VERSION ""

NS_ :

BS_:

BU_: WCM4 WCM3 WCM2 WCM VPM VLM VKM VICM VECM VDM VCU_RTOS_ETH VCU_ENTRY_ETH VCU_AGVM_ETH VCU UVM UPM TIM TEST_TOOL_1 TCP_ETH TCP TCM TCCM SRR_SRR_ETH SRR_SRR SRR_SLR_ETH SRR_SLR SRR_RR SRR_RF_ETH SRR_RF SRR_LR_CR SRR_LF_ETH SRR_LF SIB SDM SCL SBZA_R SBZA_L SBM SAM_RR SAM_RF SAM_LR SAM_LF SAM_BH SADS RadioLow_ETH RadioLow RSI_RTOS_ETH RSI RDCM PTM PLCM PFCM PDR_ETH PDR PCM PA ODS2 ODS NVM MTCM_R MTCM_L MSM_RR MSM_P MSM_LR MSM_D MSB2 MSB1 MRCM_R MRCM_L MFC LRR_RR_ETH LRR_LR_ETH LRR_CF_ETH LRR LRL_CF_ETH LIB_48V LIB1 IPC_INT IPC_GP IPC ICS_Info ICCM HVAC_FP_R HVAC_FP_F HUD_CAN HDLM FPI_RTOS_ETH FPI FOPM FCM_LC FCM EPSb EPS_1 EPSRAb EPSRAa EPS EOCM_HC_Superset EOCM_HCP2 EOCM ELM ECP_X1 ECP_S2 ECP_S ECP_MC ECP_H3 ECP_H2 ECP_H1 ECP_E ECM EBCM DMS DEFC DCM CSM_ETH CSM_AV CSM CGM_OTA_ETH CGM BSM_MH BSM_HEV BSM BCM ARS ARB APA AOS AMP ALC AHS AHL_AFL ADIMb ADIMa ACP2_MCU
VAL_TABLE_ EngEmsRltMlfIndRq 0 "Continuous Indication" 1 "No Indication" 2 "Flashing 1 Hertz Indication" 3 "Flashing 2 Hertz Indication" 4 "Flashing 0.5 Hertz Indication" ;
VAL_TABLE_ VSADP_VehSpdAvgDrvnSrcAuth 0 "Transmission Output Speed" 1 "Wheel Speed" ;
VAL_TABLE_ VSADP_VehSpdAvgDrvnAuth_Inv 0 "FALSE" 1 "TRUE" ;
VAL_TABLE_ VPMGI1P_ITAux2CamConctStsAuth 0 "Unknown" 1 "Not Connected" 2 "Connected" ;
VAL_TABLE_ VPMGI1P_ITAux1CamConctStsAuth 0 "Unknown" 1 "Not Connected" 2 "Connected" ;

BO_ 925 APASts_PCSM_PDU: 8 CGM
 SG_ APASts_PCSM : 0|64@1+ (1,0) [0|1.84467e+019] "" VKM

BO_ 525 APASts_Prtctd_PDU: 8 CGM
 SG_ APASP_MAC : 7|27@0+ (1,0) [0|1.34218e+008] "" VKM
 SG_ APASP_FCnt : 28|5@0+ (1,0) [0|31] "" VKM
 SG_ APASP_APAStopDistAuth : 32|14@0- (1,0) [-8192|8191] "cm" VKM
 SG_ APASP_APAMaxVelAuth : 39|7@0+ (0.1,0) [0|12.7] "km/h" VKM
 SG_ APASP_APAStsAuth : 50|3@0+ (1,0) [0|7] "" VKM
 SG_ APASP_ARC : 59|2@0+ (1,0) [0|3] "" VKM
 SG_ APASP_APATransRngReqAuth : 62|3@0+ (1,0) [0|4] "" VKM
 SG_ APASP_APATransRngActvnReqdAuth : 63|1@0+ (1,0) [0|1] "" VKM

BO_ 1393 ActvSftyOprtrCrtclNtfns_PCSM_PDU: 8 CGM
 SG_ ActvSftyOprtrCrtclNtfns_PCSM : 0|64@1+ (1,0) [0|1.84467e+019] "" IPC,IPC_INT,VCU

BO_ 1325 ActvSftyOprtrCrtclNtfns_Prtctd_P: 8 CGM
 SG_ ASOCNP_MAC : 7|27@0+ (1,0) [0|1.34218e+008] "" IPC,IPC_INT,VCU
 SG_ ASOCNP_FCnt : 28|5@0+ (1,0) [0|31] "" IPC,IPC_INT,VCU
 SG_ HndsOnLnCntrAsstWrnIndReq : 32|4@0+ (1,0) [0|6] "" IPC,IPC_INT,VCU
 SG_ SuprRmtPrkPwrModeReq : 34|2@0+ (1,0) [0|2] "" IPC,IPC_INT,VCU
 SG_ SuprRmtPrkDrLckReq : 36|2@0+ (1,0) [0|2] "" IPC,IPC_INT,VCU
 SG_ ASOCNP_ARC : 38|2@0+ (1,0) [0|3] "" IPC,IPC_INT,VCU
 SG_ ASOCNP_LKATakeStrgIndOnAuth : 39|1@0+ (1,0) [0|1] "" TCP,CSM,CSM_AV,IPC,IPC_INT,VCU
 SG_ ASOCNP_Filler : 44|21@0+ (1,0) [0|2.09715e+006] "" IPC,IPC_INT,VCU

BO_ 618 BdyGenInfo2_Prtctd_PDU: 8 CGM
 SG_ BGI2P_WshFldLvlIndOnAuth : 36|1@0+ (1,0) [0|1] "" TCP,CSM,CSM_AV,IPC,IPC_INT,VCU
 SG_ BGI2P_ServWprSysDrvIndOnAuth : 38|1@0+ (1,0) [0|1] "" IPC,IPC_INT,VCU

BO_ 1405 BkupSysPwrMode_PCSM_PDU: 8 CGM
 SG_ BkupSysPwrMode_PCSM : 0|64@1+ (1,0) [0|1.84467e+019] "" TCP,VKM,IPC,IPC_INT,VCU

BO_ 880 BkupSysPwrMode_Prtctd_PDU: 6 CGM
 SG_ BSPMP_MAC : 7|27@0+ (1,0) [0|1.34218e+008] "" TCP,VKM,IPC,IPC_INT,VCU
 SG_ BSPMP_FCnt : 28|5@0+ (1,0) [0|31] "" TCP,VKM,IPC,IPC_INT,VCU
 SG_ BSPMP_PV : 35|4@0+ (1,0) [0|15] "" HVAC_FP_R,TCP,VKM,IPC,IPC_INT,VCU
 SG_ BSPMP_BkupSysPwrModeAuth_Inv : 36|1@0+ (1,0) [0|1] "" AMP,FPI,HVAC_FP_F,HVAC_FP_R,ICS_Info,PDR,MFC,PLCM,RSI,RadioLow,TCP,VKM,CSM,CSM_AV,IPC,IPC_INT,VCU,WCM,WCM2,WCM3,WCM4
 SG_ BSPMP_BkupSysPwrModeAuth : 39|3@0+ (1,0) [0|4] "" AMP,FPI,HVAC_FP_F,HVAC_FP_R,ICS_Info,PDR,MFC,PLCM,RSI,RadioLow,TCP,VKM,CSM,CSM_AV,IPC,IPC_INT,VCU,WCM,WCM2,WCM3,WCM4
 SG_ BSPMP_ARC : 42|2@0+ (1,0) [0|3] "" HVAC_FP_R,TCP,VKM,IPC,IPC_INT,VCU
 SG_ BSPMP_SecRunCrnkCmdActvAuth_Inv : 43|1@0+ (1,0) [0|1] "" TCP,VKM,IPC,IPC_INT,VCU
 SG_ BSPMP_SecRunCrnkCmdActvAuth : 44|1@0+ (1,0) [0|1] "" TCP,VKM,IPC,IPC_INT,VCU
 SG_ BSPMP_SecPwrModePBActvAuth_Inv : 45|1@0+ (1,0) [0|1] "" TCP,VKM,IPC,IPC_INT,VCU
 SG_ BSPMP_SecPwrModePBActvAuth : 46|1@0+ (1,0) [0|1] "" TCP,VKM,IPC,IPC_INT,VCU
 SG_ BSPMP_RmtProgmActvAuth : 47|1@0+ (1,0) [0|1] "" AMP,FPI,HVAC_FP_F,HVAC_FP_R,ICS_Info,PDR,MFC,PLCM,RSI,RadioLow,TCP,VKM,CSM,CSM_AV,IPC,IPC_INT,VCU,WCM,WCM2,WCM3,WCM4

BO_ 1366 BrkSysDispInfo_PCSM_PDU: 8 CGM
 SG_ BrkSysDispInfo_PCSM : 0|64@1+ (1,0) [0|1.84467e+019] "" IPC,IPC_INT,VCU

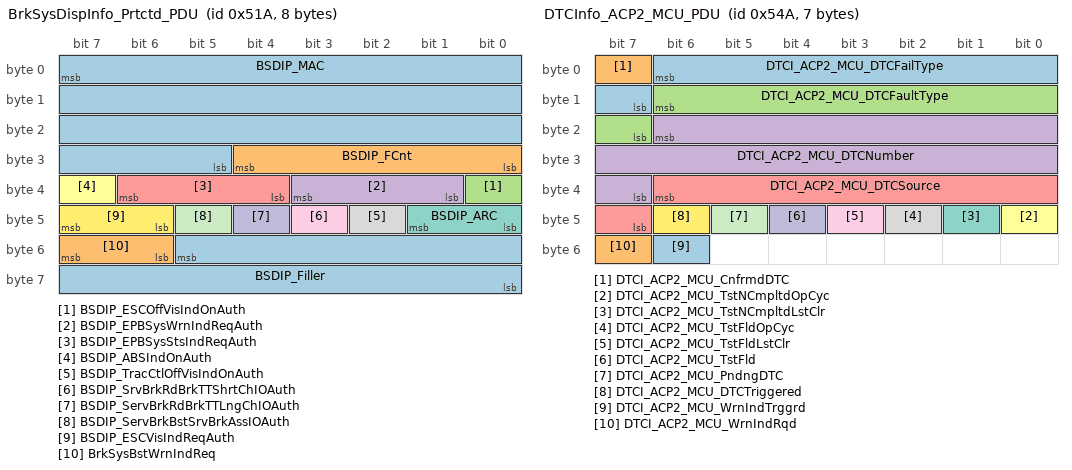
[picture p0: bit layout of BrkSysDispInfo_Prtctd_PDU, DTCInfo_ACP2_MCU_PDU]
BO_ 1306 BrkSysDispInfo_Prtctd_PDU: 8 CGM
 SG_ BSDIP_MAC : 7|27@0+ (1,0) [0|1.34218e+008] "" IPC,IPC_INT,VCU
 SG_ BSDIP_FCnt : 28|5@0+ (1,0) [0|31] "" IPC,IPC_INT,VCU
 SG_ BSDIP_ESCOffVisIndOnAuth : 32|1@0+ (1,0) [0|1] "" IPC,IPC_INT,VCU
 SG_ BSDIP_EPBSysWrnIndReqAuth : 35|3@0+ (1,0) [0|5] "" CSM,CSM_AV,IPC,IPC_INT,VCU
 SG_ BSDIP_EPBSysStsIndReqAuth : 38|3@0+ (1,0) [0|5] "" CSM,CSM_AV,IPC,IPC_INT,VCU
 SG_ BSDIP_ABSIndOnAuth : 39|1@0+ (1,0) [0|1] "" TCP,CSM,CSM_AV,IPC,IPC_INT,VCU
 SG_ BSDIP_ARC : 41|2@0+ (1,0) [0|3] "" IPC,IPC_INT,VCU
 SG_ BSDIP_TracCtlOffVisIndOnAuth : 42|1@0+ (1,0) [0|1] "" TCP,IPC,IPC_INT,VCU
 SG_ BSDIP_SrvBrkRdBrkTTShrtChIOAuth : 43|1@0+ (1,0) [0|1] "" TCP,IPC,IPC_INT,VCU
 SG_ BSDIP_ServBrkRdBrkTTLngChIOAuth : 44|1@0+ (1,0) [0|1] "" TCP,IPC,IPC_INT,VCU
 SG_ BSDIP_ServBrkBstSrvBrkAssIOAuth : 45|1@0+ (1,0) [0|1] "" TCP,IPC,IPC_INT,VCU
 SG_ BSDIP_ESCVisIndReqAuth : 47|2@0+ (1,0) [0|2] "" TCP,IPC,IPC_INT,VCU
 SG_ BSDIP_Filler : 53|14@0+ (1,0) [0|16383] "" IPC,IPC_INT,VCU
 SG_ BrkSysBstWrnIndReq : 55|2@0+ (1,0) [0|3] "" IPC,IPC_INT,VCU

BO_ 327 CGM_NM_PDU_On_CAN_5_Cluster: 8 CGM
 SG_ ISignal_CGM_CAN_5_Cluster : 23|48@0+ (1,0) [0|281474976710655] "" AMP,FPI,HVAC_FP_F,HVAC_FP_R,ICS_Info,PDR,MFC,PLCM,RSI,RadioLow,TCP,VKM,CSM,CSM_AV,IPC,IPC_INT,VCU,WCM,WCM2,WCM3,WCM4

BO_ 384 CSM_AV_NM_PDU_On_CAN_5_Cluster: 8 CSM_AV
 SG_ ISignal_CSM_AV_CAN_5_Cluster : 23|48@0+ (1,0) [0|281474976710655] "" AMP,CGM,FPI,HVAC_FP_F,HVAC_FP_R,ICS_Info,PDR,MFC,PLCM,RSI,RadioLow,TCP,VKM,CSM,IPC,IPC_INT,VCU,WCM,WCM2,WCM3,WCM4

BO_ 1446 ChmReqInfo_PDU: 8 IPC
 SG_ CRI_ChmPrdcrReq : 7|12@0+ (1,0) [0|4095] "msec" AMP,RadioLow,CSM,CSM_AV
 SG_ CRI_CS : 50|11@0+ (1,0) [0|2047] "" AMP,RadioLow,CSM,CSM_AV
 SG_ CRI_ARC : 55|2@0+ (1,0) [0|3] "" AMP,RadioLow,CSM,CSM_AV

BO_ 1354 DTCInfo_ACP2_MCU_PDU: 7 CGM
 SG_ DTCI_ACP2_MCU_DTCFailType : 6|8@0+ (1,0) [0|255] "" TCP
 SG_ DTCI_ACP2_MCU_CnfrmdDTC : 7|1@0+ (1,0) [0|1] "" TCP
 SG_ DTCI_ACP2_MCU_DTCFaultType : 14|8@0+ (1,0) [0|3] "" TCP
 SG_ DTCI_ACP2_MCU_DTCNumber : 22|16@0+ (1,0) [0|65535] "" TCP
 SG_ DTCI_ACP2_MCU_DTCSource : 38|8@0+ (1,0) [0|255] "" TCP
 SG_ DTCI_ACP2_MCU_TstNCmpltdOpCyc : 40|1@0+ (1,0) [0|1] "" TCP
 SG_ DTCI_ACP2_MCU_TstNCmpltdLstClr : 41|1@0+ (1,0) [0|1] "" TCP
 SG_ DTCI_ACP2_MCU_TstFldOpCyc : 42|1@0+ (1,0) [0|1] "" TCP
 SG_ DTCI_ACP2_MCU_TstFldLstClr : 43|1@0+ (1,0) [0|1] "" TCP
 SG_ DTCI_ACP2_MCU_TstFld : 44|1@0+ (1,0) [0|1] "" TCP
 SG_ DTCI_ACP2_MCU_PndngDTC : 45|1@0+ (1,0) [0|1] "" TCP
 SG_ DTCI_ACP2_MCU_DTCTriggered : 46|1@0+ (1,0) [0|1] "" TCP
 SG_ DTCI_ACP2_MCU_WrnIndTrggrd : 54|1@0+ (1,0) [0|1] "" TCP
 SG_ DTCI_ACP2_MCU_WrnIndRqd : 55|1@0+ (1,0) [0|1] "" TCP

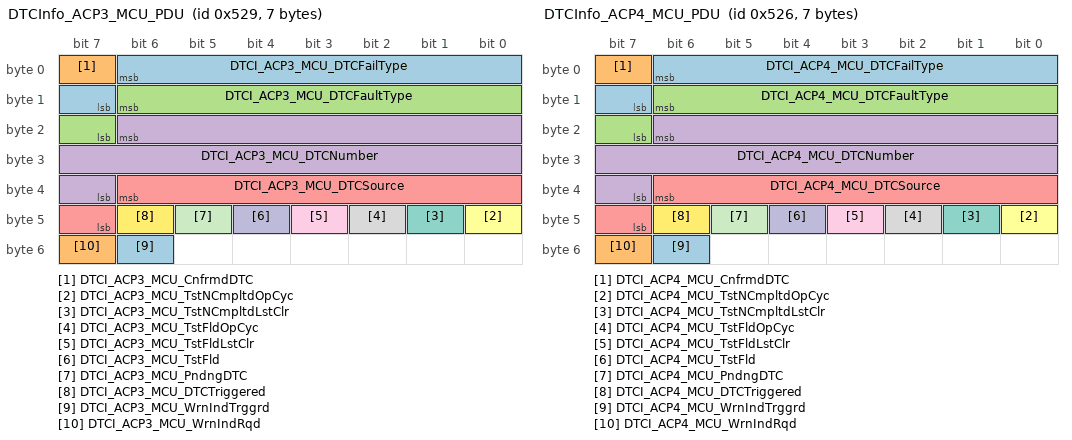
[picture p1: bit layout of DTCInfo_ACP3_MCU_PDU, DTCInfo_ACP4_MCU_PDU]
BO_ 1321 DTCInfo_ACP3_MCU_PDU: 7 CGM
 SG_ DTCI_ACP3_MCU_DTCFailType : 6|8@0+ (1,0) [0|255] "" TCP
 SG_ DTCI_ACP3_MCU_CnfrmdDTC : 7|1@0+ (1,0) [0|1] "" TCP
 SG_ DTCI_ACP3_MCU_DTCFaultType : 14|8@0+ (1,0) [0|3] "" TCP
 SG_ DTCI_ACP3_MCU_DTCNumber : 22|16@0+ (1,0) [0|65535] "" TCP
 SG_ DTCI_ACP3_MCU_DTCSource : 38|8@0+ (1,0) [0|255] "" TCP
 SG_ DTCI_ACP3_MCU_TstNCmpltdOpCyc : 40|1@0+ (1,0) [0|1] "" TCP
 SG_ DTCI_ACP3_MCU_TstNCmpltdLstClr : 41|1@0+ (1,0) [0|1] "" TCP
 SG_ DTCI_ACP3_MCU_TstFldOpCyc : 42|1@0+ (1,0) [0|1] "" TCP
 SG_ DTCI_ACP3_MCU_TstFldLstClr : 43|1@0+ (1,0) [0|1] "" TCP
 SG_ DTCI_ACP3_MCU_TstFld : 44|1@0+ (1,0) [0|1] "" TCP
 SG_ DTCI_ACP3_MCU_PndngDTC : 45|1@0+ (1,0) [0|1] "" TCP
 SG_ DTCI_ACP3_MCU_DTCTriggered : 46|1@0+ (1,0) [0|1] "" TCP
 SG_ DTCI_ACP3_MCU_WrnIndTrggrd : 54|1@0+ (1,0) [0|1] "" TCP
 SG_ DTCI_ACP3_MCU_WrnIndRqd : 55|1@0+ (1,0) [0|1] "" TCP

BO_ 1318 DTCInfo_ACP4_MCU_PDU: 7 CGM
 SG_ DTCI_ACP4_MCU_DTCFailType : 6|8@0+ (1,0) [0|255] "" TCP
 SG_ DTCI_ACP4_MCU_CnfrmdDTC : 7|1@0+ (1,0) [0|1] "" TCP
 SG_ DTCI_ACP4_MCU_DTCFaultType : 14|8@0+ (1,0) [0|3] "" TCP
 SG_ DTCI_ACP4_MCU_DTCNumber : 22|16@0+ (1,0) [0|65535] "" TCP
 SG_ DTCI_ACP4_MCU_DTCSource : 38|8@0+ (1,0) [0|255] "" TCP
 SG_ DTCI_ACP4_MCU_TstNCmpltdOpCyc : 40|1@0+ (1,0) [0|1] "" TCP
 SG_ DTCI_ACP4_MCU_TstNCmpltdLstClr : 41|1@0+ (1,0) [0|1] "" TCP
 SG_ DTCI_ACP4_MCU_TstFldOpCyc : 42|1@0+ (1,0) [0|1] "" TCP
 SG_ DTCI_ACP4_MCU_TstFldLstClr : 43|1@0+ (1,0) [0|1] "" TCP
 SG_ DTCI_ACP4_MCU_TstFld : 44|1@0+ (1,0) [0|1] "" TCP
 SG_ DTCI_ACP4_MCU_PndngDTC : 45|1@0+ (1,0) [0|1] "" TCP
 SG_ DTCI_ACP4_MCU_DTCTriggered : 46|1@0+ (1,0) [0|1] "" TCP
 SG_ DTCI_ACP4_MCU_WrnIndTrggrd : 54|1@0+ (1,0) [0|1] "" TCP
 SG_ DTCI_ACP4_MCU_WrnIndRqd : 55|1@0+ (1,0) [0|1] "" TCP

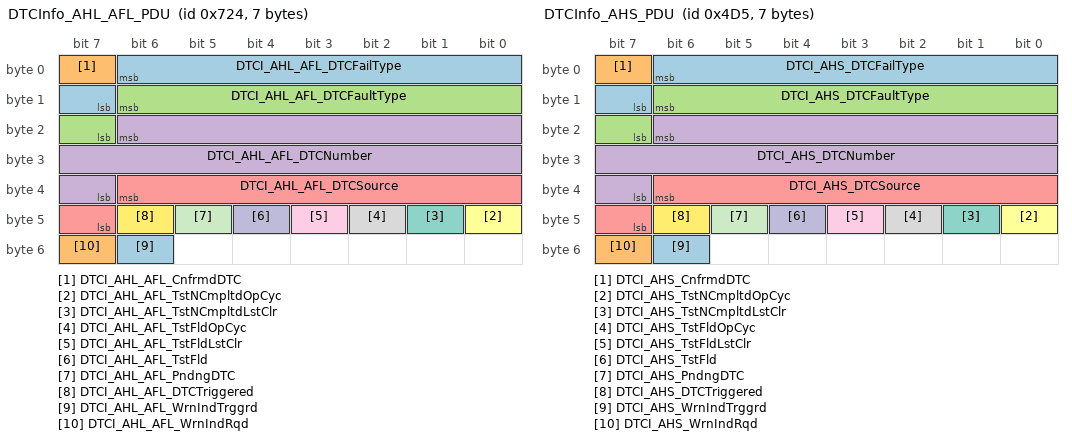
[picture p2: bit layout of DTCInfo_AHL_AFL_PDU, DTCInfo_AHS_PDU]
BO_ 1828 DTCInfo_AHL_AFL_PDU: 7 CGM
 SG_ DTCI_AHL_AFL_DTCFailType : 6|8@0+ (1,0) [0|255] "" TCP,CSM
 SG_ DTCI_AHL_AFL_CnfrmdDTC : 7|1@0+ (1,0) [0|1] "" TCP,CSM
 SG_ DTCI_AHL_AFL_DTCFaultType : 14|8@0+ (1,0) [0|3] "" TCP,CSM
 SG_ DTCI_AHL_AFL_DTCNumber : 22|16@0+ (1,0) [0|65535] "" TCP,CSM
 SG_ DTCI_AHL_AFL_DTCSource : 38|8@0+ (1,0) [0|255] "" TCP,CSM
 SG_ DTCI_AHL_AFL_TstNCmpltdOpCyc : 40|1@0+ (1,0) [0|1] "" TCP,CSM
 SG_ DTCI_AHL_AFL_TstNCmpltdLstClr : 41|1@0+ (1,0) [0|1] "" TCP,CSM
 SG_ DTCI_AHL_AFL_TstFldOpCyc : 42|1@0+ (1,0) [0|1] "" TCP,CSM
 SG_ DTCI_AHL_AFL_TstFldLstClr : 43|1@0+ (1,0) [0|1] "" TCP,CSM
 SG_ DTCI_AHL_AFL_TstFld : 44|1@0+ (1,0) [0|1] "" TCP,CSM
 SG_ DTCI_AHL_AFL_PndngDTC : 45|1@0+ (1,0) [0|1] "" TCP,CSM
 SG_ DTCI_AHL_AFL_DTCTriggered : 46|1@0+ (1,0) [0|1] "" TCP,CSM
 SG_ DTCI_AHL_AFL_WrnIndTrggrd : 54|1@0+ (1,0) [0|1] "" TCP,CSM
 SG_ DTCI_AHL_AFL_WrnIndRqd : 55|1@0+ (1,0) [0|1] "" TCP,CSM

BO_ 1237 DTCInfo_AHS_PDU: 7 CGM
 SG_ DTCI_AHS_DTCFailType : 6|8@0+ (1,0) [0|255] "" TCP
 SG_ DTCI_AHS_CnfrmdDTC : 7|1@0+ (1,0) [0|1] "" TCP
 SG_ DTCI_AHS_DTCFaultType : 14|8@0+ (1,0) [0|3] "" TCP
 SG_ DTCI_AHS_DTCNumber : 22|16@0+ (1,0) [0|65535] "" TCP
 SG_ DTCI_AHS_DTCSource : 38|8@0+ (1,0) [0|255] "" TCP
 SG_ DTCI_AHS_TstNCmpltdOpCyc : 40|1@0+ (1,0) [0|1] "" TCP
 SG_ DTCI_AHS_TstNCmpltdLstClr : 41|1@0+ (1,0) [0|1] "" TCP
 SG_ DTCI_AHS_TstFldOpCyc : 42|1@0+ (1,0) [0|1] "" TCP
 SG_ DTCI_AHS_TstFldLstClr : 43|1@0+ (1,0) [0|1] "" TCP
 SG_ DTCI_AHS_TstFld : 44|1@0+ (1,0) [0|1] "" TCP
 SG_ DTCI_AHS_PndngDTC : 45|1@0+ (1,0) [0|1] "" TCP
 SG_ DTCI_AHS_DTCTriggered : 46|1@0+ (1,0) [0|1] "" TCP
 SG_ DTCI_AHS_WrnIndTrggrd : 54|1@0+ (1,0) [0|1] "" TCP
 SG_ DTCI_AHS_WrnIndRqd : 55|1@0+ (1,0) [0|1] "" TCP

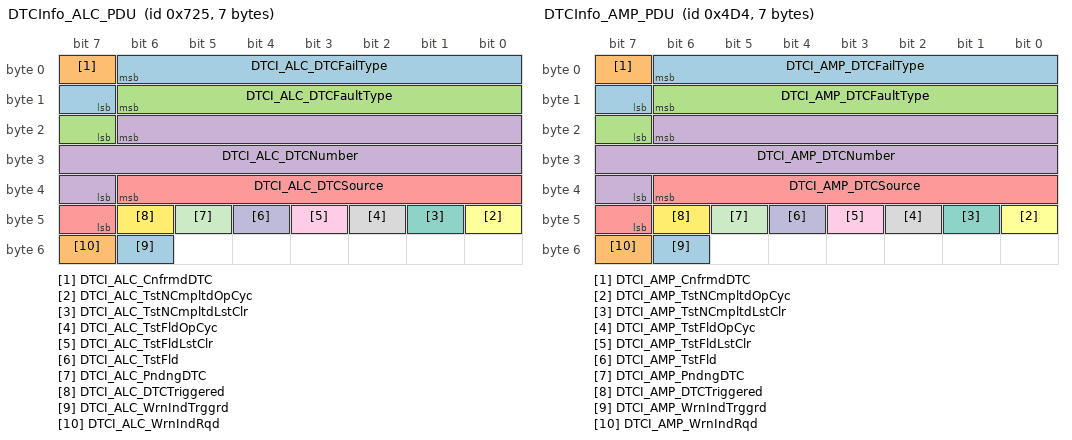
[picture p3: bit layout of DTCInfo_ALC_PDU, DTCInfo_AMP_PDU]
BO_ 1829 DTCInfo_ALC_PDU: 7 CGM
 SG_ DTCI_ALC_DTCFailType : 6|8@0+ (1,0) [0|255] "" TCP,CSM
 SG_ DTCI_ALC_CnfrmdDTC : 7|1@0+ (1,0) [0|1] "" TCP,CSM
 SG_ DTCI_ALC_DTCFaultType : 14|8@0+ (1,0) [0|3] "" TCP,CSM
 SG_ DTCI_ALC_DTCNumber : 22|16@0+ (1,0) [0|65535] "" TCP,CSM
 SG_ DTCI_ALC_DTCSource : 38|8@0+ (1,0) [0|255] "" TCP,CSM
 SG_ DTCI_ALC_TstNCmpltdOpCyc : 40|1@0+ (1,0) [0|1] "" TCP,CSM
 SG_ DTCI_ALC_TstNCmpltdLstClr : 41|1@0+ (1,0) [0|1] "" TCP,CSM
 SG_ DTCI_ALC_TstFldOpCyc : 42|1@0+ (1,0) [0|1] "" TCP,CSM
 SG_ DTCI_ALC_TstFldLstClr : 43|1@0+ (1,0) [0|1] "" TCP,CSM
 SG_ DTCI_ALC_TstFld : 44|1@0+ (1,0) [0|1] "" TCP,CSM
 SG_ DTCI_ALC_PndngDTC : 45|1@0+ (1,0) [0|1] "" TCP,CSM
 SG_ DTCI_ALC_DTCTriggered : 46|1@0+ (1,0) [0|1] "" TCP,CSM
 SG_ DTCI_ALC_WrnIndTrggrd : 54|1@0+ (1,0) [0|1] "" TCP,CSM
 SG_ DTCI_ALC_WrnIndRqd : 55|1@0+ (1,0) [0|1] "" TCP,CSM

BO_ 1236 DTCInfo_AMP_PDU: 7 AMP
 SG_ DTCI_AMP_DTCFailType : 6|8@0+ (1,0) [0|255] "" TCP,CSM
 SG_ DTCI_AMP_CnfrmdDTC : 7|1@0+ (1,0) [0|1] "" TCP,CSM
 SG_ DTCI_AMP_DTCFaultType : 14|8@0+ (1,0) [0|3] "" TCP,CSM
 SG_ DTCI_AMP_DTCNumber : 22|16@0+ (1,0) [0|65535] "" TCP,CSM
 SG_ DTCI_AMP_DTCSource : 38|8@0+ (1,0) [0|255] "" CGM,TCP,CSM
 SG_ DTCI_AMP_TstNCmpltdOpCyc : 40|1@0+ (1,0) [0|1] "" TCP,CSM
 SG_ DTCI_AMP_TstNCmpltdLstClr : 41|1@0+ (1,0) [0|1] "" TCP,CSM
 SG_ DTCI_AMP_TstFldOpCyc : 42|1@0+ (1,0) [0|1] "" TCP,CSM
 SG_ DTCI_AMP_TstFldLstClr : 43|1@0+ (1,0) [0|1] "" TCP,CSM
 SG_ DTCI_AMP_TstFld : 44|1@0+ (1,0) [0|1] "" TCP,CSM
 SG_ DTCI_AMP_PndngDTC : 45|1@0+ (1,0) [0|1] "" TCP,CSM
 SG_ DTCI_AMP_DTCTriggered : 46|1@0+ (1,0) [0|1] "" TCP,CSM
 SG_ DTCI_AMP_WrnIndTrggrd : 54|1@0+ (1,0) [0|1] "" TCP,CSM
 SG_ DTCI_AMP_WrnIndRqd : 55|1@0+ (1,0) [0|1] "" TCP,CSM

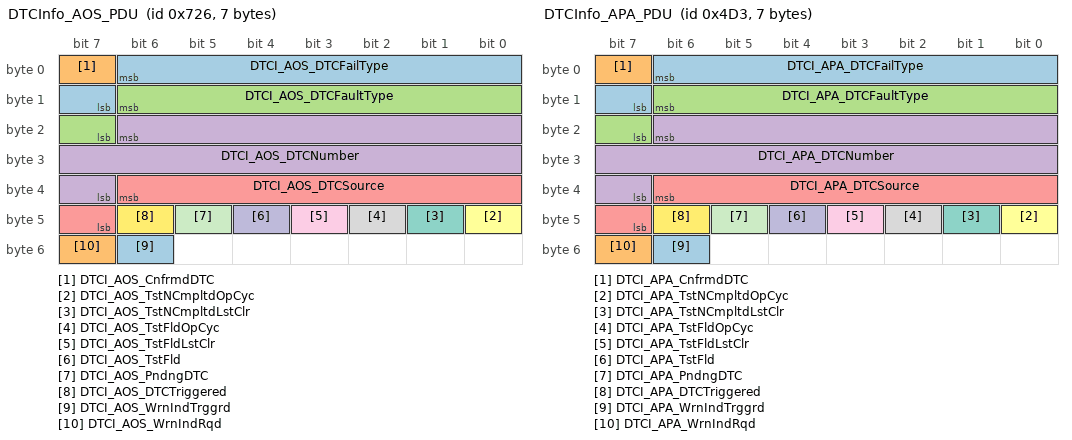
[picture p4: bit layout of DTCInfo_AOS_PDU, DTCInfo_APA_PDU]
BO_ 1830 DTCInfo_AOS_PDU: 7 CGM
 SG_ DTCI_AOS_DTCFailType : 6|8@0+ (1,0) [0|255] "" TCP,CSM
 SG_ DTCI_AOS_CnfrmdDTC : 7|1@0+ (1,0) [0|1] "" TCP,CSM
 SG_ DTCI_AOS_DTCFaultType : 14|8@0+ (1,0) [0|3] "" TCP,CSM
 SG_ DTCI_AOS_DTCNumber : 22|16@0+ (1,0) [0|65535] "" TCP,CSM
 SG_ DTCI_AOS_DTCSource : 38|8@0+ (1,0) [0|255] "" TCP,CSM
 SG_ DTCI_AOS_TstNCmpltdOpCyc : 40|1@0+ (1,0) [0|1] "" TCP,CSM
 SG_ DTCI_AOS_TstNCmpltdLstClr : 41|1@0+ (1,0) [0|1] "" TCP,CSM
 SG_ DTCI_AOS_TstFldOpCyc : 42|1@0+ (1,0) [0|1] "" TCP,CSM
 SG_ DTCI_AOS_TstFldLstClr : 43|1@0+ (1,0) [0|1] "" TCP,CSM
 SG_ DTCI_AOS_TstFld : 44|1@0+ (1,0) [0|1] "" TCP,CSM
 SG_ DTCI_AOS_PndngDTC : 45|1@0+ (1,0) [0|1] "" TCP,CSM
 SG_ DTCI_AOS_DTCTriggered : 46|1@0+ (1,0) [0|1] "" TCP,CSM
 SG_ DTCI_AOS_WrnIndTrggrd : 54|1@0+ (1,0) [0|1] "" TCP,CSM
 SG_ DTCI_AOS_WrnIndRqd : 55|1@0+ (1,0) [0|1] "" TCP,CSM

BO_ 1235 DTCInfo_APA_PDU: 7 CGM
 SG_ DTCI_APA_DTCFailType : 6|8@0+ (1,0) [0|255] "" TCP,CSM
 SG_ DTCI_APA_CnfrmdDTC : 7|1@0+ (1,0) [0|1] "" TCP,CSM
 SG_ DTCI_APA_DTCFaultType : 14|8@0+ (1,0) [0|3] "" TCP,CSM
 SG_ DTCI_APA_DTCNumber : 22|16@0+ (1,0) [0|65535] "" TCP,CSM
 SG_ DTCI_APA_DTCSource : 38|8@0+ (1,0) [0|255] "" TCP,CSM
 SG_ DTCI_APA_TstNCmpltdOpCyc : 40|1@0+ (1,0) [0|1] "" TCP,CSM
 SG_ DTCI_APA_TstNCmpltdLstClr : 41|1@0+ (1,0) [0|1] "" TCP,CSM
 SG_ DTCI_APA_TstFldOpCyc : 42|1@0+ (1,0) [0|1] "" TCP,CSM
 SG_ DTCI_APA_TstFldLstClr : 43|1@0+ (1,0) [0|1] "" TCP,CSM
 SG_ DTCI_APA_TstFld : 44|1@0+ (1,0) [0|1] "" TCP,CSM
 SG_ DTCI_APA_PndngDTC : 45|1@0+ (1,0) [0|1] "" TCP,CSM
 SG_ DTCI_APA_DTCTriggered : 46|1@0+ (1,0) [0|1] "" TCP,CSM
 SG_ DTCI_APA_WrnIndTrggrd : 54|1@0+ (1,0) [0|1] "" TCP,CSM
 SG_ DTCI_APA_WrnIndRqd : 55|1@0+ (1,0) [0|1] "" TCP,CSM

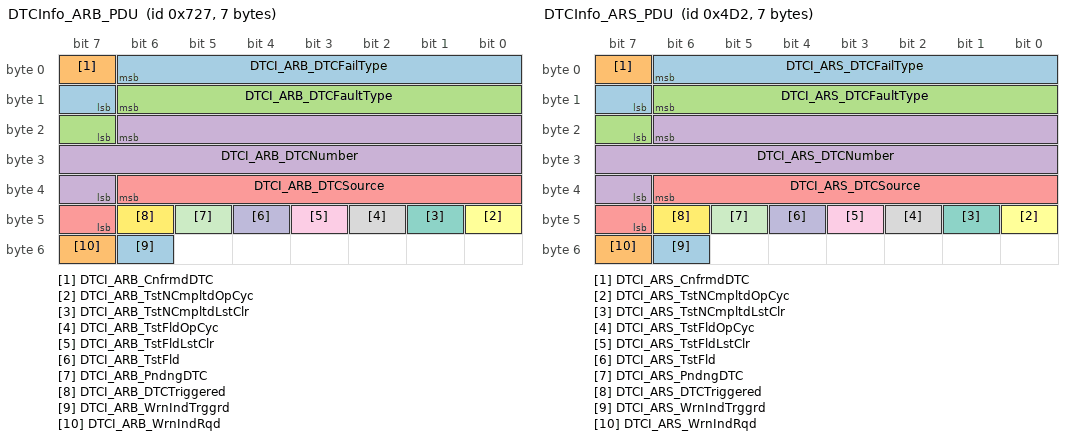
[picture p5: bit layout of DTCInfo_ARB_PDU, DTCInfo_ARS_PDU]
BO_ 1831 DTCInfo_ARB_PDU: 7 CGM
 SG_ DTCI_ARB_DTCFailType : 6|8@0+ (1,0) [0|255] "" TCP,CSM
 SG_ DTCI_ARB_CnfrmdDTC : 7|1@0+ (1,0) [0|1] "" TCP,CSM
 SG_ DTCI_ARB_DTCFaultType : 14|8@0+ (1,0) [0|3] "" TCP,CSM
 SG_ DTCI_ARB_DTCNumber : 22|16@0+ (1,0) [0|65535] "" TCP,CSM
 SG_ DTCI_ARB_DTCSource : 38|8@0+ (1,0) [0|255] "" TCP,CSM
 SG_ DTCI_ARB_TstNCmpltdOpCyc : 40|1@0+ (1,0) [0|1] "" TCP,CSM
 SG_ DTCI_ARB_TstNCmpltdLstClr : 41|1@0+ (1,0) [0|1] "" TCP,CSM
 SG_ DTCI_ARB_TstFldOpCyc : 42|1@0+ (1,0) [0|1] "" TCP,CSM
 SG_ DTCI_ARB_TstFldLstClr : 43|1@0+ (1,0) [0|1] "" TCP,CSM
 SG_ DTCI_ARB_TstFld : 44|1@0+ (1,0) [0|1] "" TCP,CSM
 SG_ DTCI_ARB_PndngDTC : 45|1@0+ (1,0) [0|1] "" TCP,CSM
 SG_ DTCI_ARB_DTCTriggered : 46|1@0+ (1,0) [0|1] "" TCP,CSM
 SG_ DTCI_ARB_WrnIndTrggrd : 54|1@0+ (1,0) [0|1] "" TCP,CSM
 SG_ DTCI_ARB_WrnIndRqd : 55|1@0+ (1,0) [0|1] "" TCP,CSM

BO_ 1234 DTCInfo_ARS_PDU: 7 CGM
 SG_ DTCI_ARS_DTCFailType : 6|8@0+ (1,0) [0|255] "" TCP,CSM
 SG_ DTCI_ARS_CnfrmdDTC : 7|1@0+ (1,0) [0|1] "" TCP,CSM
 SG_ DTCI_ARS_DTCFaultType : 14|8@0+ (1,0) [0|3] "" TCP,CSM
 SG_ DTCI_ARS_DTCNumber : 22|16@0+ (1,0) [0|65535] "" TCP,CSM
 SG_ DTCI_ARS_DTCSource : 38|8@0+ (1,0) [0|255] "" TCP,CSM
 SG_ DTCI_ARS_TstNCmpltdOpCyc : 40|1@0+ (1,0) [0|1] "" TCP,CSM
 SG_ DTCI_ARS_TstNCmpltdLstClr : 41|1@0+ (1,0) [0|1] "" TCP,CSM
 SG_ DTCI_ARS_TstFldOpCyc : 42|1@0+ (1,0) [0|1] "" TCP,CSM
 SG_ DTCI_ARS_TstFldLstClr : 43|1@0+ (1,0) [0|1] "" TCP,CSM
 SG_ DTCI_ARS_TstFld : 44|1@0+ (1,0) [0|1] "" TCP,CSM
 SG_ DTCI_ARS_PndngDTC : 45|1@0+ (1,0) [0|1] "" TCP,CSM
 SG_ DTCI_ARS_DTCTriggered : 46|1@0+ (1,0) [0|1] "" TCP,CSM
 SG_ DTCI_ARS_WrnIndTrggrd : 54|1@0+ (1,0) [0|1] "" TCP,CSM
 SG_ DTCI_ARS_WrnIndRqd : 55|1@0+ (1,0) [0|1] "" TCP,CSM

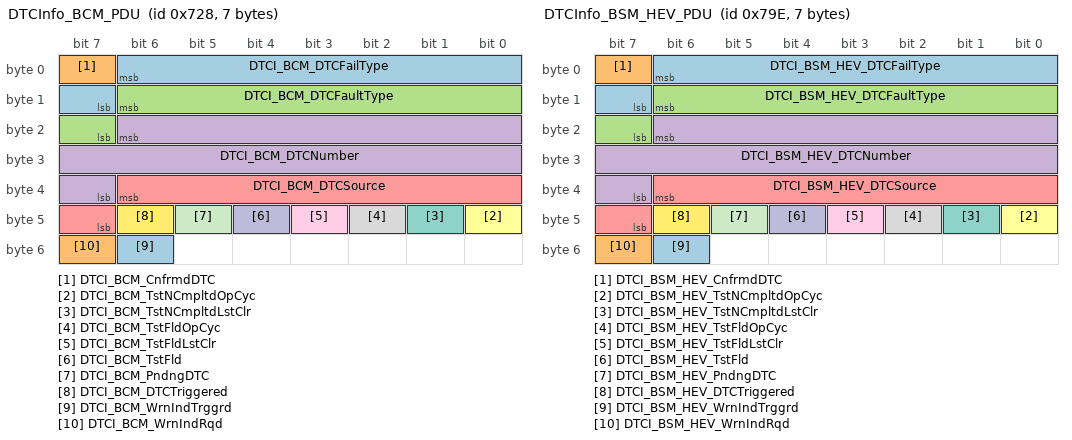
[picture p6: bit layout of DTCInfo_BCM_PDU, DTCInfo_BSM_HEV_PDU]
BO_ 1832 DTCInfo_BCM_PDU: 7 CGM
 SG_ DTCI_BCM_DTCFailType : 6|8@0+ (1,0) [0|255] "" TCP,CSM
 SG_ DTCI_BCM_CnfrmdDTC : 7|1@0+ (1,0) [0|1] "" TCP,CSM
 SG_ DTCI_BCM_DTCFaultType : 14|8@0+ (1,0) [0|3] "" TCP,CSM
 SG_ DTCI_BCM_DTCNumber : 22|16@0+ (1,0) [0|65535] "" TCP,CSM
 SG_ DTCI_BCM_DTCSource : 38|8@0+ (1,0) [0|255] "" TCP,CSM
 SG_ DTCI_BCM_TstNCmpltdOpCyc : 40|1@0+ (1,0) [0|1] "" TCP,CSM
 SG_ DTCI_BCM_TstNCmpltdLstClr : 41|1@0+ (1,0) [0|1] "" TCP,CSM
 SG_ DTCI_BCM_TstFldOpCyc : 42|1@0+ (1,0) [0|1] "" TCP,CSM
 SG_ DTCI_BCM_TstFldLstClr : 43|1@0+ (1,0) [0|1] "" TCP,CSM
 SG_ DTCI_BCM_TstFld : 44|1@0+ (1,0) [0|1] "" TCP,CSM
 SG_ DTCI_BCM_PndngDTC : 45|1@0+ (1,0) [0|1] "" TCP,CSM
 SG_ DTCI_BCM_DTCTriggered : 46|1@0+ (1,0) [0|1] "" TCP,CSM
 SG_ DTCI_BCM_WrnIndTrggrd : 54|1@0+ (1,0) [0|1] "" TCP,CSM
 SG_ DTCI_BCM_WrnIndRqd : 55|1@0+ (1,0) [0|1] "" TCP,CSM

BO_ 1950 DTCInfo_BSM_HEV_PDU: 7 CGM
 SG_ DTCI_BSM_HEV_DTCFailType : 6|8@0+ (1,0) [0|255] "" TCP
 SG_ DTCI_BSM_HEV_CnfrmdDTC : 7|1@0+ (1,0) [0|1] "" TCP
 SG_ DTCI_BSM_HEV_DTCFaultType : 14|8@0+ (1,0) [0|3] "" TCP
 SG_ DTCI_BSM_HEV_DTCNumber : 22|16@0+ (1,0) [0|65535] "" TCP
 SG_ DTCI_BSM_HEV_DTCSource : 38|8@0+ (1,0) [0|255] "" TCP
 SG_ DTCI_BSM_HEV_TstNCmpltdOpCyc : 40|1@0+ (1,0) [0|1] "" TCP
 SG_ DTCI_BSM_HEV_TstNCmpltdLstClr : 41|1@0+ (1,0) [0|1] "" TCP
 SG_ DTCI_BSM_HEV_TstFldOpCyc : 42|1@0+ (1,0) [0|1] "" TCP
 SG_ DTCI_BSM_HEV_TstFldLstClr : 43|1@0+ (1,0) [0|1] "" TCP
 SG_ DTCI_BSM_HEV_TstFld : 44|1@0+ (1,0) [0|1] "" TCP
 SG_ DTCI_BSM_HEV_PndngDTC : 45|1@0+ (1,0) [0|1] "" TCP
 SG_ DTCI_BSM_HEV_DTCTriggered : 46|1@0+ (1,0) [0|1] "" TCP
 SG_ DTCI_BSM_HEV_WrnIndTrggrd : 54|1@0+ (1,0) [0|1] "" TCP
 SG_ DTCI_BSM_HEV_WrnIndRqd : 55|1@0+ (1,0) [0|1] "" TCP

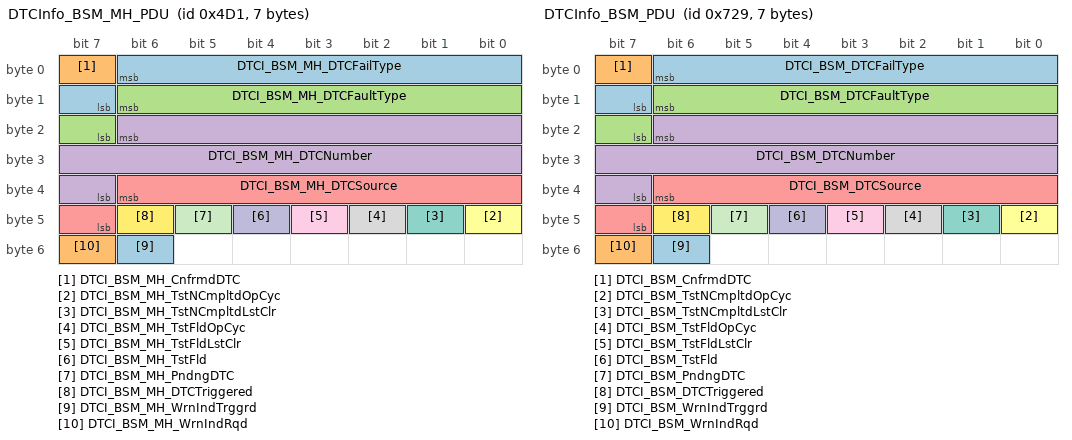
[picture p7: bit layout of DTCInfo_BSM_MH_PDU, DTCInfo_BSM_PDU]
BO_ 1233 DTCInfo_BSM_MH_PDU: 7 CGM
 SG_ DTCI_BSM_MH_DTCFailType : 6|8@0+ (1,0) [0|255] "" TCP,CSM
 SG_ DTCI_BSM_MH_CnfrmdDTC : 7|1@0+ (1,0) [0|1] "" TCP,CSM
 SG_ DTCI_BSM_MH_DTCFaultType : 14|8@0+ (1,0) [0|3] "" TCP,CSM
 SG_ DTCI_BSM_MH_DTCNumber : 22|16@0+ (1,0) [0|65535] "" TCP,CSM
 SG_ DTCI_BSM_MH_DTCSource : 38|8@0+ (1,0) [0|255] "" TCP,CSM
 SG_ DTCI_BSM_MH_TstNCmpltdOpCyc : 40|1@0+ (1,0) [0|1] "" TCP,CSM
 SG_ DTCI_BSM_MH_TstNCmpltdLstClr : 41|1@0+ (1,0) [0|1] "" TCP,CSM
 SG_ DTCI_BSM_MH_TstFldOpCyc : 42|1@0+ (1,0) [0|1] "" TCP,CSM
 SG_ DTCI_BSM_MH_TstFldLstClr : 43|1@0+ (1,0) [0|1] "" TCP,CSM
 SG_ DTCI_BSM_MH_TstFld : 44|1@0+ (1,0) [0|1] "" TCP,CSM
 SG_ DTCI_BSM_MH_PndngDTC : 45|1@0+ (1,0) [0|1] "" TCP,CSM
 SG_ DTCI_BSM_MH_DTCTriggered : 46|1@0+ (1,0) [0|1] "" TCP,CSM
 SG_ DTCI_BSM_MH_WrnIndTrggrd : 54|1@0+ (1,0) [0|1] "" TCP,CSM
 SG_ DTCI_BSM_MH_WrnIndRqd : 55|1@0+ (1,0) [0|1] "" TCP,CSM

BO_ 1833 DTCInfo_BSM_PDU: 7 CGM
 SG_ DTCI_BSM_DTCFailType : 6|8@0+ (1,0) [0|255] "" TCP,CSM
 SG_ DTCI_BSM_CnfrmdDTC : 7|1@0+ (1,0) [0|1] "" TCP,CSM
 SG_ DTCI_BSM_DTCFaultType : 14|8@0+ (1,0) [0|3] "" TCP,CSM
 SG_ DTCI_BSM_DTCNumber : 22|16@0+ (1,0) [0|65535] "" TCP,CSM
 SG_ DTCI_BSM_DTCSource : 38|8@0+ (1,0) [0|255] "" TCP,CSM
 SG_ DTCI_BSM_TstNCmpltdOpCyc : 40|1@0+ (1,0) [0|1] "" TCP,CSM
 SG_ DTCI_BSM_TstNCmpltdLstClr : 41|1@0+ (1,0) [0|1] "" TCP,CSM
 SG_ DTCI_BSM_TstFldOpCyc : 42|1@0+ (1,0) [0|1] "" TCP,CSM
 SG_ DTCI_BSM_TstFldLstClr : 43|1@0+ (1,0) [0|1] "" TCP,CSM
 SG_ DTCI_BSM_TstFld : 44|1@0+ (1,0) [0|1] "" TCP,CSM
 SG_ DTCI_BSM_PndngDTC : 45|1@0+ (1,0) [0|1] "" TCP,CSM
 SG_ DTCI_BSM_DTCTriggered : 46|1@0+ (1,0) [0|1] "" TCP,CSM
 SG_ DTCI_BSM_WrnIndTrggrd : 54|1@0+ (1,0) [0|1] "" TCP,CSM
 SG_ DTCI_BSM_WrnIndRqd : 55|1@0+ (1,0) [0|1] "" TCP,CSM

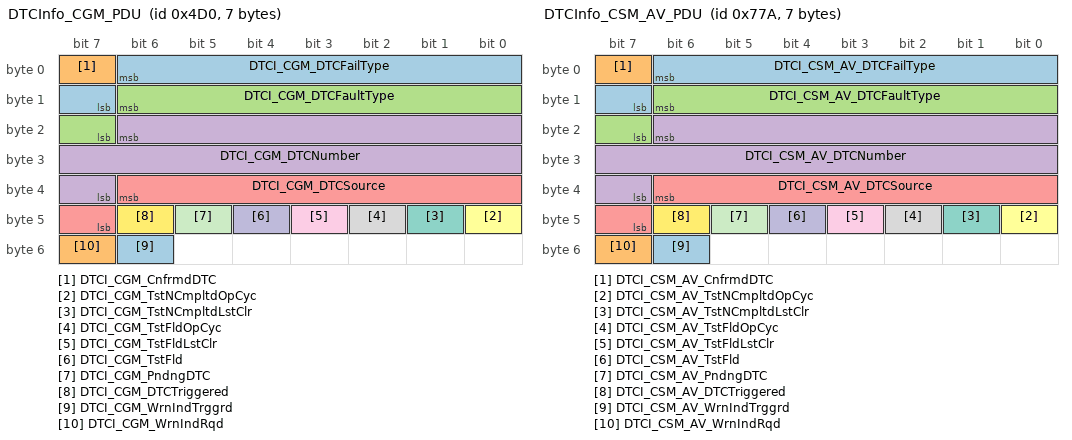
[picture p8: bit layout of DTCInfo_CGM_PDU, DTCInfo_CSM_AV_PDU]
BO_ 1232 DTCInfo_CGM_PDU: 7 CGM
 SG_ DTCI_CGM_DTCFailType : 6|8@0+ (1,0) [0|255] "" TCP,CSM
 SG_ DTCI_CGM_CnfrmdDTC : 7|1@0+ (1,0) [0|1] "" TCP,CSM
 SG_ DTCI_CGM_DTCFaultType : 14|8@0+ (1,0) [0|3] "" TCP,CSM
 SG_ DTCI_CGM_DTCNumber : 22|16@0+ (1,0) [0|65535] "" TCP,CSM
 SG_ DTCI_CGM_DTCSource : 38|8@0+ (1,0) [0|255] "" TCP,CSM
 SG_ DTCI_CGM_TstNCmpltdOpCyc : 40|1@0+ (1,0) [0|1] "" TCP,CSM
 SG_ DTCI_CGM_TstNCmpltdLstClr : 41|1@0+ (1,0) [0|1] "" TCP,CSM
 SG_ DTCI_CGM_TstFldOpCyc : 42|1@0+ (1,0) [0|1] "" TCP,CSM
 SG_ DTCI_CGM_TstFldLstClr : 43|1@0+ (1,0) [0|1] "" TCP,CSM
 SG_ DTCI_CGM_TstFld : 44|1@0+ (1,0) [0|1] "" TCP,CSM
 SG_ DTCI_CGM_PndngDTC : 45|1@0+ (1,0) [0|1] "" TCP,CSM
 SG_ DTCI_CGM_DTCTriggered : 46|1@0+ (1,0) [0|1] "" TCP,CSM
 SG_ DTCI_CGM_WrnIndTrggrd : 54|1@0+ (1,0) [0|1] "" TCP,CSM
 SG_ DTCI_CGM_WrnIndRqd : 55|1@0+ (1,0) [0|1] "" TCP,CSM

BO_ 1914 DTCInfo_CSM_AV_PDU: 7 CSM_AV
 SG_ DTCI_CSM_AV_DTCFailType : 6|8@0+ (1,0) [0|255] "" CGM,TCP
 SG_ DTCI_CSM_AV_CnfrmdDTC : 7|1@0+ (1,0) [0|1] "" CGM,TCP
 SG_ DTCI_CSM_AV_DTCFaultType : 14|8@0+ (1,0) [0|3] "" CGM,TCP
 SG_ DTCI_CSM_AV_DTCNumber : 22|16@0+ (1,0) [0|65535] "" CGM,TCP
 SG_ DTCI_CSM_AV_DTCSource : 38|8@0+ (1,0) [0|255] "" CGM,TCP
 SG_ DTCI_CSM_AV_TstNCmpltdOpCyc : 40|1@0+ (1,0) [0|1] "" CGM,TCP
 SG_ DTCI_CSM_AV_TstNCmpltdLstClr : 41|1@0+ (1,0) [0|1] "" CGM,TCP
 SG_ DTCI_CSM_AV_TstFldOpCyc : 42|1@0+ (1,0) [0|1] "" CGM,TCP
 SG_ DTCI_CSM_AV_TstFldLstClr : 43|1@0+ (1,0) [0|1] "" CGM,TCP
 SG_ DTCI_CSM_AV_TstFld : 44|1@0+ (1,0) [0|1] "" CGM,TCP
 SG_ DTCI_CSM_AV_PndngDTC : 45|1@0+ (1,0) [0|1] "" CGM,TCP
 SG_ DTCI_CSM_AV_DTCTriggered : 46|1@0+ (1,0) [0|1] "" CGM,TCP
 SG_ DTCI_CSM_AV_WrnIndTrggrd : 54|1@0+ (1,0) [0|1] "" CGM,TCP
 SG_ DTCI_CSM_AV_WrnIndRqd : 55|1@0+ (1,0) [0|1] "" CGM,TCP

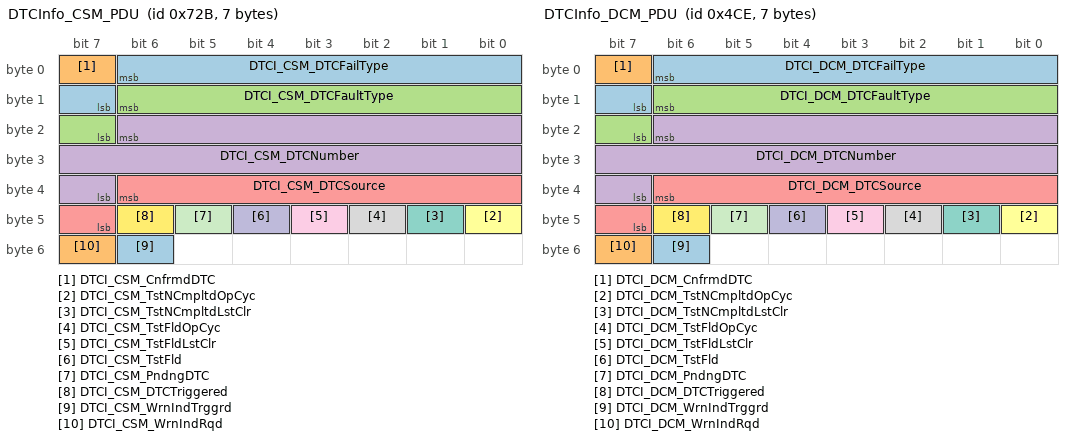
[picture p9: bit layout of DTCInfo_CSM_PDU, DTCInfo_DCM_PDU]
BO_ 1835 DTCInfo_CSM_PDU: 7 CSM
 SG_ DTCI_CSM_DTCFailType : 6|8@0+ (1,0) [0|255] "" TCP
 SG_ DTCI_CSM_CnfrmdDTC : 7|1@0+ (1,0) [0|1] "" TCP
 SG_ DTCI_CSM_DTCFaultType : 14|8@0+ (1,0) [0|3] "" TCP
 SG_ DTCI_CSM_DTCNumber : 22|16@0+ (1,0) [0|65535] "" TCP
 SG_ DTCI_CSM_DTCSource : 38|8@0+ (1,0) [0|255] "" CGM,TCP
 SG_ DTCI_CSM_TstNCmpltdOpCyc : 40|1@0+ (1,0) [0|1] "" TCP
 SG_ DTCI_CSM_TstNCmpltdLstClr : 41|1@0+ (1,0) [0|1] "" TCP
 SG_ DTCI_CSM_TstFldOpCyc : 42|1@0+ (1,0) [0|1] "" TCP
 SG_ DTCI_CSM_TstFldLstClr : 43|1@0+ (1,0) [0|1] "" TCP
 SG_ DTCI_CSM_TstFld : 44|1@0+ (1,0) [0|1] "" TCP
 SG_ DTCI_CSM_PndngDTC : 45|1@0+ (1,0) [0|1] "" TCP
 SG_ DTCI_CSM_DTCTriggered : 46|1@0+ (1,0) [0|1] "" TCP
 SG_ DTCI_CSM_WrnIndTrggrd : 54|1@0+ (1,0) [0|1] "" TCP
 SG_ DTCI_CSM_WrnIndRqd : 55|1@0+ (1,0) [0|1] "" TCP

BO_ 1230 DTCInfo_DCM_PDU: 7 CGM
 SG_ DTCI_DCM_DTCFailType : 6|8@0+ (1,0) [0|255] "" TCP,CSM
 SG_ DTCI_DCM_CnfrmdDTC : 7|1@0+ (1,0) [0|1] "" TCP,CSM
 SG_ DTCI_DCM_DTCFaultType : 14|8@0+ (1,0) [0|3] "" TCP,CSM
 SG_ DTCI_DCM_DTCNumber : 22|16@0+ (1,0) [0|65535] "" TCP,CSM
 SG_ DTCI_DCM_DTCSource : 38|8@0+ (1,0) [0|255] "" TCP,CSM
 SG_ DTCI_DCM_TstNCmpltdOpCyc : 40|1@0+ (1,0) [0|1] "" TCP,CSM
 SG_ DTCI_DCM_TstNCmpltdLstClr : 41|1@0+ (1,0) [0|1] "" TCP,CSM
 SG_ DTCI_DCM_TstFldOpCyc : 42|1@0+ (1,0) [0|1] "" TCP,CSM
 SG_ DTCI_DCM_TstFldLstClr : 43|1@0+ (1,0) [0|1] "" TCP,CSM
 SG_ DTCI_DCM_TstFld : 44|1@0+ (1,0) [0|1] "" TCP,CSM
 SG_ DTCI_DCM_PndngDTC : 45|1@0+ (1,0) [0|1] "" TCP,CSM
 SG_ DTCI_DCM_DTCTriggered : 46|1@0+ (1,0) [0|1] "" TCP,CSM
 SG_ DTCI_DCM_WrnIndTrggrd : 54|1@0+ (1,0) [0|1] "" TCP,CSM
 SG_ DTCI_DCM_WrnIndRqd : 55|1@0+ (1,0) [0|1] "" TCP,CSM

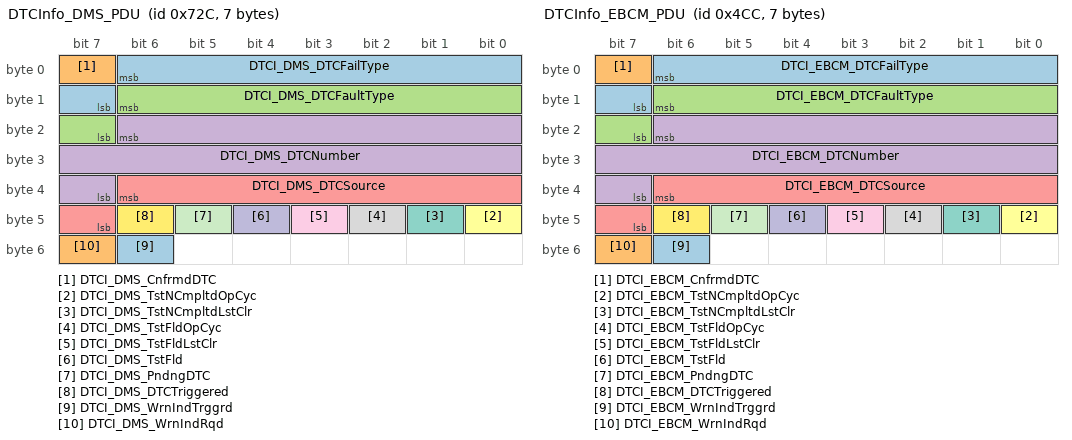
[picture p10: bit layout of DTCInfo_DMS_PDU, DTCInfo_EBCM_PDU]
BO_ 1836 DTCInfo_DMS_PDU: 7 CGM
 SG_ DTCI_DMS_DTCFailType : 6|8@0+ (1,0) [0|255] "" TCP,CSM
 SG_ DTCI_DMS_CnfrmdDTC : 7|1@0+ (1,0) [0|1] "" TCP,CSM
 SG_ DTCI_DMS_DTCFaultType : 14|8@0+ (1,0) [0|3] "" TCP,CSM
 SG_ DTCI_DMS_DTCNumber : 22|16@0+ (1,0) [0|65535] "" TCP,CSM
 SG_ DTCI_DMS_DTCSource : 38|8@0+ (1,0) [0|255] "" TCP,CSM
 SG_ DTCI_DMS_TstNCmpltdOpCyc : 40|1@0+ (1,0) [0|1] "" TCP,CSM
 SG_ DTCI_DMS_TstNCmpltdLstClr : 41|1@0+ (1,0) [0|1] "" TCP,CSM
 SG_ DTCI_DMS_TstFldOpCyc : 42|1@0+ (1,0) [0|1] "" TCP,CSM
 SG_ DTCI_DMS_TstFldLstClr : 43|1@0+ (1,0) [0|1] "" TCP,CSM
 SG_ DTCI_DMS_TstFld : 44|1@0+ (1,0) [0|1] "" TCP,CSM
 SG_ DTCI_DMS_PndngDTC : 45|1@0+ (1,0) [0|1] "" TCP,CSM
 SG_ DTCI_DMS_DTCTriggered : 46|1@0+ (1,0) [0|1] "" TCP,CSM
 SG_ DTCI_DMS_WrnIndTrggrd : 54|1@0+ (1,0) [0|1] "" TCP,CSM
 SG_ DTCI_DMS_WrnIndRqd : 55|1@0+ (1,0) [0|1] "" TCP,CSM

BO_ 1228 DTCInfo_EBCM_PDU: 7 CGM
 SG_ DTCI_EBCM_DTCFailType : 6|8@0+ (1,0) [0|255] "" TCP,CSM
 SG_ DTCI_EBCM_CnfrmdDTC : 7|1@0+ (1,0) [0|1] "" TCP,CSM
 SG_ DTCI_EBCM_DTCFaultType : 14|8@0+ (1,0) [0|3] "" TCP,CSM
 SG_ DTCI_EBCM_DTCNumber : 22|16@0+ (1,0) [0|65535] "" TCP,CSM
 SG_ DTCI_EBCM_DTCSource : 38|8@0+ (1,0) [0|255] "" TCP,CSM
 SG_ DTCI_EBCM_TstNCmpltdOpCyc : 40|1@0+ (1,0) [0|1] "" TCP,CSM
 SG_ DTCI_EBCM_TstNCmpltdLstClr : 41|1@0+ (1,0) [0|1] "" TCP,CSM
 SG_ DTCI_EBCM_TstFldOpCyc : 42|1@0+ (1,0) [0|1] "" TCP,CSM
 SG_ DTCI_EBCM_TstFldLstClr : 43|1@0+ (1,0) [0|1] "" TCP,CSM
 SG_ DTCI_EBCM_TstFld : 44|1@0+ (1,0) [0|1] "" TCP,CSM
 SG_ DTCI_EBCM_PndngDTC : 45|1@0+ (1,0) [0|1] "" TCP,CSM
 SG_ DTCI_EBCM_DTCTriggered : 46|1@0+ (1,0) [0|1] "" TCP,CSM
 SG_ DTCI_EBCM_WrnIndTrggrd : 54|1@0+ (1,0) [0|1] "" TCP,CSM
 SG_ DTCI_EBCM_WrnIndRqd : 55|1@0+ (1,0) [0|1] "" TCP,CSM

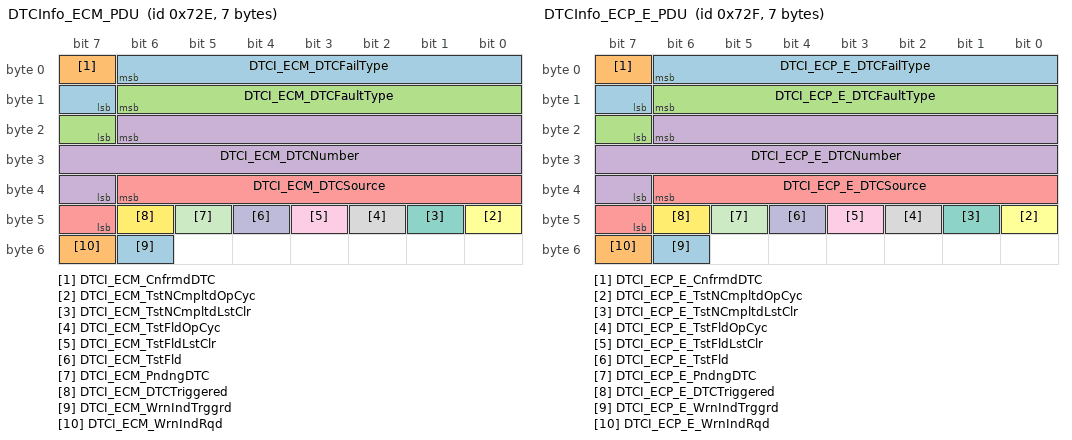
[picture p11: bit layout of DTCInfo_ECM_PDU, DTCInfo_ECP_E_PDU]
BO_ 1838 DTCInfo_ECM_PDU: 7 CGM
 SG_ DTCI_ECM_DTCFailType : 6|8@0+ (1,0) [0|255] "" TCP,CSM
 SG_ DTCI_ECM_CnfrmdDTC : 7|1@0+ (1,0) [0|1] "" TCP,CSM
 SG_ DTCI_ECM_DTCFaultType : 14|8@0+ (1,0) [0|3] "" TCP,CSM
 SG_ DTCI_ECM_DTCNumber : 22|16@0+ (1,0) [0|65535] "" TCP,CSM
 SG_ DTCI_ECM_DTCSource : 38|8@0+ (1,0) [0|255] "" TCP,CSM
 SG_ DTCI_ECM_TstNCmpltdOpCyc : 40|1@0+ (1,0) [0|1] "" TCP,CSM
 SG_ DTCI_ECM_TstNCmpltdLstClr : 41|1@0+ (1,0) [0|1] "" TCP,CSM
 SG_ DTCI_ECM_TstFldOpCyc : 42|1@0+ (1,0) [0|1] "" TCP,CSM
 SG_ DTCI_ECM_TstFldLstClr : 43|1@0+ (1,0) [0|1] "" TCP,CSM
 SG_ DTCI_ECM_TstFld : 44|1@0+ (1,0) [0|1] "" TCP,CSM
 SG_ DTCI_ECM_PndngDTC : 45|1@0+ (1,0) [0|1] "" TCP,CSM
 SG_ DTCI_ECM_DTCTriggered : 46|1@0+ (1,0) [0|1] "" TCP,CSM
 SG_ DTCI_ECM_WrnIndTrggrd : 54|1@0+ (1,0) [0|1] "" TCP,CSM
 SG_ DTCI_ECM_WrnIndRqd : 55|1@0+ (1,0) [0|1] "" TCP,CSM

BO_ 1839 DTCInfo_ECP_E_PDU: 7 CGM
 SG_ DTCI_ECP_E_DTCFailType : 6|8@0+ (1,0) [0|255] "" TCP,CSM
 SG_ DTCI_ECP_E_CnfrmdDTC : 7|1@0+ (1,0) [0|1] "" TCP,CSM
 SG_ DTCI_ECP_E_DTCFaultType : 14|8@0+ (1,0) [0|3] "" TCP,CSM
 SG_ DTCI_ECP_E_DTCNumber : 22|16@0+ (1,0) [0|65535] "" TCP,CSM
 SG_ DTCI_ECP_E_DTCSource : 38|8@0+ (1,0) [0|255] "" TCP,CSM
 SG_ DTCI_ECP_E_TstNCmpltdOpCyc : 40|1@0+ (1,0) [0|1] "" TCP,CSM
 SG_ DTCI_ECP_E_TstNCmpltdLstClr : 41|1@0+ (1,0) [0|1] "" TCP,CSM
 SG_ DTCI_ECP_E_TstFldOpCyc : 42|1@0+ (1,0) [0|1] "" TCP,CSM
 SG_ DTCI_ECP_E_TstFldLstClr : 43|1@0+ (1,0) [0|1] "" TCP,CSM
 SG_ DTCI_ECP_E_TstFld : 44|1@0+ (1,0) [0|1] "" TCP,CSM
 SG_ DTCI_ECP_E_PndngDTC : 45|1@0+ (1,0) [0|1] "" TCP,CSM
 SG_ DTCI_ECP_E_DTCTriggered : 46|1@0+ (1,0) [0|1] "" TCP,CSM
 SG_ DTCI_ECP_E_WrnIndTrggrd : 54|1@0+ (1,0) [0|1] "" TCP,CSM
 SG_ DTCI_ECP_E_WrnIndRqd : 55|1@0+ (1,0) [0|1] "" TCP,CSM

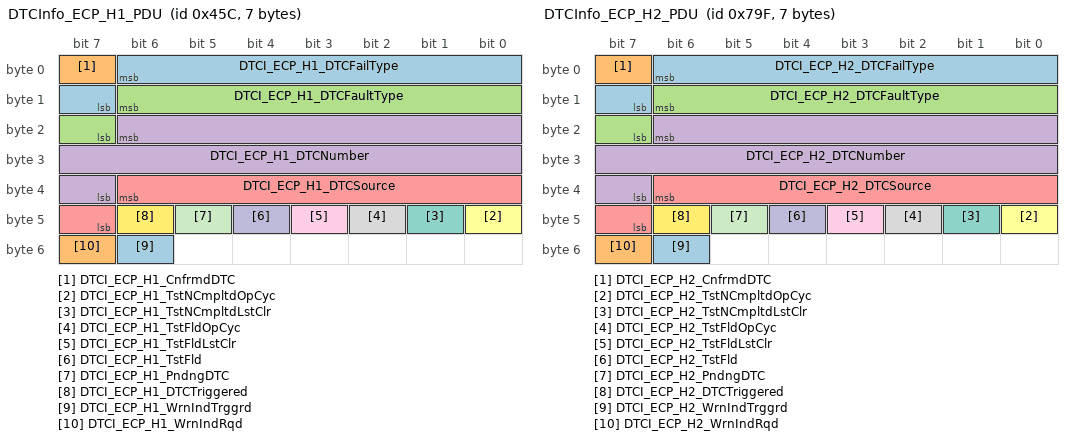
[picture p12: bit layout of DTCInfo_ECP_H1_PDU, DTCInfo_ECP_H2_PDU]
BO_ 1116 DTCInfo_ECP_H1_PDU: 7 CGM
 SG_ DTCI_ECP_H1_DTCFailType : 6|8@0+ (1,0) [0|255] "" TCP
 SG_ DTCI_ECP_H1_CnfrmdDTC : 7|1@0+ (1,0) [0|1] "" TCP
 SG_ DTCI_ECP_H1_DTCFaultType : 14|8@0+ (1,0) [0|3] "" TCP
 SG_ DTCI_ECP_H1_DTCNumber : 22|16@0+ (1,0) [0|65535] "" TCP
 SG_ DTCI_ECP_H1_DTCSource : 38|8@0+ (1,0) [0|255] "" TCP
 SG_ DTCI_ECP_H1_TstNCmpltdOpCyc : 40|1@0+ (1,0) [0|1] "" TCP
 SG_ DTCI_ECP_H1_TstNCmpltdLstClr : 41|1@0+ (1,0) [0|1] "" TCP
 SG_ DTCI_ECP_H1_TstFldOpCyc : 42|1@0+ (1,0) [0|1] "" TCP
 SG_ DTCI_ECP_H1_TstFldLstClr : 43|1@0+ (1,0) [0|1] "" TCP
 SG_ DTCI_ECP_H1_TstFld : 44|1@0+ (1,0) [0|1] "" TCP
 SG_ DTCI_ECP_H1_PndngDTC : 45|1@0+ (1,0) [0|1] "" TCP
 SG_ DTCI_ECP_H1_DTCTriggered : 46|1@0+ (1,0) [0|1] "" TCP
 SG_ DTCI_ECP_H1_WrnIndTrggrd : 54|1@0+ (1,0) [0|1] "" TCP
 SG_ DTCI_ECP_H1_WrnIndRqd : 55|1@0+ (1,0) [0|1] "" TCP

BO_ 1951 DTCInfo_ECP_H2_PDU: 7 CGM
 SG_ DTCI_ECP_H2_DTCFailType : 6|8@0+ (1,0) [0|255] "" TCP
 SG_ DTCI_ECP_H2_CnfrmdDTC : 7|1@0+ (1,0) [0|1] "" TCP
 SG_ DTCI_ECP_H2_DTCFaultType : 14|8@0+ (1,0) [0|3] "" TCP
 SG_ DTCI_ECP_H2_DTCNumber : 22|16@0+ (1,0) [0|65535] "" TCP
 SG_ DTCI_ECP_H2_DTCSource : 38|8@0+ (1,0) [0|255] "" TCP
 SG_ DTCI_ECP_H2_TstNCmpltdOpCyc : 40|1@0+ (1,0) [0|1] "" TCP
 SG_ DTCI_ECP_H2_TstNCmpltdLstClr : 41|1@0+ (1,0) [0|1] "" TCP
 SG_ DTCI_ECP_H2_TstFldOpCyc : 42|1@0+ (1,0) [0|1] "" TCP
 SG_ DTCI_ECP_H2_TstFldLstClr : 43|1@0+ (1,0) [0|1] "" TCP
 SG_ DTCI_ECP_H2_TstFld : 44|1@0+ (1,0) [0|1] "" TCP
 SG_ DTCI_ECP_H2_PndngDTC : 45|1@0+ (1,0) [0|1] "" TCP
 SG_ DTCI_ECP_H2_DTCTriggered : 46|1@0+ (1,0) [0|1] "" TCP
 SG_ DTCI_ECP_H2_WrnIndTrggrd : 54|1@0+ (1,0) [0|1] "" TCP
 SG_ DTCI_ECP_H2_WrnIndRqd : 55|1@0+ (1,0) [0|1] "" TCP

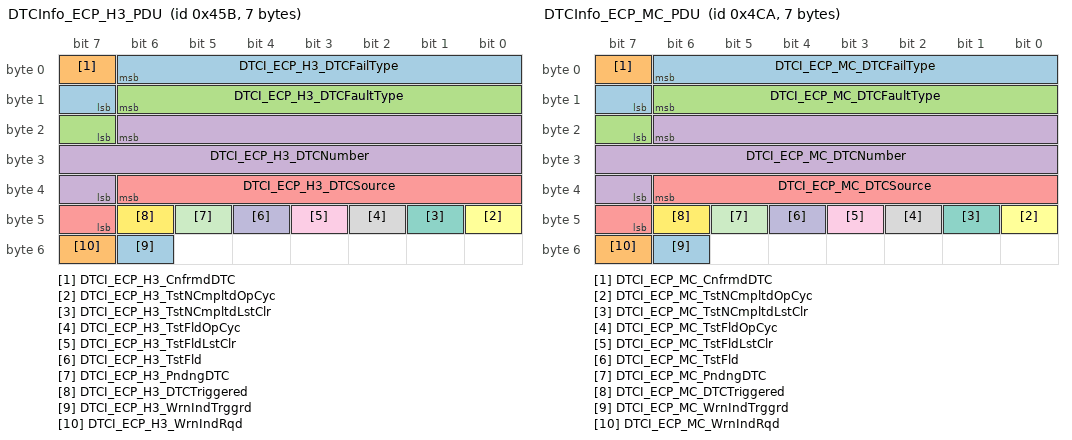
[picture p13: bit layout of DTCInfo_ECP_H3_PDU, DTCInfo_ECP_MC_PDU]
BO_ 1115 DTCInfo_ECP_H3_PDU: 7 CGM
 SG_ DTCI_ECP_H3_DTCFailType : 6|8@0+ (1,0) [0|255] "" TCP
 SG_ DTCI_ECP_H3_CnfrmdDTC : 7|1@0+ (1,0) [0|1] "" TCP
 SG_ DTCI_ECP_H3_DTCFaultType : 14|8@0+ (1,0) [0|3] "" TCP
 SG_ DTCI_ECP_H3_DTCNumber : 22|16@0+ (1,0) [0|65535] "" TCP
 SG_ DTCI_ECP_H3_DTCSource : 38|8@0+ (1,0) [0|255] "" TCP
 SG_ DTCI_ECP_H3_TstNCmpltdOpCyc : 40|1@0+ (1,0) [0|1] "" TCP
 SG_ DTCI_ECP_H3_TstNCmpltdLstClr : 41|1@0+ (1,0) [0|1] "" TCP
 SG_ DTCI_ECP_H3_TstFldOpCyc : 42|1@0+ (1,0) [0|1] "" TCP
 SG_ DTCI_ECP_H3_TstFldLstClr : 43|1@0+ (1,0) [0|1] "" TCP
 SG_ DTCI_ECP_H3_TstFld : 44|1@0+ (1,0) [0|1] "" TCP
 SG_ DTCI_ECP_H3_PndngDTC : 45|1@0+ (1,0) [0|1] "" TCP
 SG_ DTCI_ECP_H3_DTCTriggered : 46|1@0+ (1,0) [0|1] "" TCP
 SG_ DTCI_ECP_H3_WrnIndTrggrd : 54|1@0+ (1,0) [0|1] "" TCP
 SG_ DTCI_ECP_H3_WrnIndRqd : 55|1@0+ (1,0) [0|1] "" TCP

BO_ 1226 DTCInfo_ECP_MC_PDU: 7 CGM
 SG_ DTCI_ECP_MC_DTCFailType : 6|8@0+ (1,0) [0|255] "" TCP,CSM
 SG_ DTCI_ECP_MC_CnfrmdDTC : 7|1@0+ (1,0) [0|1] "" TCP,CSM
 SG_ DTCI_ECP_MC_DTCFaultType : 14|8@0+ (1,0) [0|3] "" TCP,CSM
 SG_ DTCI_ECP_MC_DTCNumber : 22|16@0+ (1,0) [0|65535] "" TCP,CSM
 SG_ DTCI_ECP_MC_DTCSource : 38|8@0+ (1,0) [0|255] "" TCP,CSM
 SG_ DTCI_ECP_MC_TstNCmpltdOpCyc : 40|1@0+ (1,0) [0|1] "" TCP,CSM
 SG_ DTCI_ECP_MC_TstNCmpltdLstClr : 41|1@0+ (1,0) [0|1] "" TCP,CSM
 SG_ DTCI_ECP_MC_TstFldOpCyc : 42|1@0+ (1,0) [0|1] "" TCP,CSM
 SG_ DTCI_ECP_MC_TstFldLstClr : 43|1@0+ (1,0) [0|1] "" TCP,CSM
 SG_ DTCI_ECP_MC_TstFld : 44|1@0+ (1,0) [0|1] "" TCP,CSM
 SG_ DTCI_ECP_MC_PndngDTC : 45|1@0+ (1,0) [0|1] "" TCP,CSM
 SG_ DTCI_ECP_MC_DTCTriggered : 46|1@0+ (1,0) [0|1] "" TCP,CSM
 SG_ DTCI_ECP_MC_WrnIndTrggrd : 54|1@0+ (1,0) [0|1] "" TCP,CSM
 SG_ DTCI_ECP_MC_WrnIndRqd : 55|1@0+ (1,0) [0|1] "" TCP,CSM

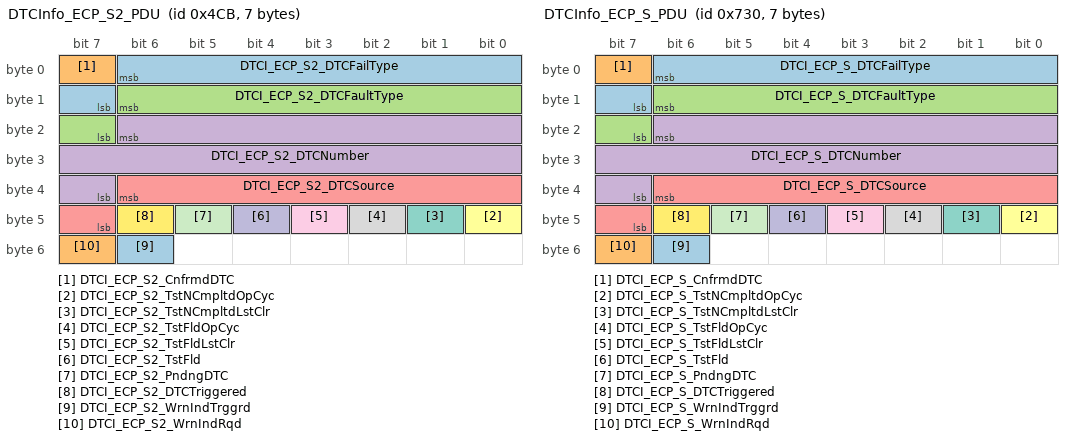
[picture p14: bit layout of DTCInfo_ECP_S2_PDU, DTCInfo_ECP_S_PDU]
BO_ 1227 DTCInfo_ECP_S2_PDU: 7 CGM
 SG_ DTCI_ECP_S2_DTCFailType : 6|8@0+ (1,0) [0|255] "" TCP
 SG_ DTCI_ECP_S2_CnfrmdDTC : 7|1@0+ (1,0) [0|1] "" TCP
 SG_ DTCI_ECP_S2_DTCFaultType : 14|8@0+ (1,0) [0|3] "" TCP
 SG_ DTCI_ECP_S2_DTCNumber : 22|16@0+ (1,0) [0|65535] "" TCP
 SG_ DTCI_ECP_S2_DTCSource : 38|8@0+ (1,0) [0|255] "" TCP
 SG_ DTCI_ECP_S2_TstNCmpltdOpCyc : 40|1@0+ (1,0) [0|1] "" TCP
 SG_ DTCI_ECP_S2_TstNCmpltdLstClr : 41|1@0+ (1,0) [0|1] "" TCP
 SG_ DTCI_ECP_S2_TstFldOpCyc : 42|1@0+ (1,0) [0|1] "" TCP
 SG_ DTCI_ECP_S2_TstFldLstClr : 43|1@0+ (1,0) [0|1] "" TCP
 SG_ DTCI_ECP_S2_TstFld : 44|1@0+ (1,0) [0|1] "" TCP
 SG_ DTCI_ECP_S2_PndngDTC : 45|1@0+ (1,0) [0|1] "" TCP
 SG_ DTCI_ECP_S2_DTCTriggered : 46|1@0+ (1,0) [0|1] "" TCP
 SG_ DTCI_ECP_S2_WrnIndTrggrd : 54|1@0+ (1,0) [0|1] "" TCP
 SG_ DTCI_ECP_S2_WrnIndRqd : 55|1@0+ (1,0) [0|1] "" TCP

BO_ 1840 DTCInfo_ECP_S_PDU: 7 CGM
 SG_ DTCI_ECP_S_DTCFailType : 6|8@0+ (1,0) [0|255] "" TCP,CSM
 SG_ DTCI_ECP_S_CnfrmdDTC : 7|1@0+ (1,0) [0|1] "" TCP,CSM
 SG_ DTCI_ECP_S_DTCFaultType : 14|8@0+ (1,0) [0|3] "" TCP,CSM
 SG_ DTCI_ECP_S_DTCNumber : 22|16@0+ (1,0) [0|65535] "" TCP,CSM
 SG_ DTCI_ECP_S_DTCSource : 38|8@0+ (1,0) [0|255] "" TCP,CSM
 SG_ DTCI_ECP_S_TstNCmpltdOpCyc : 40|1@0+ (1,0) [0|1] "" TCP,CSM
 SG_ DTCI_ECP_S_TstNCmpltdLstClr : 41|1@0+ (1,0) [0|1] "" TCP,CSM
 SG_ DTCI_ECP_S_TstFldOpCyc : 42|1@0+ (1,0) [0|1] "" TCP,CSM
 SG_ DTCI_ECP_S_TstFldLstClr : 43|1@0+ (1,0) [0|1] "" TCP,CSM
 SG_ DTCI_ECP_S_TstFld : 44|1@0+ (1,0) [0|1] "" TCP,CSM
 SG_ DTCI_ECP_S_PndngDTC : 45|1@0+ (1,0) [0|1] "" TCP,CSM
 SG_ DTCI_ECP_S_DTCTriggered : 46|1@0+ (1,0) [0|1] "" TCP,CSM
 SG_ DTCI_ECP_S_WrnIndTrggrd : 54|1@0+ (1,0) [0|1] "" TCP,CSM
 SG_ DTCI_ECP_S_WrnIndRqd : 55|1@0+ (1,0) [0|1] "" TCP,CSM

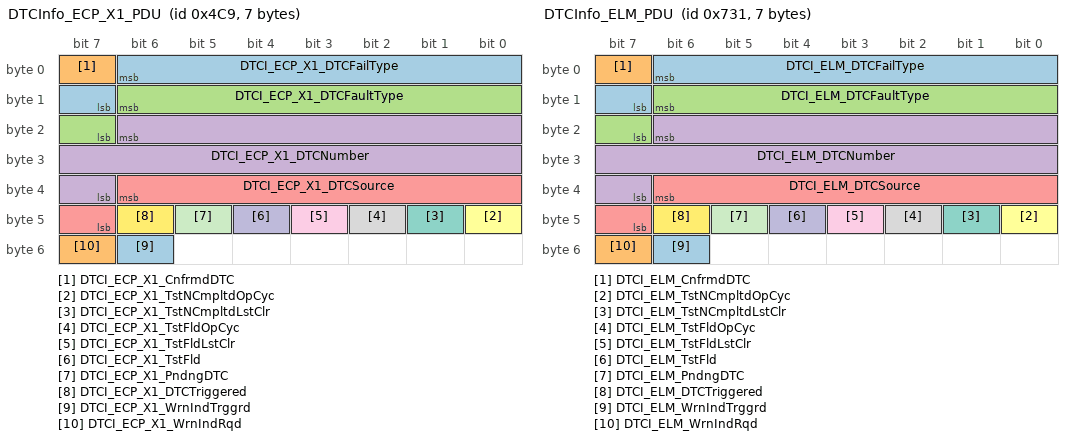
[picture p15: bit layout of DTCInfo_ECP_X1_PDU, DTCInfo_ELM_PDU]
BO_ 1225 DTCInfo_ECP_X1_PDU: 7 CGM
 SG_ DTCI_ECP_X1_DTCFailType : 6|8@0+ (1,0) [0|255] "" TCP,CSM
 SG_ DTCI_ECP_X1_CnfrmdDTC : 7|1@0+ (1,0) [0|1] "" TCP,CSM
 SG_ DTCI_ECP_X1_DTCFaultType : 14|8@0+ (1,0) [0|3] "" TCP,CSM
 SG_ DTCI_ECP_X1_DTCNumber : 22|16@0+ (1,0) [0|65535] "" TCP,CSM
 SG_ DTCI_ECP_X1_DTCSource : 38|8@0+ (1,0) [0|255] "" TCP,CSM
 SG_ DTCI_ECP_X1_TstNCmpltdOpCyc : 40|1@0+ (1,0) [0|1] "" TCP,CSM
 SG_ DTCI_ECP_X1_TstNCmpltdLstClr : 41|1@0+ (1,0) [0|1] "" TCP,CSM
 SG_ DTCI_ECP_X1_TstFldOpCyc : 42|1@0+ (1,0) [0|1] "" TCP,CSM
 SG_ DTCI_ECP_X1_TstFldLstClr : 43|1@0+ (1,0) [0|1] "" TCP,CSM
 SG_ DTCI_ECP_X1_TstFld : 44|1@0+ (1,0) [0|1] "" TCP,CSM
 SG_ DTCI_ECP_X1_PndngDTC : 45|1@0+ (1,0) [0|1] "" TCP,CSM
 SG_ DTCI_ECP_X1_DTCTriggered : 46|1@0+ (1,0) [0|1] "" TCP,CSM
 SG_ DTCI_ECP_X1_WrnIndTrggrd : 54|1@0+ (1,0) [0|1] "" TCP,CSM
 SG_ DTCI_ECP_X1_WrnIndRqd : 55|1@0+ (1,0) [0|1] "" TCP,CSM

BO_ 1841 DTCInfo_ELM_PDU: 7 CGM
 SG_ DTCI_ELM_DTCFailType : 6|8@0+ (1,0) [0|255] "" TCP,CSM
 SG_ DTCI_ELM_CnfrmdDTC : 7|1@0+ (1,0) [0|1] "" TCP,CSM
 SG_ DTCI_ELM_DTCFaultType : 14|8@0+ (1,0) [0|3] "" TCP,CSM
 SG_ DTCI_ELM_DTCNumber : 22|16@0+ (1,0) [0|65535] "" TCP,CSM
 SG_ DTCI_ELM_DTCSource : 38|8@0+ (1,0) [0|255] "" TCP,CSM
 SG_ DTCI_ELM_TstNCmpltdOpCyc : 40|1@0+ (1,0) [0|1] "" TCP,CSM
 SG_ DTCI_ELM_TstNCmpltdLstClr : 41|1@0+ (1,0) [0|1] "" TCP,CSM
 SG_ DTCI_ELM_TstFldOpCyc : 42|1@0+ (1,0) [0|1] "" TCP,CSM
 SG_ DTCI_ELM_TstFldLstClr : 43|1@0+ (1,0) [0|1] "" TCP,CSM
 SG_ DTCI_ELM_TstFld : 44|1@0+ (1,0) [0|1] "" TCP,CSM
 SG_ DTCI_ELM_PndngDTC : 45|1@0+ (1,0) [0|1] "" TCP,CSM
 SG_ DTCI_ELM_DTCTriggered : 46|1@0+ (1,0) [0|1] "" TCP,CSM
 SG_ DTCI_ELM_WrnIndTrggrd : 54|1@0+ (1,0) [0|1] "" TCP,CSM
 SG_ DTCI_ELM_WrnIndRqd : 55|1@0+ (1,0) [0|1] "" TCP,CSM

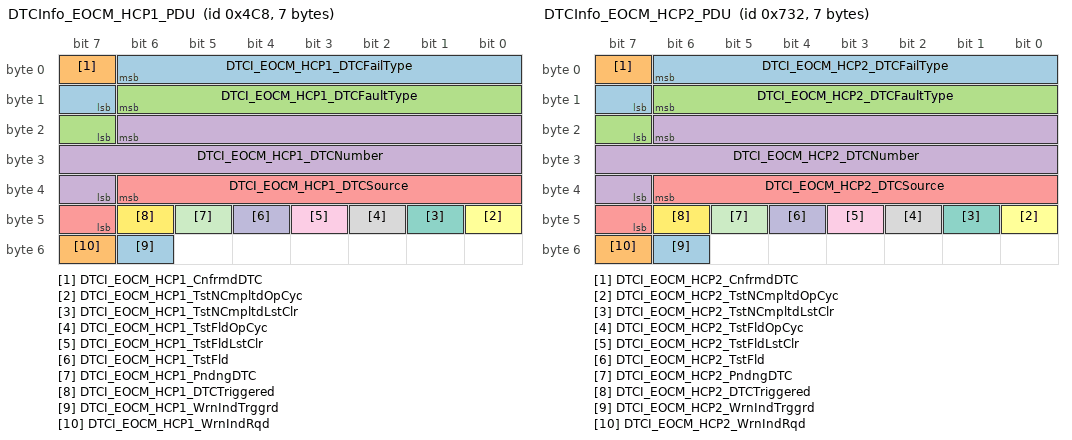
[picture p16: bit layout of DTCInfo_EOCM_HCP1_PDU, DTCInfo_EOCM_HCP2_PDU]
BO_ 1224 DTCInfo_EOCM_HCP1_PDU: 7 CGM
 SG_ DTCI_EOCM_HCP1_DTCFailType : 6|8@0+ (1,0) [0|255] "" TCP,CSM
 SG_ DTCI_EOCM_HCP1_CnfrmdDTC : 7|1@0+ (1,0) [0|1] "" TCP,CSM
 SG_ DTCI_EOCM_HCP1_DTCFaultType : 14|8@0+ (1,0) [0|3] "" TCP,CSM
 SG_ DTCI_EOCM_HCP1_DTCNumber : 22|16@0+ (1,0) [0|65535] "" TCP,CSM
 SG_ DTCI_EOCM_HCP1_DTCSource : 38|8@0+ (1,0) [0|255] "" TCP,CSM
 SG_ DTCI_EOCM_HCP1_TstNCmpltdOpCyc : 40|1@0+ (1,0) [0|1] "" TCP,CSM
 SG_ DTCI_EOCM_HCP1_TstNCmpltdLstClr : 41|1@0+ (1,0) [0|1] "" TCP,CSM
 SG_ DTCI_EOCM_HCP1_TstFldOpCyc : 42|1@0+ (1,0) [0|1] "" TCP,CSM
 SG_ DTCI_EOCM_HCP1_TstFldLstClr : 43|1@0+ (1,0) [0|1] "" TCP,CSM
 SG_ DTCI_EOCM_HCP1_TstFld : 44|1@0+ (1,0) [0|1] "" TCP,CSM
 SG_ DTCI_EOCM_HCP1_PndngDTC : 45|1@0+ (1,0) [0|1] "" TCP,CSM
 SG_ DTCI_EOCM_HCP1_DTCTriggered : 46|1@0+ (1,0) [0|1] "" TCP,CSM
 SG_ DTCI_EOCM_HCP1_WrnIndTrggrd : 54|1@0+ (1,0) [0|1] "" TCP,CSM
 SG_ DTCI_EOCM_HCP1_WrnIndRqd : 55|1@0+ (1,0) [0|1] "" TCP,CSM

BO_ 1842 DTCInfo_EOCM_HCP2_PDU: 7 CGM
 SG_ DTCI_EOCM_HCP2_DTCFailType : 6|8@0+ (1,0) [0|255] "" TCP,CSM
 SG_ DTCI_EOCM_HCP2_CnfrmdDTC : 7|1@0+ (1,0) [0|1] "" TCP,CSM
 SG_ DTCI_EOCM_HCP2_DTCFaultType : 14|8@0+ (1,0) [0|3] "" TCP,CSM
 SG_ DTCI_EOCM_HCP2_DTCNumber : 22|16@0+ (1,0) [0|65535] "" TCP,CSM
 SG_ DTCI_EOCM_HCP2_DTCSource : 38|8@0+ (1,0) [0|255] "" TCP,CSM
 SG_ DTCI_EOCM_HCP2_TstNCmpltdOpCyc : 40|1@0+ (1,0) [0|1] "" TCP,CSM
 SG_ DTCI_EOCM_HCP2_TstNCmpltdLstClr : 41|1@0+ (1,0) [0|1] "" TCP,CSM
 SG_ DTCI_EOCM_HCP2_TstFldOpCyc : 42|1@0+ (1,0) [0|1] "" TCP,CSM
 SG_ DTCI_EOCM_HCP2_TstFldLstClr : 43|1@0+ (1,0) [0|1] "" TCP,CSM
 SG_ DTCI_EOCM_HCP2_TstFld : 44|1@0+ (1,0) [0|1] "" TCP,CSM
 SG_ DTCI_EOCM_HCP2_PndngDTC : 45|1@0+ (1,0) [0|1] "" TCP,CSM
 SG_ DTCI_EOCM_HCP2_DTCTriggered : 46|1@0+ (1,0) [0|1] "" TCP,CSM
 SG_ DTCI_EOCM_HCP2_WrnIndTrggrd : 54|1@0+ (1,0) [0|1] "" TCP,CSM
 SG_ DTCI_EOCM_HCP2_WrnIndRqd : 55|1@0+ (1,0) [0|1] "" TCP,CSM

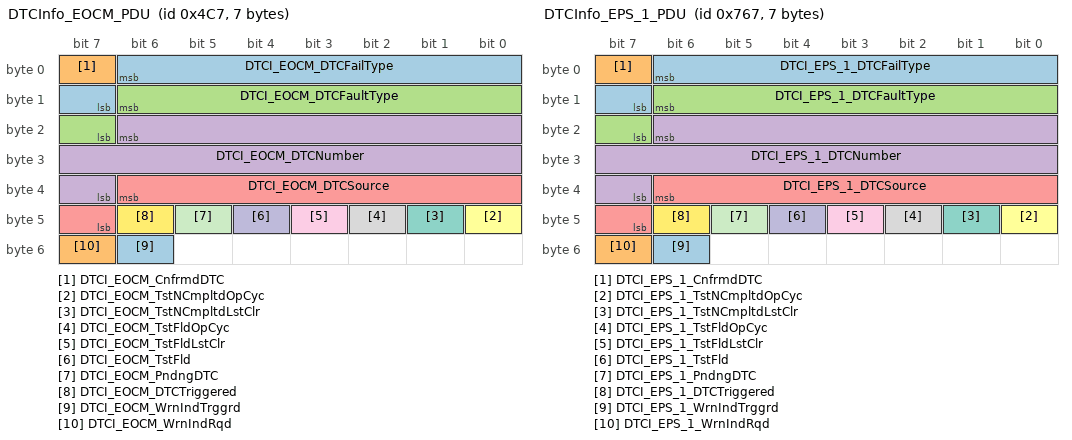
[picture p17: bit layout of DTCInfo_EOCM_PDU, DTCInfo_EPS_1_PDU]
BO_ 1223 DTCInfo_EOCM_PDU: 7 CGM
 SG_ DTCI_EOCM_DTCFailType : 6|8@0+ (1,0) [0|255] "" TCP,CSM
 SG_ DTCI_EOCM_CnfrmdDTC : 7|1@0+ (1,0) [0|1] "" TCP,CSM
 SG_ DTCI_EOCM_DTCFaultType : 14|8@0+ (1,0) [0|3] "" TCP,CSM
 SG_ DTCI_EOCM_DTCNumber : 22|16@0+ (1,0) [0|65535] "" TCP,CSM
 SG_ DTCI_EOCM_DTCSource : 38|8@0+ (1,0) [0|255] "" TCP,CSM
 SG_ DTCI_EOCM_TstNCmpltdOpCyc : 40|1@0+ (1,0) [0|1] "" TCP,CSM
 SG_ DTCI_EOCM_TstNCmpltdLstClr : 41|1@0+ (1,0) [0|1] "" TCP,CSM
 SG_ DTCI_EOCM_TstFldOpCyc : 42|1@0+ (1,0) [0|1] "" TCP,CSM
 SG_ DTCI_EOCM_TstFldLstClr : 43|1@0+ (1,0) [0|1] "" TCP,CSM
 SG_ DTCI_EOCM_TstFld : 44|1@0+ (1,0) [0|1] "" TCP,CSM
 SG_ DTCI_EOCM_PndngDTC : 45|1@0+ (1,0) [0|1] "" TCP,CSM
 SG_ DTCI_EOCM_DTCTriggered : 46|1@0+ (1,0) [0|1] "" TCP,CSM
 SG_ DTCI_EOCM_WrnIndTrggrd : 54|1@0+ (1,0) [0|1] "" TCP,CSM
 SG_ DTCI_EOCM_WrnIndRqd : 55|1@0+ (1,0) [0|1] "" TCP,CSM

BO_ 1895 DTCInfo_EPS_1_PDU: 7 CGM
 SG_ DTCI_EPS_1_DTCFailType : 6|8@0+ (1,0) [0|255] "" TCP
 SG_ DTCI_EPS_1_CnfrmdDTC : 7|1@0+ (1,0) [0|1] "" TCP
 SG_ DTCI_EPS_1_DTCFaultType : 14|8@0+ (1,0) [0|3] "" TCP
 SG_ DTCI_EPS_1_DTCNumber : 22|16@0+ (1,0) [0|65535] "" TCP
 SG_ DTCI_EPS_1_DTCSource : 38|8@0+ (1,0) [0|255] "" TCP
 SG_ DTCI_EPS_1_TstNCmpltdOpCyc : 40|1@0+ (1,0) [0|1] "" TCP
 SG_ DTCI_EPS_1_TstNCmpltdLstClr : 41|1@0+ (1,0) [0|1] "" TCP
 SG_ DTCI_EPS_1_TstFldOpCyc : 42|1@0+ (1,0) [0|1] "" TCP
 SG_ DTCI_EPS_1_TstFldLstClr : 43|1@0+ (1,0) [0|1] "" TCP
 SG_ DTCI_EPS_1_TstFld : 44|1@0+ (1,0) [0|1] "" TCP
 SG_ DTCI_EPS_1_PndngDTC : 45|1@0+ (1,0) [0|1] "" TCP
 SG_ DTCI_EPS_1_DTCTriggered : 46|1@0+ (1,0) [0|1] "" TCP
 SG_ DTCI_EPS_1_WrnIndTrggrd : 54|1@0+ (1,0) [0|1] "" TCP
 SG_ DTCI_EPS_1_WrnIndRqd : 55|1@0+ (1,0) [0|1] "" TCP

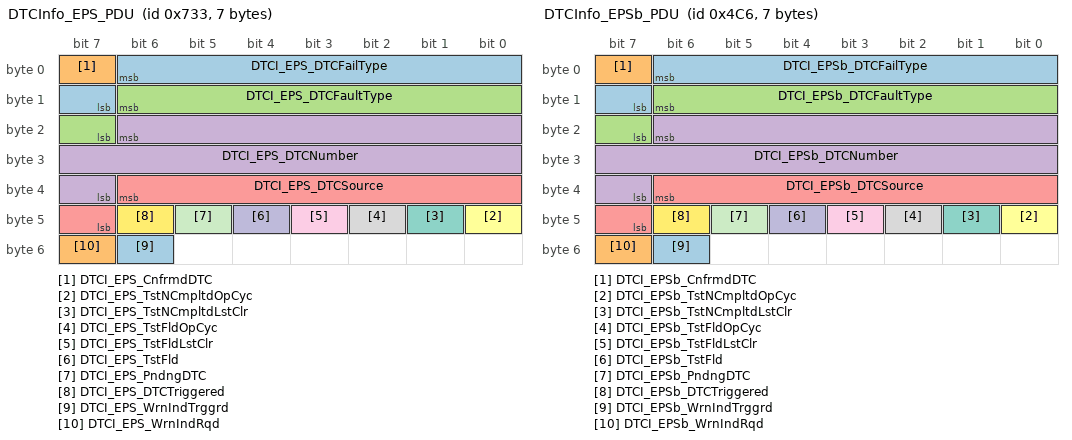
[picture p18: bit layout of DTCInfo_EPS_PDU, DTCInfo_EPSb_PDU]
BO_ 1843 DTCInfo_EPS_PDU: 7 CGM
 SG_ DTCI_EPS_DTCFailType : 6|8@0+ (1,0) [0|255] "" TCP,CSM
 SG_ DTCI_EPS_CnfrmdDTC : 7|1@0+ (1,0) [0|1] "" TCP,CSM
 SG_ DTCI_EPS_DTCFaultType : 14|8@0+ (1,0) [0|3] "" TCP,CSM
 SG_ DTCI_EPS_DTCNumber : 22|16@0+ (1,0) [0|65535] "" TCP,CSM
 SG_ DTCI_EPS_DTCSource : 38|8@0+ (1,0) [0|255] "" TCP,CSM
 SG_ DTCI_EPS_TstNCmpltdOpCyc : 40|1@0+ (1,0) [0|1] "" TCP,CSM
 SG_ DTCI_EPS_TstNCmpltdLstClr : 41|1@0+ (1,0) [0|1] "" TCP,CSM
 SG_ DTCI_EPS_TstFldOpCyc : 42|1@0+ (1,0) [0|1] "" TCP,CSM
 SG_ DTCI_EPS_TstFldLstClr : 43|1@0+ (1,0) [0|1] "" TCP,CSM
 SG_ DTCI_EPS_TstFld : 44|1@0+ (1,0) [0|1] "" TCP,CSM
 SG_ DTCI_EPS_PndngDTC : 45|1@0+ (1,0) [0|1] "" TCP,CSM
 SG_ DTCI_EPS_DTCTriggered : 46|1@0+ (1,0) [0|1] "" TCP,CSM
 SG_ DTCI_EPS_WrnIndTrggrd : 54|1@0+ (1,0) [0|1] "" TCP,CSM
 SG_ DTCI_EPS_WrnIndRqd : 55|1@0+ (1,0) [0|1] "" TCP,CSM

BO_ 1222 DTCInfo_EPSb_PDU: 7 CGM
 SG_ DTCI_EPSb_DTCFailType : 6|8@0+ (1,0) [0|255] "" TCP
 SG_ DTCI_EPSb_CnfrmdDTC : 7|1@0+ (1,0) [0|1] "" TCP
 SG_ DTCI_EPSb_DTCFaultType : 14|8@0+ (1,0) [0|3] "" TCP
 SG_ DTCI_EPSb_DTCNumber : 22|16@0+ (1,0) [0|65535] "" TCP
 SG_ DTCI_EPSb_DTCSource : 38|8@0+ (1,0) [0|255] "" TCP
 SG_ DTCI_EPSb_TstNCmpltdOpCyc : 40|1@0+ (1,0) [0|1] "" TCP
 SG_ DTCI_EPSb_TstNCmpltdLstClr : 41|1@0+ (1,0) [0|1] "" TCP
 SG_ DTCI_EPSb_TstFldOpCyc : 42|1@0+ (1,0) [0|1] "" TCP
 SG_ DTCI_EPSb_TstFldLstClr : 43|1@0+ (1,0) [0|1] "" TCP
 SG_ DTCI_EPSb_TstFld : 44|1@0+ (1,0) [0|1] "" TCP
 SG_ DTCI_EPSb_PndngDTC : 45|1@0+ (1,0) [0|1] "" TCP
 SG_ DTCI_EPSb_DTCTriggered : 46|1@0+ (1,0) [0|1] "" TCP
 SG_ DTCI_EPSb_WrnIndTrggrd : 54|1@0+ (1,0) [0|1] "" TCP
 SG_ DTCI_EPSb_WrnIndRqd : 55|1@0+ (1,0) [0|1] "" TCP

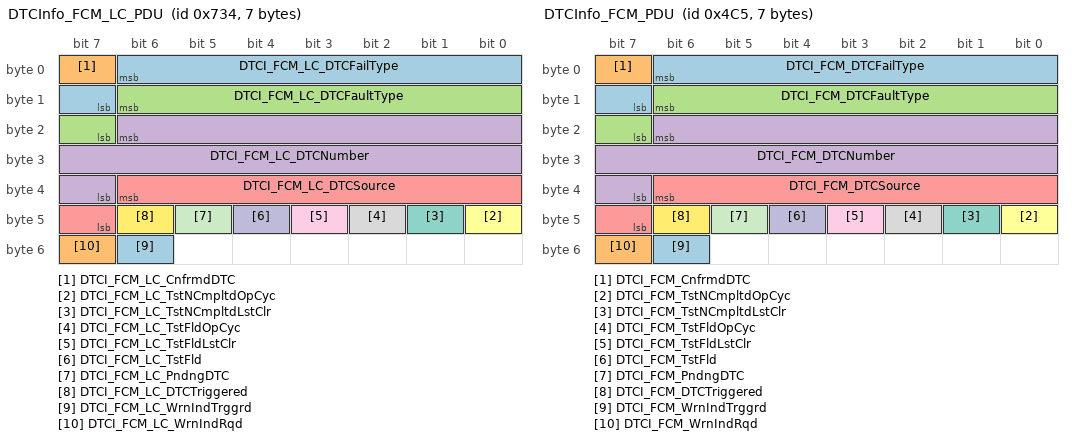
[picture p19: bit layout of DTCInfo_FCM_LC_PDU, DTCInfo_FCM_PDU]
BO_ 1844 DTCInfo_FCM_LC_PDU: 7 CGM
 SG_ DTCI_FCM_LC_DTCFailType : 6|8@0+ (1,0) [0|255] "" TCP,CSM
 SG_ DTCI_FCM_LC_CnfrmdDTC : 7|1@0+ (1,0) [0|1] "" TCP,CSM
 SG_ DTCI_FCM_LC_DTCFaultType : 14|8@0+ (1,0) [0|3] "" TCP,CSM
 SG_ DTCI_FCM_LC_DTCNumber : 22|16@0+ (1,0) [0|65535] "" TCP,CSM
 SG_ DTCI_FCM_LC_DTCSource : 38|8@0+ (1,0) [0|255] "" TCP,CSM
 SG_ DTCI_FCM_LC_TstNCmpltdOpCyc : 40|1@0+ (1,0) [0|1] "" TCP,CSM
 SG_ DTCI_FCM_LC_TstNCmpltdLstClr : 41|1@0+ (1,0) [0|1] "" TCP,CSM
 SG_ DTCI_FCM_LC_TstFldOpCyc : 42|1@0+ (1,0) [0|1] "" TCP,CSM
 SG_ DTCI_FCM_LC_TstFldLstClr : 43|1@0+ (1,0) [0|1] "" TCP,CSM
 SG_ DTCI_FCM_LC_TstFld : 44|1@0+ (1,0) [0|1] "" TCP,CSM
 SG_ DTCI_FCM_LC_PndngDTC : 45|1@0+ (1,0) [0|1] "" TCP,CSM
 SG_ DTCI_FCM_LC_DTCTriggered : 46|1@0+ (1,0) [0|1] "" TCP,CSM
 SG_ DTCI_FCM_LC_WrnIndTrggrd : 54|1@0+ (1,0) [0|1] "" TCP,CSM
 SG_ DTCI_FCM_LC_WrnIndRqd : 55|1@0+ (1,0) [0|1] "" TCP,CSM

BO_ 1221 DTCInfo_FCM_PDU: 7 CGM
 SG_ DTCI_FCM_DTCFailType : 6|8@0+ (1,0) [0|255] "" TCP,CSM
 SG_ DTCI_FCM_CnfrmdDTC : 7|1@0+ (1,0) [0|1] "" TCP,CSM
 SG_ DTCI_FCM_DTCFaultType : 14|8@0+ (1,0) [0|3] "" TCP,CSM
 SG_ DTCI_FCM_DTCNumber : 22|16@0+ (1,0) [0|65535] "" TCP,CSM
 SG_ DTCI_FCM_DTCSource : 38|8@0+ (1,0) [0|255] "" TCP,CSM
 SG_ DTCI_FCM_TstNCmpltdOpCyc : 40|1@0+ (1,0) [0|1] "" TCP,CSM
 SG_ DTCI_FCM_TstNCmpltdLstClr : 41|1@0+ (1,0) [0|1] "" TCP,CSM
 SG_ DTCI_FCM_TstFldOpCyc : 42|1@0+ (1,0) [0|1] "" TCP,CSM
 SG_ DTCI_FCM_TstFldLstClr : 43|1@0+ (1,0) [0|1] "" TCP,CSM
 SG_ DTCI_FCM_TstFld : 44|1@0+ (1,0) [0|1] "" TCP,CSM
 SG_ DTCI_FCM_PndngDTC : 45|1@0+ (1,0) [0|1] "" TCP,CSM
 SG_ DTCI_FCM_DTCTriggered : 46|1@0+ (1,0) [0|1] "" TCP,CSM
 SG_ DTCI_FCM_WrnIndTrggrd : 54|1@0+ (1,0) [0|1] "" TCP,CSM
 SG_ DTCI_FCM_WrnIndRqd : 55|1@0+ (1,0) [0|1] "" TCP,CSM

BO_ 1845 DTCInfo_FOPM_PDU: 7 CGM
 SG_ DTCI_FOPM_DTCFailType : 6|8@0+ (1,0) [0|255] "" TCP,CSM
 SG_ DTCI_FOPM_CnfrmdDTC : 7|1@0+ (1,0) [0|1] "" TCP,CSM
 SG_ DTCI_FOPM_DTCFaultType : 14|8@0+ (1,0) [0|3] "" TCP,CSM
 SG_ DTCI_FOPM_DTCNumber : 22|16@0+ (1,0) [0|65535] "" TCP,CSM
 SG_ DTCI_FOPM_DTCSource : 38|8@0+ (1,0) [0|255] "" TCP,CSM
 SG_ DTCI_FOPM_TstNCmpltdOpCyc : 40|1@0+ (1,0) [0|1] "" TCP,CSM
 SG_ DTCI_FOPM_TstNCmpltdLstClr : 41|1@0+ (1,0) [0|1] "" TCP,CSM
 SG_ DTCI_FOPM_TstFldOpCyc : 42|1@0+ (1,0) [0|1] "" TCP,CSM
 SG_ DTCI_FOPM_TstFldLstClr : 43|1@0+ (1,0) [0|1] "" TCP,CSM
 SG_ DTCI_FOPM_TstFld : 44|1@0+ (1,0) [0|1] "" TCP,CSM
 SG_ DTCI_FOPM_PndngDTC : 45|1@0+ (1,0) [0|1] "" TCP,CSM
 SG_ DTCI_FOPM_DTCTriggered : 46|1@0+ (1,0) [0|1] "" TCP,CSM
 SG_ DTCI_FOPM_WrnIndTrggrd : 54|1@0+ (1,0) [0|1] "" TCP,CSM
 SG_ DTCI_FOPM_WrnIndRqd : 55|1@0+ (1,0) [0|1] "" TCP,CSM

BO_ 1355 DTCInfo_FPI_PDU: 7 FPI
 SG_ DTCI_FPI_DTCFailType : 6|8@0+ (1,0) [0|255] "" TCP
 SG_ DTCI_FPI_CnfrmdDTC : 7|1@0+ (1,0) [0|1] "" TCP
 SG_ DTCI_FPI_DTCFaultType : 14|8@0+ (1,0) [0|3] "" TCP
 SG_ DTCI_FPI_DTCNumber : 22|16@0+ (1,0) [0|65535] "" TCP
 SG_ DTCI_FPI_DTCSource : 38|8@0+ (1,0) [0|255] "" CGM,TCP
 SG_ DTCI_FPI_TstNCmpltdOpCyc : 40|1@0+ (1,0) [0|1] "" TCP
 SG_ DTCI_FPI_TstNCmpltdLstClr : 41|1@0+ (1,0) [0|1] "" TCP
 SG_ DTCI_FPI_TstFldOpCyc : 42|1@0+ (1,0) [0|1] "" TCP
 SG_ DTCI_FPI_TstFldLstClr : 43|1@0+ (1,0) [0|1] "" TCP
 SG_ DTCI_FPI_TstFld : 44|1@0+ (1,0) [0|1] "" TCP
 SG_ DTCI_FPI_PndngDTC : 45|1@0+ (1,0) [0|1] "" TCP
 SG_ DTCI_FPI_DTCTriggered : 46|1@0+ (1,0) [0|1] "" TCP
 SG_ DTCI_FPI_WrnIndTrggrd : 54|1@0+ (1,0) [0|1] "" TCP
 SG_ DTCI_FPI_WrnIndRqd : 55|1@0+ (1,0) [0|1] "" TCP

BO_ 1220 DTCInfo_HDLM_PDU: 7 CGM
 SG_ DTCI_HDLM_DTCFailType : 6|8@0+ (1,0) [0|255] "" TCP,CSM
 SG_ DTCI_HDLM_CnfrmdDTC : 7|1@0+ (1,0) [0|1] "" TCP,CSM
 SG_ DTCI_HDLM_DTCFaultType : 14|8@0+ (1,0) [0|3] "" TCP,CSM
 SG_ DTCI_HDLM_DTCNumber : 22|16@0+ (1,0) [0|65535] "" TCP,CSM
 SG_ DTCI_HDLM_DTCSource : 38|8@0+ (1,0) [0|255] "" TCP,CSM
 SG_ DTCI_HDLM_TstNCmpltdOpCyc : 40|1@0+ (1,0) [0|1] "" TCP,CSM
 SG_ DTCI_HDLM_TstNCmpltdLstClr : 41|1@0+ (1,0) [0|1] "" TCP,CSM
 SG_ DTCI_HDLM_TstFldOpCyc : 42|1@0+ (1,0) [0|1] "" TCP,CSM
 SG_ DTCI_HDLM_TstFldLstClr : 43|1@0+ (1,0) [0|1] "" TCP,CSM
 SG_ DTCI_HDLM_TstFld : 44|1@0+ (1,0) [0|1] "" TCP,CSM
 SG_ DTCI_HDLM_PndngDTC : 45|1@0+ (1,0) [0|1] "" TCP,CSM
 SG_ DTCI_HDLM_DTCTriggered : 46|1@0+ (1,0) [0|1] "" TCP,CSM
 SG_ DTCI_HDLM_WrnIndTrggrd : 54|1@0+ (1,0) [0|1] "" TCP,CSM
 SG_ DTCI_HDLM_WrnIndRqd : 55|1@0+ (1,0) [0|1] "" TCP,CSM

BO_ 1846 DTCInfo_HUD_CAN_PDU: 7 CGM
 SG_ DTCI_HUD_CAN_DTCFailType : 6|8@0+ (1,0) [0|255] "" TCP,CSM
 SG_ DTCI_HUD_CAN_CnfrmdDTC : 7|1@0+ (1,0) [0|1] "" TCP,CSM
 SG_ DTCI_HUD_CAN_DTCFaultType : 14|8@0+ (1,0) [0|3] "" TCP,CSM
 SG_ DTCI_HUD_CAN_DTCNumber : 22|16@0+ (1,0) [0|65535] "" TCP,CSM
 SG_ DTCI_HUD_CAN_DTCSource : 38|8@0+ (1,0) [0|255] "" TCP,CSM
 SG_ DTCI_HUD_CAN_TstNCmpltdOpCyc : 40|1@0+ (1,0) [0|1] "" TCP,CSM
 SG_ DTCI_HUD_CAN_TstNCmpltdLstClr : 41|1@0+ (1,0) [0|1] "" TCP,CSM
 SG_ DTCI_HUD_CAN_TstFldOpCyc : 42|1@0+ (1,0) [0|1] "" TCP,CSM
 SG_ DTCI_HUD_CAN_TstFldLstClr : 43|1@0+ (1,0) [0|1] "" TCP,CSM
 SG_ DTCI_HUD_CAN_TstFld : 44|1@0+ (1,0) [0|1] "" TCP,CSM
 SG_ DTCI_HUD_CAN_PndngDTC : 45|1@0+ (1,0) [0|1] "" TCP,CSM
 SG_ DTCI_HUD_CAN_DTCTriggered : 46|1@0+ (1,0) [0|1] "" TCP,CSM
 SG_ DTCI_HUD_CAN_WrnIndTrggrd : 54|1@0+ (1,0) [0|1] "" TCP,CSM
 SG_ DTCI_HUD_CAN_WrnIndRqd : 55|1@0+ (1,0) [0|1] "" TCP,CSM

BA_DEF_ SG_  "SignalType" STRING ;
BA_DEF_ SG_  "SignalLongName" STRING ;
BA_DEF_ BO_  "GenMsgCycleTime" INT 0 10000;
BA_DEF_ BO_  "GenMsgSendType" ENUM "cyclicX","spontanX","cyclicIfActiveX","spontanWithDelay","cyclicAndSpontanX","cyclicAndSpontanWithDelay","spontanWithRepetition","cyclicIfActiveAndSpontanWD";
BA_DEF_DEF_  "SignalType" "";
BA_DEF_DEF_  "SignalLongName" "";
BA_DEF_DEF_  "GenMsgCycleTime" 0;
BA_DEF_DEF_  "GenMsgSendType" "cyclicX";
BA_ "GenMsgCycleTime" BO_ 525 50;
BA_ "GenMsgCycleTime" BO_ 1393 3500;
BA_ "GenMsgCycleTime" BO_ 1325 1000;
BA_ "GenMsgCycleTime" BO_ 618 100;
BA_ "GenMsgCycleTime" BO_ 1405 1000;
BA_ "GenMsgCycleTime" BO_ 880 250;
BA_ "GenMsgCycleTime" BO_ 1366 3500;
BA_ "GenMsgCycleTime" BO_ 1306 1000;
BA_ "GenMsgCycleTime" BO_ 1446 1000;
BA_ "GenMsgCycleTime" BO_ 1354 1000;
BA_ "GenMsgCycleTime" BO_ 1321 1000;
BA_ "GenMsgCycleTime" BO_ 1318 1000;
BA_ "GenMsgCycleTime" BO_ 1828 1000;
BA_ "GenMsgCycleTime" BO_ 1237 1000;
BA_ "GenMsgCycleTime" BO_ 1829 1000;
BA_ "GenMsgCycleTime" BO_ 1236 1000;
BA_ "GenMsgCycleTime" BO_ 1830 1000;
BA_ "GenMsgCycleTime" BO_ 1235 1000;
BA_ "GenMsgCycleTime" BO_ 1831 1000;
BA_ "GenMsgCycleTime" BO_ 1234 1000;
BA_ "GenMsgCycleTime" BO_ 1832 1000;
BA_ "GenMsgCycleTime" BO_ 1950 1000;
BA_ "GenMsgCycleTime" BO_ 1233 1000;
BA_ "GenMsgCycleTime" BO_ 1833 1000;
BA_ "GenMsgCycleTime" BO_ 1232 1000;
BA_ "GenMsgCycleTime" BO_ 1914 1000;
BA_ "GenMsgCycleTime" BO_ 1835 1000;
BA_ "GenMsgCycleTime" BO_ 1230 1000;
BA_ "GenMsgCycleTime" BO_ 1836 1000;
BA_ "GenMsgCycleTime" BO_ 1228 1000;
BA_ "GenMsgCycleTime" BO_ 1838 1000;
BA_ "GenMsgCycleTime" BO_ 1839 1000;
BA_ "GenMsgCycleTime" BO_ 1116 1000;
BA_ "GenMsgCycleTime" BO_ 1951 1000;
BA_ "GenMsgCycleTime" BO_ 1115 1000;
BA_ "GenMsgCycleTime" BO_ 1226 1000;
BA_ "GenMsgCycleTime" BO_ 1227 1000;
BA_ "GenMsgCycleTime" BO_ 1840 1000;
BA_ "GenMsgCycleTime" BO_ 1225 1000;
BA_ "GenMsgCycleTime" BO_ 1841 1000;
BA_ "GenMsgCycleTime" BO_ 1224 1000;
BA_ "GenMsgCycleTime" BO_ 1842 1000;
BA_ "GenMsgCycleTime" BO_ 1223 1000;
BA_ "GenMsgCycleTime" BO_ 1895 1000;
BA_ "GenMsgCycleTime" BO_ 1843 1000;
BA_ "GenMsgCycleTime" BO_ 1222 1000;
BA_ "GenMsgCycleTime" BO_ 1844 1000;
BA_ "GenMsgCycleTime" BO_ 1221 1000;
BA_ "GenMsgCycleTime" BO_ 1845 1000;
BA_ "GenMsgCycleTime" BO_ 1355 1000;
BA_ "GenMsgCycleTime" BO_ 1220 1000;
BA_ "GenMsgCycleTime" BO_ 1846 1000;
BA_ "SignalLongName" SG_ 925 APASts_PCSM "APA Status Protected Counter Sync Message";
BA_ "SignalLongName" SG_ 525 APASP_MAC "APA Status Protected : MAC";
BA_ "SignalLongName" SG_ 525 APASP_FCnt "APA Status Protected : Freshness Counter";
BA_ "SignalLongName" SG_ 525 APASP_APAStopDistAuth "APA Status Protected : Advanced Park Assist Stop Distance Authenticated";
BA_ "SignalLongName" SG_ 525 APASP_APAMaxVelAuth "APA Status Protected : Advanced Park Assist Maximum Velocity Authenticated";
BA_ "SignalType" SG_ 525 APASP_APAStsAuth "ENM";
BA_ "SignalLongName" SG_ 525 APASP_APAStsAuth "APA Status Protected : Advanced Park Assist Status Authenticated";
BA_ "SignalLongName" SG_ 525 APASP_ARC "APA Status Protected : Alive Rolling Count";
BA_ "SignalType" SG_ 525 APASP_APATransRngReqAuth "ENM";
BA_ "SignalLongName" SG_ 525 APASP_APATransRngReqAuth "APA Status Protected : Advanced Park Assist Transmission Range Request Authenticated";
BA_ "SignalType" SG_ 525 APASP_APATransRngActvnReqdAuth "ENM";
BA_ "SignalLongName" SG_ 525 APASP_APATransRngActvnReqdAuth "APA Status Protected : Advanced Park Assist Transmission Range Activation Requested Authenticated";
BA_ "SignalLongName" SG_ 1393 ActvSftyOprtrCrtclNtfns_PCSM "Active Safety Operator Critical Notifications Protected Counter Sync Message";
BA_ "SignalLongName" SG_ 1325 ASOCNP_MAC "Active Safety Operator Critical Notifications Protected : MAC";
BA_ "SignalLongName" SG_ 1325 ASOCNP_FCnt "Active Safety Operator Critical Notifications Protected : Freshness Counter";
BA_ "SignalType" SG_ 1325 HndsOnLnCntrAsstWrnIndReq "ENM";
BA_ "SignalLongName" SG_ 1325 HndsOnLnCntrAsstWrnIndReq "Active Safety Operator Critical Notifications Protected : Hands On Lane Centering Assist Warning Indication Request";
BA_ "SignalType" SG_ 1325 SuprRmtPrkPwrModeReq "ENM";
BA_ "SignalLongName" SG_ 1325 SuprRmtPrkPwrModeReq "Active Safety Operator Critical Notifications Protected : Supervised Remote Parking Power Mode Request";
BA_ "SignalType" SG_ 1325 SuprRmtPrkDrLckReq "ENM";
BA_ "SignalLongName" SG_ 1325 SuprRmtPrkDrLckReq "Active Safety Operator Critical Notifications Protected : Supervised Remote Parking Door Lock Request";
BA_ "SignalLongName" SG_ 1325 ASOCNP_ARC "Active Safety Operator Critical Notifications Protected : Alive Rolling Count";
BA_ "SignalType" SG_ 1325 ASOCNP_LKATakeStrgIndOnAuth "ENM";
BA_ "SignalLongName" SG_ 1325 ASOCNP_LKATakeStrgIndOnAuth "Active Safety Operator Critical Notifications Protected : Lane Keep Assist Take Steering Indication On Authenticated";
BA_ "SignalLongName" SG_ 1325 ASOCNP_Filler "Active Safety Operator Critical Notifications Protected : Filler";
BA_ "SignalType" SG_ 618 BGI2P_WshFldLvlIndOnAuth "ENM";
BA_ "SignalLongName" SG_ 618 BGI2P_WshFldLvlIndOnAuth "Body General Information 2 Protected : Wash Fluid Level Indication On Authenticated";
BA_ "SignalType" SG_ 618 BGI2P_ServWprSysDrvIndOnAuth "ENM";
BA_ "SignalLongName" SG_ 618 BGI2P_ServWprSysDrvIndOnAuth "Body General Information 2 Protected : Service Wiper System Drive Indication On Authenticated";
BA_ "SignalLongName" SG_ 1405 BkupSysPwrMode_PCSM "Backup System Power Mode Protected Counter Sync Message";
BA_ "SignalLongName" SG_ 880 BSPMP_MAC "Backup System Power Mode Protected : MAC";
BA_ "SignalLongName" SG_ 880 BSPMP_FCnt "Backup System Power Mode Protected : Freshness Counter";
BA_ "SignalLongName" SG_ 880 BSPMP_PV "Backup System Power Mode Protected : Protection Value";
BA_ "SignalType" SG_ 880 BSPMP_BkupSysPwrModeAuth_Inv "ENM";
BA_ "SignalLongName" SG_ 880 BSPMP_BkupSysPwrModeAuth_Inv "Backup System Power Mode Protected : Backup System Power Mode Authenticated Invalid";
BA_ "SignalType" SG_ 880 BSPMP_BkupSysPwrModeAuth "ENM";
BA_ "SignalLongName" SG_ 880 BSPMP_BkupSysPwrModeAuth "Backup System Power Mode Protected : Backup System Power Mode Authenticated";
BA_ "SignalLongName" SG_ 880 BSPMP_ARC "Backup System Power Mode Protected : Alive Rolling Count";
BA_ "SignalType" SG_ 880 BSPMP_SecRunCrnkCmdActvAuth_Inv "ENM";
BA_ "SignalLongName" SG_ 880 BSPMP_SecRunCrnkCmdActvAuth_Inv "Backup System Power Mode Protected : Secondary Run Crank Command Active Invalid Authenticated";
BA_ "SignalType" SG_ 880 BSPMP_SecRunCrnkCmdActvAuth "ENM";
BA_ "SignalLongName" SG_ 880 BSPMP_SecRunCrnkCmdActvAuth "Backup System Power Mode Protected : Secondary Run Crank Command Active Authenticated";
BA_ "SignalType" SG_ 880 BSPMP_SecPwrModePBActvAuth_Inv "ENM";
BA_ "SignalLongName" SG_ 880 BSPMP_SecPwrModePBActvAuth_Inv "Backup System Power Mode Protected : Secondary Power Mode Pushbutton Active Authenticated Invalid";
BA_ "SignalType" SG_ 880 BSPMP_SecPwrModePBActvAuth "ENM";
BA_ "SignalLongName" SG_ 880 BSPMP_SecPwrModePBActvAuth "Backup System Power Mode Protected : Secondary Power Mode Pushbutton Active Authenticated";
BA_ "SignalType" SG_ 880 BSPMP_RmtProgmActvAuth "ENM";
BA_ "SignalLongName" SG_ 880 BSPMP_RmtProgmActvAuth "Backup System Power Mode Protected : Remote Programming Active Authenticated";
BA_ "SignalLongName" SG_ 1366 BrkSysDispInfo_PCSM "Brake System Display Information Protected Counter Sync Message";
BA_ "SignalLongName" SG_ 1306 BSDIP_MAC "Brake System Display Information Protected : MAC";
BA_ "SignalLongName" SG_ 1306 BSDIP_FCnt "Brake System Display Information Protected : Freshness Counter";
BA_ "SignalType" SG_ 1306 BSDIP_ESCOffVisIndOnAuth "ENM";
BA_ "SignalLongName" SG_ 1306 BSDIP_ESCOffVisIndOnAuth "Brake System Display Information Protected : Electronic Stability Control Off Visual Indication On Authenticated";
BA_ "SignalType" SG_ 1306 BSDIP_EPBSysWrnIndReqAuth "ENM";
BA_ "SignalLongName" SG_ 1306 BSDIP_EPBSysWrnIndReqAuth "Brake System Display Information Protected : Electric Park Brake System Warning Indication Request Authenticated";
BA_ "SignalType" SG_ 1306 BSDIP_EPBSysStsIndReqAuth "ENM";
BA_ "SignalLongName" SG_ 1306 BSDIP_EPBSysStsIndReqAuth "Brake System Display Information Protected : Electric Park Brake System Status Indication Request Authenticated";
BA_ "SignalType" SG_ 1306 BSDIP_ABSIndOnAuth "ENM";
BA_ "SignalLongName" SG_ 1306 BSDIP_ABSIndOnAuth "Brake System Display Information Protected : Antilock Brake System Indication On Authenticated";
BA_ "SignalLongName" SG_ 1306 BSDIP_ARC "Brake System Display Information Protected : Alive Rolling Count";
BA_ "SignalType" SG_ 1306 BSDIP_TracCtlOffVisIndOnAuth "ENM";
BA_ "SignalLongName" SG_ 1306 BSDIP_TracCtlOffVisIndOnAuth "Brake System Display Information Protected : Traction Control Off Visual Indicator On Authenticated";
BA_ "SignalType" SG_ 1306 BSDIP_SrvBrkRdBrkTTShrtChIOAuth "ENM";
BA_ "SignalLongName" SG_ 1306 BSDIP_SrvBrkRdBrkTTShrtChIOAuth "Brake System Display Information Protected : Service Brakes Red Brake Telltale Short Chime Indication On Authenticated";
BA_ "SignalType" SG_ 1306 BSDIP_ServBrkRdBrkTTLngChIOAuth "ENM";
BA_ "SignalLongName" SG_ 1306 BSDIP_ServBrkRdBrkTTLngChIOAuth "Brake System Display Information Protected : Service Brakes Red Brake Telltale Long Chime Indication On Authenticated";
BA_ "SignalType" SG_ 1306 BSDIP_ServBrkBstSrvBrkAssIOAuth "ENM";
BA_ "SignalLongName" SG_ 1306 BSDIP_ServBrkBstSrvBrkAssIOAuth "Brake System Display Information Protected : Service Brake Boost Service Brake Assist Indication On Authenticated";
BA_ "SignalType" SG_ 1306 BSDIP_ESCVisIndReqAuth "ENM";
BA_ "SignalLongName" SG_ 1306 BSDIP_ESCVisIndReqAuth "Brake System Display Information Protected : Electronic Stability Control Visual Indication Request Authenticated";
BA_ "SignalLongName" SG_ 1306 BSDIP_Filler "Brake System Display Information Protected : Filler";
BA_ "SignalType" SG_ 1306 BrkSysBstWrnIndReq "ENM";
BA_ "SignalLongName" SG_ 1306 BrkSysBstWrnIndReq "Brake System Display Information Protected : Brake System Boost Warning Indication Request";
BA_ "SignalLongName" SG_ 1446 CRI_ChmPrdcrReq "Chime Request Information : Chime Producer Request";
BA_ "SignalLongName" SG_ 1446 CRI_CS "Chime Request Information : Checksum";
BA_ "SignalLongName" SG_ 1446 CRI_ARC "Chime Request Information : Alive Rolling Count";
BA_ "SignalLongName" SG_ 1354 DTCI_ACP2_MCU_DTCFailType "Diagnostic Trouble Code Information Extended - ACP2_MCU : Diagnostic Trouble Code Failure Type";
BA_ "SignalType" SG_ 1354 DTCI_ACP2_MCU_CnfrmdDTC "ENM";
BA_ "SignalLongName" SG_ 1354 DTCI_ACP2_MCU_CnfrmdDTC "Diagnostic Trouble Code Information Extended - ACP2_MCU : Confirmed DTC";
BA_ "SignalType" SG_ 1354 DTCI_ACP2_MCU_DTCFaultType "ENM";
BA_ "SignalLongName" SG_ 1354 DTCI_ACP2_MCU_DTCFaultType "Diagnostic Trouble Code Information Extended - ACP2_MCU : Diagnostic Trouble Code Fault Type";
BA_ "SignalLongName" SG_ 1354 DTCI_ACP2_MCU_DTCNumber "Diagnostic Trouble Code Information Extended - ACP2_MCU : Diagnostic Trouble Code Number";
BA_ "SignalLongName" SG_ 1354 DTCI_ACP2_MCU_DTCSource "Diagnostic Trouble Code Information Extended - ACP2_MCU : Diagnostic Trouble Code Source";
BA_ "SignalType" SG_ 1354 DTCI_ACP2_MCU_TstNCmpltdOpCyc "ENM";
BA_ "SignalLongName" SG_ 1354 DTCI_ACP2_MCU_TstNCmpltdOpCyc "Diagnostic Trouble Code Information Extended - ACP2_MCU : Test Not Completed This Operation Cycle";
BA_ "SignalType" SG_ 1354 DTCI_ACP2_MCU_TstNCmpltdLstClr "ENM";
BA_ "SignalLongName" SG_ 1354 DTCI_ACP2_MCU_TstNCmpltdLstClr "Diagnostic Trouble Code Information Extended - ACP2_MCU : Test Not Completed Since Last Clear";
BA_ "SignalType" SG_ 1354 DTCI_ACP2_MCU_TstFldOpCyc "ENM";
BA_ "SignalLongName" SG_ 1354 DTCI_ACP2_MCU_TstFldOpCyc "Diagnostic Trouble Code Information Extended - ACP2_MCU : Test Failed This Operation Cycle";
BA_ "SignalType" SG_ 1354 DTCI_ACP2_MCU_TstFldLstClr "ENM";
BA_ "SignalLongName" SG_ 1354 DTCI_ACP2_MCU_TstFldLstClr "Diagnostic Trouble Code Information Extended - ACP2_MCU : Test Failed Since Last Clear";
BA_ "SignalType" SG_ 1354 DTCI_ACP2_MCU_TstFld "ENM";
BA_ "SignalLongName" SG_ 1354 DTCI_ACP2_MCU_TstFld "Diagnostic Trouble Code Information Extended - ACP2_MCU : Test Failed";
BA_ "SignalType" SG_ 1354 DTCI_ACP2_MCU_PndngDTC "ENM";
BA_ "SignalLongName" SG_ 1354 DTCI_ACP2_MCU_PndngDTC "Diagnostic Trouble Code Information Extended - ACP2_MCU : Pending DTC";
BA_ "SignalType" SG_ 1354 DTCI_ACP2_MCU_DTCTriggered "ENM";
BA_ "SignalLongName" SG_ 1354 DTCI_ACP2_MCU_DTCTriggered "Diagnostic Trouble Code Information Extended - ACP2_MCU : Diagnostic Trouble Code Triggered";
BA_ "SignalType" SG_ 1354 DTCI_ACP2_MCU_WrnIndTrggrd "ENM";
BA_ "SignalLongName" SG_ 1354 DTCI_ACP2_MCU_WrnIndTrggrd "Diagnostic Trouble Code Information Extended - ACP2_MCU : Warning Indicator Triggered";
BA_ "SignalType" SG_ 1354 DTCI_ACP2_MCU_WrnIndRqd "ENM";
BA_ "SignalLongName" SG_ 1354 DTCI_ACP2_MCU_WrnIndRqd "Diagnostic Trouble Code Information Extended - ACP2_MCU : Warning Indicator Requested";
BA_ "SignalLongName" SG_ 1321 DTCI_ACP3_MCU_DTCFailType "Diagnostic Trouble Code Information Extended - ACP3_MCU : Diagnostic Trouble Code Failure Type";
BA_ "SignalType" SG_ 1321 DTCI_ACP3_MCU_CnfrmdDTC "ENM";
BA_ "SignalLongName" SG_ 1321 DTCI_ACP3_MCU_CnfrmdDTC "Diagnostic Trouble Code Information Extended - ACP3_MCU : Confirmed DTC";
BA_ "SignalType" SG_ 1321 DTCI_ACP3_MCU_DTCFaultType "ENM";
BA_ "SignalLongName" SG_ 1321 DTCI_ACP3_MCU_DTCFaultType "Diagnostic Trouble Code Information Extended - ACP3_MCU : Diagnostic Trouble Code Fault Type";
BA_ "SignalLongName" SG_ 1321 DTCI_ACP3_MCU_DTCNumber "Diagnostic Trouble Code Information Extended - ACP3_MCU : Diagnostic Trouble Code Number";
BA_ "SignalLongName" SG_ 1321 DTCI_ACP3_MCU_DTCSource "Diagnostic Trouble Code Information Extended - ACP3_MCU : Diagnostic Trouble Code Source";
BA_ "SignalType" SG_ 1321 DTCI_ACP3_MCU_TstNCmpltdOpCyc "ENM";
BA_ "SignalLongName" SG_ 1321 DTCI_ACP3_MCU_TstNCmpltdOpCyc "Diagnostic Trouble Code Information Extended - ACP3_MCU : Test Not Completed This Operation Cycle";
BA_ "SignalType" SG_ 1321 DTCI_ACP3_MCU_TstNCmpltdLstClr "ENM";
BA_ "SignalLongName" SG_ 1321 DTCI_ACP3_MCU_TstNCmpltdLstClr "Diagnostic Trouble Code Information Extended - ACP3_MCU : Test Not Completed Since Last Clear";
BA_ "SignalType" SG_ 1321 DTCI_ACP3_MCU_TstFldOpCyc "ENM";
BA_ "SignalLongName" SG_ 1321 DTCI_ACP3_MCU_TstFldOpCyc "Diagnostic Trouble Code Information Extended - ACP3_MCU : Test Failed This Operation Cycle";
BA_ "SignalType" SG_ 1321 DTCI_ACP3_MCU_TstFldLstClr "ENM";
BA_ "SignalLongName" SG_ 1321 DTCI_ACP3_MCU_TstFldLstClr "Diagnostic Trouble Code Information Extended - ACP3_MCU : Test Failed Since Last Clear";
BA_ "SignalType" SG_ 1321 DTCI_ACP3_MCU_TstFld "ENM";
BA_ "SignalLongName" SG_ 1321 DTCI_ACP3_MCU_TstFld "Diagnostic Trouble Code Information Extended - ACP3_MCU : Test Failed";
BA_ "SignalType" SG_ 1321 DTCI_ACP3_MCU_PndngDTC "ENM";
BA_ "SignalLongName" SG_ 1321 DTCI_ACP3_MCU_PndngDTC "Diagnostic Trouble Code Information Extended - ACP3_MCU : Pending DTC";
BA_ "SignalType" SG_ 1321 DTCI_ACP3_MCU_DTCTriggered "ENM";
BA_ "SignalLongName" SG_ 1321 DTCI_ACP3_MCU_DTCTriggered "Diagnostic Trouble Code Information Extended - ACP3_MCU : Diagnostic Trouble Code Triggered";
BA_ "SignalType" SG_ 1321 DTCI_ACP3_MCU_WrnIndTrggrd "ENM";
BA_ "SignalLongName" SG_ 1321 DTCI_ACP3_MCU_WrnIndTrggrd "Diagnostic Trouble Code Information Extended - ACP3_MCU : Warning Indicator Triggered";
BA_ "SignalType" SG_ 1321 DTCI_ACP3_MCU_WrnIndRqd "ENM";
BA_ "SignalLongName" SG_ 1321 DTCI_ACP3_MCU_WrnIndRqd "Diagnostic Trouble Code Information Extended - ACP3_MCU : Warning Indicator Requested";
BA_ "SignalLongName" SG_ 1318 DTCI_ACP4_MCU_DTCFailType "Diagnostic Trouble Code Information Extended - ACP4_MCU : Diagnostic Trouble Code Failure Type";
BA_ "SignalType" SG_ 1318 DTCI_ACP4_MCU_CnfrmdDTC "ENM";
BA_ "SignalLongName" SG_ 1318 DTCI_ACP4_MCU_CnfrmdDTC "Diagnostic Trouble Code Information Extended - ACP4_MCU : Confirmed DTC";
BA_ "SignalType" SG_ 1318 DTCI_ACP4_MCU_DTCFaultType "ENM";
BA_ "SignalLongName" SG_ 1318 DTCI_ACP4_MCU_DTCFaultType "Diagnostic Trouble Code Information Extended - ACP4_MCU : Diagnostic Trouble Code Fault Type";
BA_ "SignalLongName" SG_ 1318 DTCI_ACP4_MCU_DTCNumber "Diagnostic Trouble Code Information Extended - ACP4_MCU : Diagnostic Trouble Code Number";
BA_ "SignalLongName" SG_ 1318 DTCI_ACP4_MCU_DTCSource "Diagnostic Trouble Code Information Extended - ACP4_MCU : Diagnostic Trouble Code Source";
BA_ "SignalType" SG_ 1318 DTCI_ACP4_MCU_TstNCmpltdOpCyc "ENM";
BA_ "SignalLongName" SG_ 1318 DTCI_ACP4_MCU_TstNCmpltdOpCyc "Diagnostic Trouble Code Information Extended - ACP4_MCU : Test Not Completed This Operation Cycle";
BA_ "SignalType" SG_ 1318 DTCI_ACP4_MCU_TstNCmpltdLstClr "ENM";
BA_ "SignalLongName" SG_ 1318 DTCI_ACP4_MCU_TstNCmpltdLstClr "Diagnostic Trouble Code Information Extended - ACP4_MCU : Test Not Completed Since Last Clear";
BA_ "SignalType" SG_ 1318 DTCI_ACP4_MCU_TstFldOpCyc "ENM";
BA_ "SignalLongName" SG_ 1318 DTCI_ACP4_MCU_TstFldOpCyc "Diagnostic Trouble Code Information Extended - ACP4_MCU : Test Failed This Operation Cycle";
BA_ "SignalType" SG_ 1318 DTCI_ACP4_MCU_TstFldLstClr "ENM";
BA_ "SignalLongName" SG_ 1318 DTCI_ACP4_MCU_TstFldLstClr "Diagnostic Trouble Code Information Extended - ACP4_MCU : Test Failed Since Last Clear";
BA_ "SignalType" SG_ 1318 DTCI_ACP4_MCU_TstFld "ENM";
BA_ "SignalLongName" SG_ 1318 DTCI_ACP4_MCU_TstFld "Diagnostic Trouble Code Information Extended - ACP4_MCU : Test Failed";
BA_ "SignalType" SG_ 1318 DTCI_ACP4_MCU_PndngDTC "ENM";
BA_ "SignalLongName" SG_ 1318 DTCI_ACP4_MCU_PndngDTC "Diagnostic Trouble Code Information Extended - ACP4_MCU : Pending DTC";
BA_ "SignalType" SG_ 1318 DTCI_ACP4_MCU_DTCTriggered "ENM";
BA_ "SignalLongName" SG_ 1318 DTCI_ACP4_MCU_DTCTriggered "Diagnostic Trouble Code Information Extended - ACP4_MCU : Diagnostic Trouble Code Triggered";
BA_ "SignalType" SG_ 1318 DTCI_ACP4_MCU_WrnIndTrggrd "ENM";
BA_ "SignalLongName" SG_ 1318 DTCI_ACP4_MCU_WrnIndTrggrd "Diagnostic Trouble Code Information Extended - ACP4_MCU : Warning Indicator Triggered";
BA_ "SignalType" SG_ 1318 DTCI_ACP4_MCU_WrnIndRqd "ENM";
BA_ "SignalLongName" SG_ 1318 DTCI_ACP4_MCU_WrnIndRqd "Diagnostic Trouble Code Information Extended - ACP4_MCU : Warning Indicator Requested";
BA_ "SignalLongName" SG_ 1828 DTCI_AHL_AFL_DTCFailType "Diagnostic Trouble Code Information Extended - AHL_AFL : Diagnostic Trouble Code Failure Type";
BA_ "SignalType" SG_ 1828 DTCI_AHL_AFL_CnfrmdDTC "ENM";
BA_ "SignalLongName" SG_ 1828 DTCI_AHL_AFL_CnfrmdDTC "Diagnostic Trouble Code Information Extended - AHL_AFL : Confirmed DTC";
BA_ "SignalType" SG_ 1828 DTCI_AHL_AFL_DTCFaultType "ENM";
BA_ "SignalLongName" SG_ 1828 DTCI_AHL_AFL_DTCFaultType "Diagnostic Trouble Code Information Extended - AHL_AFL : Diagnostic Trouble Code Fault Type";
BA_ "SignalLongName" SG_ 1828 DTCI_AHL_AFL_DTCNumber "Diagnostic Trouble Code Information Extended - AHL_AFL : Diagnostic Trouble Code Number";
BA_ "SignalLongName" SG_ 1828 DTCI_AHL_AFL_DTCSource "Diagnostic Trouble Code Information Extended - AHL_AFL : Diagnostic Trouble Code Source";
BA_ "SignalType" SG_ 1828 DTCI_AHL_AFL_TstNCmpltdOpCyc "ENM";
BA_ "SignalLongName" SG_ 1828 DTCI_AHL_AFL_TstNCmpltdOpCyc "Diagnostic Trouble Code Information Extended - AHL_AFL : Test Not Completed This Operation Cycle";
BA_ "SignalType" SG_ 1828 DTCI_AHL_AFL_TstNCmpltdLstClr "ENM";
BA_ "SignalLongName" SG_ 1828 DTCI_AHL_AFL_TstNCmpltdLstClr "Diagnostic Trouble Code Information Extended - AHL_AFL : Test Not Completed Since Last Clear";
BA_ "SignalType" SG_ 1828 DTCI_AHL_AFL_TstFldOpCyc "ENM";
BA_ "SignalLongName" SG_ 1828 DTCI_AHL_AFL_TstFldOpCyc "Diagnostic Trouble Code Information Extended - AHL_AFL : Test Failed This Operation Cycle";
BA_ "SignalType" SG_ 1828 DTCI_AHL_AFL_TstFldLstClr "ENM";
BA_ "SignalLongName" SG_ 1828 DTCI_AHL_AFL_TstFldLstClr "Diagnostic Trouble Code Information Extended - AHL_AFL : Test Failed Since Last Clear";
BA_ "SignalType" SG_ 1828 DTCI_AHL_AFL_TstFld "ENM";
BA_ "SignalLongName" SG_ 1828 DTCI_AHL_AFL_TstFld "Diagnostic Trouble Code Information Extended - AHL_AFL : Test Failed";
BA_ "SignalType" SG_ 1828 DTCI_AHL_AFL_PndngDTC "ENM";
BA_ "SignalLongName" SG_ 1828 DTCI_AHL_AFL_PndngDTC "Diagnostic Trouble Code Information Extended - AHL_AFL : Pending DTC";
BA_ "SignalType" SG_ 1828 DTCI_AHL_AFL_DTCTriggered "ENM";
BA_ "SignalLongName" SG_ 1828 DTCI_AHL_AFL_DTCTriggered "Diagnostic Trouble Code Information Extended - AHL_AFL : Diagnostic Trouble Code Triggered";
BA_ "SignalType" SG_ 1828 DTCI_AHL_AFL_WrnIndTrggrd "ENM";
BA_ "SignalLongName" SG_ 1828 DTCI_AHL_AFL_WrnIndTrggrd "Diagnostic Trouble Code Information Extended - AHL_AFL : Warning Indicator Triggered";
BA_ "SignalType" SG_ 1828 DTCI_AHL_AFL_WrnIndRqd "ENM";
BA_ "SignalLongName" SG_ 1828 DTCI_AHL_AFL_WrnIndRqd "Diagnostic Trouble Code Information Extended - AHL_AFL : Warning Indicator Requested";
BA_ "SignalLongName" SG_ 1237 DTCI_AHS_DTCFailType "Diagnostic Trouble Code Information Extended - AHS : Diagnostic Trouble Code Failure Type";
BA_ "SignalType" SG_ 1237 DTCI_AHS_CnfrmdDTC "ENM";
BA_ "SignalLongName" SG_ 1237 DTCI_AHS_CnfrmdDTC "Diagnostic Trouble Code Information Extended - AHS : Confirmed DTC";
BA_ "SignalType" SG_ 1237 DTCI_AHS_DTCFaultType "ENM";
BA_ "SignalLongName" SG_ 1237 DTCI_AHS_DTCFaultType "Diagnostic Trouble Code Information Extended - AHS : Diagnostic Trouble Code Fault Type";
BA_ "SignalLongName" SG_ 1237 DTCI_AHS_DTCNumber "Diagnostic Trouble Code Information Extended - AHS : Diagnostic Trouble Code Number";
BA_ "SignalLongName" SG_ 1237 DTCI_AHS_DTCSource "Diagnostic Trouble Code Information Extended - AHS : Diagnostic Trouble Code Source";
BA_ "SignalType" SG_ 1237 DTCI_AHS_TstNCmpltdOpCyc "ENM";
BA_ "SignalLongName" SG_ 1237 DTCI_AHS_TstNCmpltdOpCyc "Diagnostic Trouble Code Information Extended - AHS : Test Not Completed This Operation Cycle";
BA_ "SignalType" SG_ 1237 DTCI_AHS_TstNCmpltdLstClr "ENM";
BA_ "SignalLongName" SG_ 1237 DTCI_AHS_TstNCmpltdLstClr "Diagnostic Trouble Code Information Extended - AHS : Test Not Completed Since Last Clear";
BA_ "SignalType" SG_ 1237 DTCI_AHS_TstFldOpCyc "ENM";
BA_ "SignalLongName" SG_ 1237 DTCI_AHS_TstFldOpCyc "Diagnostic Trouble Code Information Extended - AHS : Test Failed This Operation Cycle";
BA_ "SignalType" SG_ 1237 DTCI_AHS_TstFldLstClr "ENM";
BA_ "SignalLongName" SG_ 1237 DTCI_AHS_TstFldLstClr "Diagnostic Trouble Code Information Extended - AHS : Test Failed Since Last Clear";
BA_ "SignalType" SG_ 1237 DTCI_AHS_TstFld "ENM";
BA_ "SignalLongName" SG_ 1237 DTCI_AHS_TstFld "Diagnostic Trouble Code Information Extended - AHS : Test Failed";
BA_ "SignalType" SG_ 1237 DTCI_AHS_PndngDTC "ENM";
BA_ "SignalLongName" SG_ 1237 DTCI_AHS_PndngDTC "Diagnostic Trouble Code Information Extended - AHS : Pending DTC";
BA_ "SignalType" SG_ 1237 DTCI_AHS_DTCTriggered "ENM";
BA_ "SignalLongName" SG_ 1237 DTCI_AHS_DTCTriggered "Diagnostic Trouble Code Information Extended - AHS : Diagnostic Trouble Code Triggered";
BA_ "SignalType" SG_ 1237 DTCI_AHS_WrnIndTrggrd "ENM";
BA_ "SignalLongName" SG_ 1237 DTCI_AHS_WrnIndTrggrd "Diagnostic Trouble Code Information Extended - AHS : Warning Indicator Triggered";
BA_ "SignalType" SG_ 1237 DTCI_AHS_WrnIndRqd "ENM";
BA_ "SignalLongName" SG_ 1237 DTCI_AHS_WrnIndRqd "Diagnostic Trouble Code Information Extended - AHS : Warning Indicator Requested";
BA_ "SignalLongName" SG_ 1829 DTCI_ALC_DTCFailType "Diagnostic Trouble Code Information Extended - ALC : Diagnostic Trouble Code Failure Type";
BA_ "SignalType" SG_ 1829 DTCI_ALC_CnfrmdDTC "ENM";
BA_ "SignalLongName" SG_ 1829 DTCI_ALC_CnfrmdDTC "Diagnostic Trouble Code Information Extended - ALC : Confirmed DTC";
BA_ "SignalType" SG_ 1829 DTCI_ALC_DTCFaultType "ENM";
BA_ "SignalLongName" SG_ 1829 DTCI_ALC_DTCFaultType "Diagnostic Trouble Code Information Extended - ALC : Diagnostic Trouble Code Fault Type";
BA_ "SignalLongName" SG_ 1829 DTCI_ALC_DTCNumber "Diagnostic Trouble Code Information Extended - ALC : Diagnostic Trouble Code Number";
BA_ "SignalLongName" SG_ 1829 DTCI_ALC_DTCSource "Diagnostic Trouble Code Information Extended - ALC : Diagnostic Trouble Code Source";
BA_ "SignalType" SG_ 1829 DTCI_ALC_TstNCmpltdOpCyc "ENM";
BA_ "SignalLongName" SG_ 1829 DTCI_ALC_TstNCmpltdOpCyc "Diagnostic Trouble Code Information Extended - ALC : Test Not Completed This Operation Cycle";
BA_ "SignalType" SG_ 1829 DTCI_ALC_TstNCmpltdLstClr "ENM";
BA_ "SignalLongName" SG_ 1829 DTCI_ALC_TstNCmpltdLstClr "Diagnostic Trouble Code Information Extended - ALC : Test Not Completed Since Last Clear";
BA_ "SignalType" SG_ 1829 DTCI_ALC_TstFldOpCyc "ENM";
BA_ "SignalLongName" SG_ 1829 DTCI_ALC_TstFldOpCyc "Diagnostic Trouble Code Information Extended - ALC : Test Failed This Operation Cycle";
BA_ "SignalType" SG_ 1829 DTCI_ALC_TstFldLstClr "ENM";
BA_ "SignalLongName" SG_ 1829 DTCI_ALC_TstFldLstClr "Diagnostic Trouble Code Information Extended - ALC : Test Failed Since Last Clear";
BA_ "SignalType" SG_ 1829 DTCI_ALC_TstFld "ENM";
BA_ "SignalLongName" SG_ 1829 DTCI_ALC_TstFld "Diagnostic Trouble Code Information Extended - ALC : Test Failed";
BA_ "SignalType" SG_ 1829 DTCI_ALC_PndngDTC "ENM";
BA_ "SignalLongName" SG_ 1829 DTCI_ALC_PndngDTC "Diagnostic Trouble Code Information Extended - ALC : Pending DTC";
BA_ "SignalType" SG_ 1829 DTCI_ALC_DTCTriggered "ENM";
BA_ "SignalLongName" SG_ 1829 DTCI_ALC_DTCTriggered "Diagnostic Trouble Code Information Extended - ALC : Diagnostic Trouble Code Triggered";
BA_ "SignalType" SG_ 1829 DTCI_ALC_WrnIndTrggrd "ENM";
BA_ "SignalLongName" SG_ 1829 DTCI_ALC_WrnIndTrggrd "Diagnostic Trouble Code Information Extended - ALC : Warning Indicator Triggered";
BA_ "SignalType" SG_ 1829 DTCI_ALC_WrnIndRqd "ENM";
BA_ "SignalLongName" SG_ 1829 DTCI_ALC_WrnIndRqd "Diagnostic Trouble Code Information Extended - ALC : Warning Indicator Requested";
BA_ "SignalLongName" SG_ 1236 DTCI_AMP_DTCFailType "Diagnostic Trouble Code Information Extended - AMP : Diagnostic Trouble Code Failure Type";
BA_ "SignalType" SG_ 1236 DTCI_AMP_CnfrmdDTC "ENM";
BA_ "SignalLongName" SG_ 1236 DTCI_AMP_CnfrmdDTC "Diagnostic Trouble Code Information Extended - AMP : Confirmed DTC";
BA_ "SignalType" SG_ 1236 DTCI_AMP_DTCFaultType "ENM";
BA_ "SignalLongName" SG_ 1236 DTCI_AMP_DTCFaultType "Diagnostic Trouble Code Information Extended - AMP : Diagnostic Trouble Code Fault Type";
BA_ "SignalLongName" SG_ 1236 DTCI_AMP_DTCNumber "Diagnostic Trouble Code Information Extended - AMP : Diagnostic Trouble Code Number";
BA_ "SignalLongName" SG_ 1236 DTCI_AMP_DTCSource "Diagnostic Trouble Code Information Extended - AMP : Diagnostic Trouble Code Source";
BA_ "SignalType" SG_ 1236 DTCI_AMP_TstNCmpltdOpCyc "ENM";
BA_ "SignalLongName" SG_ 1236 DTCI_AMP_TstNCmpltdOpCyc "Diagnostic Trouble Code Information Extended - AMP : Test Not Completed This Operation Cycle";
BA_ "SignalType" SG_ 1236 DTCI_AMP_TstNCmpltdLstClr "ENM";
BA_ "SignalLongName" SG_ 1236 DTCI_AMP_TstNCmpltdLstClr "Diagnostic Trouble Code Information Extended - AMP : Test Not Completed Since Last Clear";
BA_ "SignalType" SG_ 1236 DTCI_AMP_TstFldOpCyc "ENM";
BA_ "SignalLongName" SG_ 1236 DTCI_AMP_TstFldOpCyc "Diagnostic Trouble Code Information Extended - AMP : Test Failed This Operation Cycle";
BA_ "SignalType" SG_ 1236 DTCI_AMP_TstFldLstClr "ENM";
BA_ "SignalLongName" SG_ 1236 DTCI_AMP_TstFldLstClr "Diagnostic Trouble Code Information Extended - AMP : Test Failed Since Last Clear";
BA_ "SignalType" SG_ 1236 DTCI_AMP_TstFld "ENM";
BA_ "SignalLongName" SG_ 1236 DTCI_AMP_TstFld "Diagnostic Trouble Code Information Extended - AMP : Test Failed";
BA_ "SignalType" SG_ 1236 DTCI_AMP_PndngDTC "ENM";
BA_ "SignalLongName" SG_ 1236 DTCI_AMP_PndngDTC "Diagnostic Trouble Code Information Extended - AMP : Pending DTC";
BA_ "SignalType" SG_ 1236 DTCI_AMP_DTCTriggered "ENM";
BA_ "SignalLongName" SG_ 1236 DTCI_AMP_DTCTriggered "Diagnostic Trouble Code Information Extended - AMP : Diagnostic Trouble Code Triggered";
BA_ "SignalType" SG_ 1236 DTCI_AMP_WrnIndTrggrd "ENM";
BA_ "SignalLongName" SG_ 1236 DTCI_AMP_WrnIndTrggrd "Diagnostic Trouble Code Information Extended - AMP : Warning Indicator Triggered";
BA_ "SignalType" SG_ 1236 DTCI_AMP_WrnIndRqd "ENM";
BA_ "SignalLongName" SG_ 1236 DTCI_AMP_WrnIndRqd "Diagnostic Trouble Code Information Extended - AMP : Warning Indicator Requested";
BA_ "SignalLongName" SG_ 1830 DTCI_AOS_DTCFailType "Diagnostic Trouble Code Information Extended - AOS : Diagnostic Trouble Code Failure Type";
BA_ "SignalType" SG_ 1830 DTCI_AOS_CnfrmdDTC "ENM";
BA_ "SignalLongName" SG_ 1830 DTCI_AOS_CnfrmdDTC "Diagnostic Trouble Code Information Extended - AOS : Confirmed DTC";
BA_ "SignalType" SG_ 1830 DTCI_AOS_DTCFaultType "ENM";
BA_ "SignalLongName" SG_ 1830 DTCI_AOS_DTCFaultType "Diagnostic Trouble Code Information Extended - AOS : Diagnostic Trouble Code Fault Type";
BA_ "SignalLongName" SG_ 1830 DTCI_AOS_DTCNumber "Diagnostic Trouble Code Information Extended - AOS : Diagnostic Trouble Code Number";
BA_ "SignalLongName" SG_ 1830 DTCI_AOS_DTCSource "Diagnostic Trouble Code Information Extended - AOS : Diagnostic Trouble Code Source";
BA_ "SignalType" SG_ 1830 DTCI_AOS_TstNCmpltdOpCyc "ENM";
BA_ "SignalLongName" SG_ 1830 DTCI_AOS_TstNCmpltdOpCyc "Diagnostic Trouble Code Information Extended - AOS : Test Not Completed This Operation Cycle";
BA_ "SignalType" SG_ 1830 DTCI_AOS_TstNCmpltdLstClr "ENM";
BA_ "SignalLongName" SG_ 1830 DTCI_AOS_TstNCmpltdLstClr "Diagnostic Trouble Code Information Extended - AOS : Test Not Completed Since Last Clear";
BA_ "SignalType" SG_ 1830 DTCI_AOS_TstFldOpCyc "ENM";
BA_ "SignalLongName" SG_ 1830 DTCI_AOS_TstFldOpCyc "Diagnostic Trouble Code Information Extended - AOS : Test Failed This Operation Cycle";
BA_ "SignalType" SG_ 1830 DTCI_AOS_TstFldLstClr "ENM";
BA_ "SignalLongName" SG_ 1830 DTCI_AOS_TstFldLstClr "Diagnostic Trouble Code Information Extended - AOS : Test Failed Since Last Clear";
BA_ "SignalType" SG_ 1830 DTCI_AOS_TstFld "ENM";
BA_ "SignalLongName" SG_ 1830 DTCI_AOS_TstFld "Diagnostic Trouble Code Information Extended - AOS : Test Failed";
BA_ "SignalType" SG_ 1830 DTCI_AOS_PndngDTC "ENM";
BA_ "SignalLongName" SG_ 1830 DTCI_AOS_PndngDTC "Diagnostic Trouble Code Information Extended - AOS : Pending DTC";
BA_ "SignalType" SG_ 1830 DTCI_AOS_DTCTriggered "ENM";
BA_ "SignalLongName" SG_ 1830 DTCI_AOS_DTCTriggered "Diagnostic Trouble Code Information Extended - AOS : Diagnostic Trouble Code Triggered";
BA_ "SignalType" SG_ 1830 DTCI_AOS_WrnIndTrggrd "ENM";
BA_ "SignalLongName" SG_ 1830 DTCI_AOS_WrnIndTrggrd "Diagnostic Trouble Code Information Extended - AOS : Warning Indicator Triggered";
BA_ "SignalType" SG_ 1830 DTCI_AOS_WrnIndRqd "ENM";
BA_ "SignalLongName" SG_ 1830 DTCI_AOS_WrnIndRqd "Diagnostic Trouble Code Information Extended - AOS : Warning Indicator Requested";
BA_ "SignalLongName" SG_ 1235 DTCI_APA_DTCFailType "Diagnostic Trouble Code Information Extended - APA : Diagnostic Trouble Code Failure Type";
BA_ "SignalType" SG_ 1235 DTCI_APA_CnfrmdDTC "ENM";
BA_ "SignalLongName" SG_ 1235 DTCI_APA_CnfrmdDTC "Diagnostic Trouble Code Information Extended - APA : Confirmed DTC";
BA_ "SignalType" SG_ 1235 DTCI_APA_DTCFaultType "ENM";
BA_ "SignalLongName" SG_ 1235 DTCI_APA_DTCFaultType "Diagnostic Trouble Code Information Extended - APA : Diagnostic Trouble Code Fault Type";
BA_ "SignalLongName" SG_ 1235 DTCI_APA_DTCNumber "Diagnostic Trouble Code Information Extended - APA : Diagnostic Trouble Code Number";
BA_ "SignalLongName" SG_ 1235 DTCI_APA_DTCSource "Diagnostic Trouble Code Information Extended - APA : Diagnostic Trouble Code Source";
BA_ "SignalType" SG_ 1235 DTCI_APA_TstNCmpltdOpCyc "ENM";
BA_ "SignalLongName" SG_ 1235 DTCI_APA_TstNCmpltdOpCyc "Diagnostic Trouble Code Information Extended - APA : Test Not Completed This Operation Cycle";
BA_ "SignalType" SG_ 1235 DTCI_APA_TstNCmpltdLstClr "ENM";
BA_ "SignalLongName" SG_ 1235 DTCI_APA_TstNCmpltdLstClr "Diagnostic Trouble Code Information Extended - APA : Test Not Completed Since Last Clear";
BA_ "SignalType" SG_ 1235 DTCI_APA_TstFldOpCyc "ENM";
BA_ "SignalLongName" SG_ 1235 DTCI_APA_TstFldOpCyc "Diagnostic Trouble Code Information Extended - APA : Test Failed This Operation Cycle";
BA_ "SignalType" SG_ 1235 DTCI_APA_TstFldLstClr "ENM";
BA_ "SignalLongName" SG_ 1235 DTCI_APA_TstFldLstClr "Diagnostic Trouble Code Information Extended - APA : Test Failed Since Last Clear";
BA_ "SignalType" SG_ 1235 DTCI_APA_TstFld "ENM";
BA_ "SignalLongName" SG_ 1235 DTCI_APA_TstFld "Diagnostic Trouble Code Information Extended - APA : Test Failed";
BA_ "SignalType" SG_ 1235 DTCI_APA_PndngDTC "ENM";
BA_ "SignalLongName" SG_ 1235 DTCI_APA_PndngDTC "Diagnostic Trouble Code Information Extended - APA : Pending DTC";
BA_ "SignalType" SG_ 1235 DTCI_APA_DTCTriggered "ENM";
BA_ "SignalLongName" SG_ 1235 DTCI_APA_DTCTriggered "Diagnostic Trouble Code Information Extended - APA : Diagnostic Trouble Code Triggered";
BA_ "SignalType" SG_ 1235 DTCI_APA_WrnIndTrggrd "ENM";
BA_ "SignalLongName" SG_ 1235 DTCI_APA_WrnIndTrggrd "Diagnostic Trouble Code Information Extended - APA : Warning Indicator Triggered";
BA_ "SignalType" SG_ 1235 DTCI_APA_WrnIndRqd "ENM";
BA_ "SignalLongName" SG_ 1235 DTCI_APA_WrnIndRqd "Diagnostic Trouble Code Information Extended - APA : Warning Indicator Requested";
BA_ "SignalLongName" SG_ 1831 DTCI_ARB_DTCFailType "Diagnostic Trouble Code Information Extended - ARB : Diagnostic Trouble Code Failure Type";
BA_ "SignalType" SG_ 1831 DTCI_ARB_CnfrmdDTC "ENM";
BA_ "SignalLongName" SG_ 1831 DTCI_ARB_CnfrmdDTC "Diagnostic Trouble Code Information Extended - ARB : Confirmed DTC";
BA_ "SignalType" SG_ 1831 DTCI_ARB_DTCFaultType "ENM";
BA_ "SignalLongName" SG_ 1831 DTCI_ARB_DTCFaultType "Diagnostic Trouble Code Information Extended - ARB : Diagnostic Trouble Code Fault Type";
BA_ "SignalLongName" SG_ 1831 DTCI_ARB_DTCNumber "Diagnostic Trouble Code Information Extended - ARB : Diagnostic Trouble Code Number";
BA_ "SignalLongName" SG_ 1831 DTCI_ARB_DTCSource "Diagnostic Trouble Code Information Extended - ARB : Diagnostic Trouble Code Source";
BA_ "SignalType" SG_ 1831 DTCI_ARB_TstNCmpltdOpCyc "ENM";
BA_ "SignalLongName" SG_ 1831 DTCI_ARB_TstNCmpltdOpCyc "Diagnostic Trouble Code Information Extended - ARB : Test Not Completed This Operation Cycle";
BA_ "SignalType" SG_ 1831 DTCI_ARB_TstNCmpltdLstClr "ENM";
BA_ "SignalLongName" SG_ 1831 DTCI_ARB_TstNCmpltdLstClr "Diagnostic Trouble Code Information Extended - ARB : Test Not Completed Since Last Clear";
BA_ "SignalType" SG_ 1831 DTCI_ARB_TstFldOpCyc "ENM";
BA_ "SignalLongName" SG_ 1831 DTCI_ARB_TstFldOpCyc "Diagnostic Trouble Code Information Extended - ARB : Test Failed This Operation Cycle";
BA_ "SignalType" SG_ 1831 DTCI_ARB_TstFldLstClr "ENM";
BA_ "SignalLongName" SG_ 1831 DTCI_ARB_TstFldLstClr "Diagnostic Trouble Code Information Extended - ARB : Test Failed Since Last Clear";
BA_ "SignalType" SG_ 1831 DTCI_ARB_TstFld "ENM";
BA_ "SignalLongName" SG_ 1831 DTCI_ARB_TstFld "Diagnostic Trouble Code Information Extended - ARB : Test Failed";
BA_ "SignalType" SG_ 1831 DTCI_ARB_PndngDTC "ENM";
BA_ "SignalLongName" SG_ 1831 DTCI_ARB_PndngDTC "Diagnostic Trouble Code Information Extended - ARB : Pending DTC";
BA_ "SignalType" SG_ 1831 DTCI_ARB_DTCTriggered "ENM";
BA_ "SignalLongName" SG_ 1831 DTCI_ARB_DTCTriggered "Diagnostic Trouble Code Information Extended - ARB : Diagnostic Trouble Code Triggered";
BA_ "SignalType" SG_ 1831 DTCI_ARB_WrnIndTrggrd "ENM";
BA_ "SignalLongName" SG_ 1831 DTCI_ARB_WrnIndTrggrd "Diagnostic Trouble Code Information Extended - ARB : Warning Indicator Triggered";
BA_ "SignalType" SG_ 1831 DTCI_ARB_WrnIndRqd "ENM";
BA_ "SignalLongName" SG_ 1831 DTCI_ARB_WrnIndRqd "Diagnostic Trouble Code Information Extended - ARB : Warning Indicator Requested";
BA_ "SignalLongName" SG_ 1234 DTCI_ARS_DTCFailType "Diagnostic Trouble Code Information Extended - ARS : Diagnostic Trouble Code Failure Type";
BA_ "SignalType" SG_ 1234 DTCI_ARS_CnfrmdDTC "ENM";
BA_ "SignalLongName" SG_ 1234 DTCI_ARS_CnfrmdDTC "Diagnostic Trouble Code Information Extended - ARS : Confirmed DTC";
BA_ "SignalType" SG_ 1234 DTCI_ARS_DTCFaultType "ENM";
BA_ "SignalLongName" SG_ 1234 DTCI_ARS_DTCFaultType "Diagnostic Trouble Code Information Extended - ARS : Diagnostic Trouble Code Fault Type";
BA_ "SignalLongName" SG_ 1234 DTCI_ARS_DTCNumber "Diagnostic Trouble Code Information Extended - ARS : Diagnostic Trouble Code Number";
BA_ "SignalLongName" SG_ 1234 DTCI_ARS_DTCSource "Diagnostic Trouble Code Information Extended - ARS : Diagnostic Trouble Code Source";
BA_ "SignalType" SG_ 1234 DTCI_ARS_TstNCmpltdOpCyc "ENM";
BA_ "SignalLongName" SG_ 1234 DTCI_ARS_TstNCmpltdOpCyc "Diagnostic Trouble Code Information Extended - ARS : Test Not Completed This Operation Cycle";
BA_ "SignalType" SG_ 1234 DTCI_ARS_TstNCmpltdLstClr "ENM";
BA_ "SignalLongName" SG_ 1234 DTCI_ARS_TstNCmpltdLstClr "Diagnostic Trouble Code Information Extended - ARS : Test Not Completed Since Last Clear";
BA_ "SignalType" SG_ 1234 DTCI_ARS_TstFldOpCyc "ENM";
BA_ "SignalLongName" SG_ 1234 DTCI_ARS_TstFldOpCyc "Diagnostic Trouble Code Information Extended - ARS : Test Failed This Operation Cycle";
BA_ "SignalType" SG_ 1234 DTCI_ARS_TstFldLstClr "ENM";
BA_ "SignalLongName" SG_ 1234 DTCI_ARS_TstFldLstClr "Diagnostic Trouble Code Information Extended - ARS : Test Failed Since Last Clear";
BA_ "SignalType" SG_ 1234 DTCI_ARS_TstFld "ENM";
BA_ "SignalLongName" SG_ 1234 DTCI_ARS_TstFld "Diagnostic Trouble Code Information Extended - ARS : Test Failed";
BA_ "SignalType" SG_ 1234 DTCI_ARS_PndngDTC "ENM";
BA_ "SignalLongName" SG_ 1234 DTCI_ARS_PndngDTC "Diagnostic Trouble Code Information Extended - ARS : Pending DTC";
BA_ "SignalType" SG_ 1234 DTCI_ARS_DTCTriggered "ENM";
BA_ "SignalLongName" SG_ 1234 DTCI_ARS_DTCTriggered "Diagnostic Trouble Code Information Extended - ARS : Diagnostic Trouble Code Triggered";
BA_ "SignalType" SG_ 1234 DTCI_ARS_WrnIndTrggrd "ENM";
BA_ "SignalLongName" SG_ 1234 DTCI_ARS_WrnIndTrggrd "Diagnostic Trouble Code Information Extended - ARS : Warning Indicator Triggered";
BA_ "SignalType" SG_ 1234 DTCI_ARS_WrnIndRqd "ENM";
BA_ "SignalLongName" SG_ 1234 DTCI_ARS_WrnIndRqd "Diagnostic Trouble Code Information Extended - ARS : Warning Indicator Requested";
BA_ "SignalLongName" SG_ 1832 DTCI_BCM_DTCFailType "Diagnostic Trouble Code Information Extended - BCM : Diagnostic Trouble Code Failure Type";
BA_ "SignalType" SG_ 1832 DTCI_BCM_CnfrmdDTC "ENM";
BA_ "SignalLongName" SG_ 1832 DTCI_BCM_CnfrmdDTC "Diagnostic Trouble Code Information Extended - BCM : Confirmed DTC";
BA_ "SignalType" SG_ 1832 DTCI_BCM_DTCFaultType "ENM";
BA_ "SignalLongName" SG_ 1832 DTCI_BCM_DTCFaultType "Diagnostic Trouble Code Information Extended - BCM : Diagnostic Trouble Code Fault Type";
BA_ "SignalLongName" SG_ 1832 DTCI_BCM_DTCNumber "Diagnostic Trouble Code Information Extended - BCM : Diagnostic Trouble Code Number";
BA_ "SignalLongName" SG_ 1832 DTCI_BCM_DTCSource "Diagnostic Trouble Code Information Extended - BCM : Diagnostic Trouble Code Source";
BA_ "SignalType" SG_ 1832 DTCI_BCM_TstNCmpltdOpCyc "ENM";
BA_ "SignalLongName" SG_ 1832 DTCI_BCM_TstNCmpltdOpCyc "Diagnostic Trouble Code Information Extended - BCM : Test Not Completed This Operation Cycle";
BA_ "SignalType" SG_ 1832 DTCI_BCM_TstNCmpltdLstClr "ENM";
BA_ "SignalLongName" SG_ 1832 DTCI_BCM_TstNCmpltdLstClr "Diagnostic Trouble Code Information Extended - BCM : Test Not Completed Since Last Clear";
BA_ "SignalType" SG_ 1832 DTCI_BCM_TstFldOpCyc "ENM";
BA_ "SignalLongName" SG_ 1832 DTCI_BCM_TstFldOpCyc "Diagnostic Trouble Code Information Extended - BCM : Test Failed This Operation Cycle";
BA_ "SignalType" SG_ 1832 DTCI_BCM_TstFldLstClr "ENM";
BA_ "SignalLongName" SG_ 1832 DTCI_BCM_TstFldLstClr "Diagnostic Trouble Code Information Extended - BCM : Test Failed Since Last Clear";
BA_ "SignalType" SG_ 1832 DTCI_BCM_TstFld "ENM";
BA_ "SignalLongName" SG_ 1832 DTCI_BCM_TstFld "Diagnostic Trouble Code Information Extended - BCM : Test Failed";
BA_ "SignalType" SG_ 1832 DTCI_BCM_PndngDTC "ENM";
BA_ "SignalLongName" SG_ 1832 DTCI_BCM_PndngDTC "Diagnostic Trouble Code Information Extended - BCM : Pending DTC";
BA_ "SignalType" SG_ 1832 DTCI_BCM_DTCTriggered "ENM";
BA_ "SignalLongName" SG_ 1832 DTCI_BCM_DTCTriggered "Diagnostic Trouble Code Information Extended - BCM : Diagnostic Trouble Code Triggered";
BA_ "SignalType" SG_ 1832 DTCI_BCM_WrnIndTrggrd "ENM";
BA_ "SignalLongName" SG_ 1832 DTCI_BCM_WrnIndTrggrd "Diagnostic Trouble Code Information Extended - BCM : Warning Indicator Triggered";
BA_ "SignalType" SG_ 1832 DTCI_BCM_WrnIndRqd "ENM";
BA_ "SignalLongName" SG_ 1832 DTCI_BCM_WrnIndRqd "Diagnostic Trouble Code Information Extended - BCM : Warning Indicator Requested";
BA_ "SignalLongName" SG_ 1950 DTCI_BSM_HEV_DTCFailType "Diagnostic Trouble Code Information Extended - BSM_HEV : Diagnostic Trouble Code Failure Type";
BA_ "SignalType" SG_ 1950 DTCI_BSM_HEV_CnfrmdDTC "ENM";
BA_ "SignalLongName" SG_ 1950 DTCI_BSM_HEV_CnfrmdDTC "Diagnostic Trouble Code Information Extended - BSM_HEV : Confirmed DTC";
BA_ "SignalType" SG_ 1950 DTCI_BSM_HEV_DTCFaultType "ENM";
BA_ "SignalLongName" SG_ 1950 DTCI_BSM_HEV_DTCFaultType "Diagnostic Trouble Code Information Extended - BSM_HEV : Diagnostic Trouble Code Fault Type";
BA_ "SignalLongName" SG_ 1950 DTCI_BSM_HEV_DTCNumber "Diagnostic Trouble Code Information Extended - BSM_HEV : Diagnostic Trouble Code Number";
BA_ "SignalLongName" SG_ 1950 DTCI_BSM_HEV_DTCSource "Diagnostic Trouble Code Information Extended - BSM_HEV : Diagnostic Trouble Code Source";
BA_ "SignalType" SG_ 1950 DTCI_BSM_HEV_TstNCmpltdOpCyc "ENM";
BA_ "SignalLongName" SG_ 1950 DTCI_BSM_HEV_TstNCmpltdOpCyc "Diagnostic Trouble Code Information Extended - BSM_HEV : Test Not Completed This Operation Cycle";
BA_ "SignalType" SG_ 1950 DTCI_BSM_HEV_TstNCmpltdLstClr "ENM";
BA_ "SignalLongName" SG_ 1950 DTCI_BSM_HEV_TstNCmpltdLstClr "Diagnostic Trouble Code Information Extended - BSM_HEV : Test Not Completed Since Last Clear";
BA_ "SignalType" SG_ 1950 DTCI_BSM_HEV_TstFldOpCyc "ENM";
BA_ "SignalLongName" SG_ 1950 DTCI_BSM_HEV_TstFldOpCyc "Diagnostic Trouble Code Information Extended - BSM_HEV : Test Failed This Operation Cycle";
BA_ "SignalType" SG_ 1950 DTCI_BSM_HEV_TstFldLstClr "ENM";
BA_ "SignalLongName" SG_ 1950 DTCI_BSM_HEV_TstFldLstClr "Diagnostic Trouble Code Information Extended - BSM_HEV : Test Failed Since Last Clear";
BA_ "SignalType" SG_ 1950 DTCI_BSM_HEV_TstFld "ENM";
BA_ "SignalLongName" SG_ 1950 DTCI_BSM_HEV_TstFld "Diagnostic Trouble Code Information Extended - BSM_HEV : Test Failed";
BA_ "SignalType" SG_ 1950 DTCI_BSM_HEV_PndngDTC "ENM";
BA_ "SignalLongName" SG_ 1950 DTCI_BSM_HEV_PndngDTC "Diagnostic Trouble Code Information Extended - BSM_HEV : Pending DTC";
BA_ "SignalType" SG_ 1950 DTCI_BSM_HEV_DTCTriggered "ENM";
BA_ "SignalLongName" SG_ 1950 DTCI_BSM_HEV_DTCTriggered "Diagnostic Trouble Code Information Extended - BSM_HEV : Diagnostic Trouble Code Triggered";
BA_ "SignalType" SG_ 1950 DTCI_BSM_HEV_WrnIndTrggrd "ENM";
BA_ "SignalLongName" SG_ 1950 DTCI_BSM_HEV_WrnIndTrggrd "Diagnostic Trouble Code Information Extended - BSM_HEV : Warning Indicator Triggered";
BA_ "SignalType" SG_ 1950 DTCI_BSM_HEV_WrnIndRqd "ENM";
BA_ "SignalLongName" SG_ 1950 DTCI_BSM_HEV_WrnIndRqd "Diagnostic Trouble Code Information Extended - BSM_HEV : Warning Indicator Requested";
BA_ "SignalLongName" SG_ 1233 DTCI_BSM_MH_DTCFailType "Diagnostic Trouble Code Information Extended - BSM_MH : Diagnostic Trouble Code Failure Type";
BA_ "SignalType" SG_ 1233 DTCI_BSM_MH_CnfrmdDTC "ENM";
BA_ "SignalLongName" SG_ 1233 DTCI_BSM_MH_CnfrmdDTC "Diagnostic Trouble Code Information Extended - BSM_MH : Confirmed DTC";
BA_ "SignalType" SG_ 1233 DTCI_BSM_MH_DTCFaultType "ENM";
BA_ "SignalLongName" SG_ 1233 DTCI_BSM_MH_DTCFaultType "Diagnostic Trouble Code Information Extended - BSM_MH : Diagnostic Trouble Code Fault Type";
BA_ "SignalLongName" SG_ 1233 DTCI_BSM_MH_DTCNumber "Diagnostic Trouble Code Information Extended - BSM_MH : Diagnostic Trouble Code Number";
BA_ "SignalLongName" SG_ 1233 DTCI_BSM_MH_DTCSource "Diagnostic Trouble Code Information Extended - BSM_MH : Diagnostic Trouble Code Source";
BA_ "SignalType" SG_ 1233 DTCI_BSM_MH_TstNCmpltdOpCyc "ENM";
BA_ "SignalLongName" SG_ 1233 DTCI_BSM_MH_TstNCmpltdOpCyc "Diagnostic Trouble Code Information Extended - BSM_MH : Test Not Completed This Operation Cycle";
BA_ "SignalType" SG_ 1233 DTCI_BSM_MH_TstNCmpltdLstClr "ENM";
BA_ "SignalLongName" SG_ 1233 DTCI_BSM_MH_TstNCmpltdLstClr "Diagnostic Trouble Code Information Extended - BSM_MH : Test Not Completed Since Last Clear";
BA_ "SignalType" SG_ 1233 DTCI_BSM_MH_TstFldOpCyc "ENM";
BA_ "SignalLongName" SG_ 1233 DTCI_BSM_MH_TstFldOpCyc "Diagnostic Trouble Code Information Extended - BSM_MH : Test Failed This Operation Cycle";
BA_ "SignalType" SG_ 1233 DTCI_BSM_MH_TstFldLstClr "ENM";
BA_ "SignalLongName" SG_ 1233 DTCI_BSM_MH_TstFldLstClr "Diagnostic Trouble Code Information Extended - BSM_MH : Test Failed Since Last Clear";
BA_ "SignalType" SG_ 1233 DTCI_BSM_MH_TstFld "ENM";
BA_ "SignalLongName" SG_ 1233 DTCI_BSM_MH_TstFld "Diagnostic Trouble Code Information Extended - BSM_MH : Test Failed";
BA_ "SignalType" SG_ 1233 DTCI_BSM_MH_PndngDTC "ENM";
BA_ "SignalLongName" SG_ 1233 DTCI_BSM_MH_PndngDTC "Diagnostic Trouble Code Information Extended - BSM_MH : Pending DTC";
BA_ "SignalType" SG_ 1233 DTCI_BSM_MH_DTCTriggered "ENM";
BA_ "SignalLongName" SG_ 1233 DTCI_BSM_MH_DTCTriggered "Diagnostic Trouble Code Information Extended - BSM_MH : Diagnostic Trouble Code Triggered";
BA_ "SignalType" SG_ 1233 DTCI_BSM_MH_WrnIndTrggrd "ENM";
BA_ "SignalLongName" SG_ 1233 DTCI_BSM_MH_WrnIndTrggrd "Diagnostic Trouble Code Information Extended - BSM_MH : Warning Indicator Triggered";
BA_ "SignalType" SG_ 1233 DTCI_BSM_MH_WrnIndRqd "ENM";
BA_ "SignalLongName" SG_ 1233 DTCI_BSM_MH_WrnIndRqd "Diagnostic Trouble Code Information Extended - BSM_MH : Warning Indicator Requested";
BA_ "SignalLongName" SG_ 1833 DTCI_BSM_DTCFailType "Diagnostic Trouble Code Information Extended - BSM : Diagnostic Trouble Code Failure Type";
BA_ "SignalType" SG_ 1833 DTCI_BSM_CnfrmdDTC "ENM";
BA_ "SignalLongName" SG_ 1833 DTCI_BSM_CnfrmdDTC "Diagnostic Trouble Code Information Extended - BSM : Confirmed DTC";
BA_ "SignalType" SG_ 1833 DTCI_BSM_DTCFaultType "ENM";
BA_ "SignalLongName" SG_ 1833 DTCI_BSM_DTCFaultType "Diagnostic Trouble Code Information Extended - BSM : Diagnostic Trouble Code Fault Type";
BA_ "SignalLongName" SG_ 1833 DTCI_BSM_DTCNumber "Diagnostic Trouble Code Information Extended - BSM : Diagnostic Trouble Code Number";
BA_ "SignalLongName" SG_ 1833 DTCI_BSM_DTCSource "Diagnostic Trouble Code Information Extended - BSM : Diagnostic Trouble Code Source";
BA_ "SignalType" SG_ 1833 DTCI_BSM_TstNCmpltdOpCyc "ENM";
BA_ "SignalLongName" SG_ 1833 DTCI_BSM_TstNCmpltdOpCyc "Diagnostic Trouble Code Information Extended - BSM : Test Not Completed This Operation Cycle";
BA_ "SignalType" SG_ 1833 DTCI_BSM_TstNCmpltdLstClr "ENM";
BA_ "SignalLongName" SG_ 1833 DTCI_BSM_TstNCmpltdLstClr "Diagnostic Trouble Code Information Extended - BSM : Test Not Completed Since Last Clear";
BA_ "SignalType" SG_ 1833 DTCI_BSM_TstFldOpCyc "ENM";
BA_ "SignalLongName" SG_ 1833 DTCI_BSM_TstFldOpCyc "Diagnostic Trouble Code Information Extended - BSM : Test Failed This Operation Cycle";
BA_ "SignalType" SG_ 1833 DTCI_BSM_TstFldLstClr "ENM";
BA_ "SignalLongName" SG_ 1833 DTCI_BSM_TstFldLstClr "Diagnostic Trouble Code Information Extended - BSM : Test Failed Since Last Clear";
BA_ "SignalType" SG_ 1833 DTCI_BSM_TstFld "ENM";
BA_ "SignalLongName" SG_ 1833 DTCI_BSM_TstFld "Diagnostic Trouble Code Information Extended - BSM : Test Failed";
BA_ "SignalType" SG_ 1833 DTCI_BSM_PndngDTC "ENM";
BA_ "SignalLongName" SG_ 1833 DTCI_BSM_PndngDTC "Diagnostic Trouble Code Information Extended - BSM : Pending DTC";
BA_ "SignalType" SG_ 1833 DTCI_BSM_DTCTriggered "ENM";
BA_ "SignalLongName" SG_ 1833 DTCI_BSM_DTCTriggered "Diagnostic Trouble Code Information Extended - BSM : Diagnostic Trouble Code Triggered";
BA_ "SignalType" SG_ 1833 DTCI_BSM_WrnIndTrggrd "ENM";
BA_ "SignalLongName" SG_ 1833 DTCI_BSM_WrnIndTrggrd "Diagnostic Trouble Code Information Extended - BSM : Warning Indicator Triggered";
BA_ "SignalType" SG_ 1833 DTCI_BSM_WrnIndRqd "ENM";
BA_ "SignalLongName" SG_ 1833 DTCI_BSM_WrnIndRqd "Diagnostic Trouble Code Information Extended - BSM : Warning Indicator Requested";
BA_ "SignalLongName" SG_ 1232 DTCI_CGM_DTCFailType "Diagnostic Trouble Code Information Extended - CGM : Diagnostic Trouble Code Failure Type";
BA_ "SignalType" SG_ 1232 DTCI_CGM_CnfrmdDTC "ENM";
BA_ "SignalLongName" SG_ 1232 DTCI_CGM_CnfrmdDTC "Diagnostic Trouble Code Information Extended - CGM : Confirmed DTC";
BA_ "SignalType" SG_ 1232 DTCI_CGM_DTCFaultType "ENM";
BA_ "SignalLongName" SG_ 1232 DTCI_CGM_DTCFaultType "Diagnostic Trouble Code Information Extended - CGM : Diagnostic Trouble Code Fault Type";
BA_ "SignalLongName" SG_ 1232 DTCI_CGM_DTCNumber "Diagnostic Trouble Code Information Extended - CGM : Diagnostic Trouble Code Number";
BA_ "SignalLongName" SG_ 1232 DTCI_CGM_DTCSource "Diagnostic Trouble Code Information Extended - CGM : Diagnostic Trouble Code Source";
BA_ "SignalType" SG_ 1232 DTCI_CGM_TstNCmpltdOpCyc "ENM";
BA_ "SignalLongName" SG_ 1232 DTCI_CGM_TstNCmpltdOpCyc "Diagnostic Trouble Code Information Extended - CGM : Test Not Completed This Operation Cycle";
BA_ "SignalType" SG_ 1232 DTCI_CGM_TstNCmpltdLstClr "ENM";
BA_ "SignalLongName" SG_ 1232 DTCI_CGM_TstNCmpltdLstClr "Diagnostic Trouble Code Information Extended - CGM : Test Not Completed Since Last Clear";
BA_ "SignalType" SG_ 1232 DTCI_CGM_TstFldOpCyc "ENM";
BA_ "SignalLongName" SG_ 1232 DTCI_CGM_TstFldOpCyc "Diagnostic Trouble Code Information Extended - CGM : Test Failed This Operation Cycle";
BA_ "SignalType" SG_ 1232 DTCI_CGM_TstFldLstClr "ENM";
BA_ "SignalLongName" SG_ 1232 DTCI_CGM_TstFldLstClr "Diagnostic Trouble Code Information Extended - CGM : Test Failed Since Last Clear";
BA_ "SignalType" SG_ 1232 DTCI_CGM_TstFld "ENM";
BA_ "SignalLongName" SG_ 1232 DTCI_CGM_TstFld "Diagnostic Trouble Code Information Extended - CGM : Test Failed";
BA_ "SignalType" SG_ 1232 DTCI_CGM_PndngDTC "ENM";
BA_ "SignalLongName" SG_ 1232 DTCI_CGM_PndngDTC "Diagnostic Trouble Code Information Extended - CGM : Pending DTC";
BA_ "SignalType" SG_ 1232 DTCI_CGM_DTCTriggered "ENM";
BA_ "SignalLongName" SG_ 1232 DTCI_CGM_DTCTriggered "Diagnostic Trouble Code Information Extended - CGM : Diagnostic Trouble Code Triggered";
BA_ "SignalType" SG_ 1232 DTCI_CGM_WrnIndTrggrd "ENM";
BA_ "SignalLongName" SG_ 1232 DTCI_CGM_WrnIndTrggrd "Diagnostic Trouble Code Information Extended - CGM : Warning Indicator Triggered";
BA_ "SignalType" SG_ 1232 DTCI_CGM_WrnIndRqd "ENM";
BA_ "SignalLongName" SG_ 1232 DTCI_CGM_WrnIndRqd "Diagnostic Trouble Code Information Extended - CGM : Warning Indicator Requested";
BA_ "SignalLongName" SG_ 1914 DTCI_CSM_AV_DTCFailType "Diagnostic Trouble Code Information Extended - CSM_AV : Diagnostic Trouble Code Failure Type";
BA_ "SignalType" SG_ 1914 DTCI_CSM_AV_CnfrmdDTC "ENM";
BA_ "SignalLongName" SG_ 1914 DTCI_CSM_AV_CnfrmdDTC "Diagnostic Trouble Code Information Extended - CSM_AV : Confirmed DTC";
BA_ "SignalType" SG_ 1914 DTCI_CSM_AV_DTCFaultType "ENM";
BA_ "SignalLongName" SG_ 1914 DTCI_CSM_AV_DTCFaultType "Diagnostic Trouble Code Information Extended - CSM_AV : Diagnostic Trouble Code Fault Type";
BA_ "SignalLongName" SG_ 1914 DTCI_CSM_AV_DTCNumber "Diagnostic Trouble Code Information Extended - CSM_AV : Diagnostic Trouble Code Number";
BA_ "SignalLongName" SG_ 1914 DTCI_CSM_AV_DTCSource "Diagnostic Trouble Code Information Extended - CSM_AV : Diagnostic Trouble Code Source";
BA_ "SignalType" SG_ 1914 DTCI_CSM_AV_TstNCmpltdOpCyc "ENM";
BA_ "SignalLongName" SG_ 1914 DTCI_CSM_AV_TstNCmpltdOpCyc "Diagnostic Trouble Code Information Extended - CSM_AV : Test Not Completed This Operation Cycle";
BA_ "SignalType" SG_ 1914 DTCI_CSM_AV_TstNCmpltdLstClr "ENM";
BA_ "SignalLongName" SG_ 1914 DTCI_CSM_AV_TstNCmpltdLstClr "Diagnostic Trouble Code Information Extended - CSM_AV : Test Not Completed Since Last Clear";
BA_ "SignalType" SG_ 1914 DTCI_CSM_AV_TstFldOpCyc "ENM";
BA_ "SignalLongName" SG_ 1914 DTCI_CSM_AV_TstFldOpCyc "Diagnostic Trouble Code Information Extended - CSM_AV : Test Failed This Operation Cycle";
BA_ "SignalType" SG_ 1914 DTCI_CSM_AV_TstFldLstClr "ENM";
BA_ "SignalLongName" SG_ 1914 DTCI_CSM_AV_TstFldLstClr "Diagnostic Trouble Code Information Extended - CSM_AV : Test Failed Since Last Clear";
BA_ "SignalType" SG_ 1914 DTCI_CSM_AV_TstFld "ENM";
BA_ "SignalLongName" SG_ 1914 DTCI_CSM_AV_TstFld "Diagnostic Trouble Code Information Extended - CSM_AV : Test Failed";
BA_ "SignalType" SG_ 1914 DTCI_CSM_AV_PndngDTC "ENM";
BA_ "SignalLongName" SG_ 1914 DTCI_CSM_AV_PndngDTC "Diagnostic Trouble Code Information Extended - CSM_AV : Pending DTC";
BA_ "SignalType" SG_ 1914 DTCI_CSM_AV_DTCTriggered "ENM";
BA_ "SignalLongName" SG_ 1914 DTCI_CSM_AV_DTCTriggered "Diagnostic Trouble Code Information Extended - CSM_AV : Diagnostic Trouble Code Triggered";
BA_ "SignalType" SG_ 1914 DTCI_CSM_AV_WrnIndTrggrd "ENM";
BA_ "SignalLongName" SG_ 1914 DTCI_CSM_AV_WrnIndTrggrd "Diagnostic Trouble Code Information Extended - CSM_AV : Warning Indicator Triggered";
BA_ "SignalType" SG_ 1914 DTCI_CSM_AV_WrnIndRqd "ENM";
BA_ "SignalLongName" SG_ 1914 DTCI_CSM_AV_WrnIndRqd "Diagnostic Trouble Code Information Extended - CSM_AV : Warning Indicator Requested";
BA_ "SignalLongName" SG_ 1835 DTCI_CSM_DTCFailType "Diagnostic Trouble Code Information Extended - CSM : Diagnostic Trouble Code Failure Type";
BA_ "SignalType" SG_ 1835 DTCI_CSM_CnfrmdDTC "ENM";
BA_ "SignalLongName" SG_ 1835 DTCI_CSM_CnfrmdDTC "Diagnostic Trouble Code Information Extended - CSM : Confirmed DTC";
BA_ "SignalType" SG_ 1835 DTCI_CSM_DTCFaultType "ENM";
BA_ "SignalLongName" SG_ 1835 DTCI_CSM_DTCFaultType "Diagnostic Trouble Code Information Extended - CSM : Diagnostic Trouble Code Fault Type";
BA_ "SignalLongName" SG_ 1835 DTCI_CSM_DTCNumber "Diagnostic Trouble Code Information Extended - CSM : Diagnostic Trouble Code Number";
BA_ "SignalLongName" SG_ 1835 DTCI_CSM_DTCSource "Diagnostic Trouble Code Information Extended - CSM : Diagnostic Trouble Code Source";
BA_ "SignalType" SG_ 1835 DTCI_CSM_TstNCmpltdOpCyc "ENM";
BA_ "SignalLongName" SG_ 1835 DTCI_CSM_TstNCmpltdOpCyc "Diagnostic Trouble Code Information Extended - CSM : Test Not Completed This Operation Cycle";
BA_ "SignalType" SG_ 1835 DTCI_CSM_TstNCmpltdLstClr "ENM";
BA_ "SignalLongName" SG_ 1835 DTCI_CSM_TstNCmpltdLstClr "Diagnostic Trouble Code Information Extended - CSM : Test Not Completed Since Last Clear";
BA_ "SignalType" SG_ 1835 DTCI_CSM_TstFldOpCyc "ENM";
BA_ "SignalLongName" SG_ 1835 DTCI_CSM_TstFldOpCyc "Diagnostic Trouble Code Information Extended - CSM : Test Failed This Operation Cycle";
BA_ "SignalType" SG_ 1835 DTCI_CSM_TstFldLstClr "ENM";
BA_ "SignalLongName" SG_ 1835 DTCI_CSM_TstFldLstClr "Diagnostic Trouble Code Information Extended - CSM : Test Failed Since Last Clear";
BA_ "SignalType" SG_ 1835 DTCI_CSM_TstFld "ENM";
BA_ "SignalLongName" SG_ 1835 DTCI_CSM_TstFld "Diagnostic Trouble Code Information Extended - CSM : Test Failed";
BA_ "SignalType" SG_ 1835 DTCI_CSM_PndngDTC "ENM";
BA_ "SignalLongName" SG_ 1835 DTCI_CSM_PndngDTC "Diagnostic Trouble Code Information Extended - CSM : Pending DTC";
BA_ "SignalType" SG_ 1835 DTCI_CSM_DTCTriggered "ENM";
BA_ "SignalLongName" SG_ 1835 DTCI_CSM_DTCTriggered "Diagnostic Trouble Code Information Extended - CSM : Diagnostic Trouble Code Triggered";
BA_ "SignalType" SG_ 1835 DTCI_CSM_WrnIndTrggrd "ENM";
BA_ "SignalLongName" SG_ 1835 DTCI_CSM_WrnIndTrggrd "Diagnostic Trouble Code Information Extended - CSM : Warning Indicator Triggered";
BA_ "SignalType" SG_ 1835 DTCI_CSM_WrnIndRqd "ENM";
BA_ "SignalLongName" SG_ 1835 DTCI_CSM_WrnIndRqd "Diagnostic Trouble Code Information Extended - CSM : Warning Indicator Requested";
BA_ "SignalLongName" SG_ 1230 DTCI_DCM_DTCFailType "Diagnostic Trouble Code Information Extended - DCM : Diagnostic Trouble Code Failure Type";
BA_ "SignalType" SG_ 1230 DTCI_DCM_CnfrmdDTC "ENM";
BA_ "SignalLongName" SG_ 1230 DTCI_DCM_CnfrmdDTC "Diagnostic Trouble Code Information Extended - DCM : Confirmed DTC";
BA_ "SignalType" SG_ 1230 DTCI_DCM_DTCFaultType "ENM";
BA_ "SignalLongName" SG_ 1230 DTCI_DCM_DTCFaultType "Diagnostic Trouble Code Information Extended - DCM : Diagnostic Trouble Code Fault Type";
BA_ "SignalLongName" SG_ 1230 DTCI_DCM_DTCNumber "Diagnostic Trouble Code Information Extended - DCM : Diagnostic Trouble Code Number";
BA_ "SignalLongName" SG_ 1230 DTCI_DCM_DTCSource "Diagnostic Trouble Code Information Extended - DCM : Diagnostic Trouble Code Source";
BA_ "SignalType" SG_ 1230 DTCI_DCM_TstNCmpltdOpCyc "ENM";
BA_ "SignalLongName" SG_ 1230 DTCI_DCM_TstNCmpltdOpCyc "Diagnostic Trouble Code Information Extended - DCM : Test Not Completed This Operation Cycle";
BA_ "SignalType" SG_ 1230 DTCI_DCM_TstNCmpltdLstClr "ENM";
BA_ "SignalLongName" SG_ 1230 DTCI_DCM_TstNCmpltdLstClr "Diagnostic Trouble Code Information Extended - DCM : Test Not Completed Since Last Clear";
BA_ "SignalType" SG_ 1230 DTCI_DCM_TstFldOpCyc "ENM";
BA_ "SignalLongName" SG_ 1230 DTCI_DCM_TstFldOpCyc "Diagnostic Trouble Code Information Extended - DCM : Test Failed This Operation Cycle";
BA_ "SignalType" SG_ 1230 DTCI_DCM_TstFldLstClr "ENM";
BA_ "SignalLongName" SG_ 1230 DTCI_DCM_TstFldLstClr "Diagnostic Trouble Code Information Extended - DCM : Test Failed Since Last Clear";
BA_ "SignalType" SG_ 1230 DTCI_DCM_TstFld "ENM";
BA_ "SignalLongName" SG_ 1230 DTCI_DCM_TstFld "Diagnostic Trouble Code Information Extended - DCM : Test Failed";
BA_ "SignalType" SG_ 1230 DTCI_DCM_PndngDTC "ENM";
BA_ "SignalLongName" SG_ 1230 DTCI_DCM_PndngDTC "Diagnostic Trouble Code Information Extended - DCM : Pending DTC";
BA_ "SignalType" SG_ 1230 DTCI_DCM_DTCTriggered "ENM";
BA_ "SignalLongName" SG_ 1230 DTCI_DCM_DTCTriggered "Diagnostic Trouble Code Information Extended - DCM : Diagnostic Trouble Code Triggered";
BA_ "SignalType" SG_ 1230 DTCI_DCM_WrnIndTrggrd "ENM";
BA_ "SignalLongName" SG_ 1230 DTCI_DCM_WrnIndTrggrd "Diagnostic Trouble Code Information Extended - DCM : Warning Indicator Triggered";
BA_ "SignalType" SG_ 1230 DTCI_DCM_WrnIndRqd "ENM";
BA_ "SignalLongName" SG_ 1230 DTCI_DCM_WrnIndRqd "Diagnostic Trouble Code Information Extended - DCM : Warning Indicator Requested";
BA_ "SignalLongName" SG_ 1836 DTCI_DMS_DTCFailType "Diagnostic Trouble Code Information Extended - DMS : Diagnostic Trouble Code Failure Type";
BA_ "SignalType" SG_ 1836 DTCI_DMS_CnfrmdDTC "ENM";
BA_ "SignalLongName" SG_ 1836 DTCI_DMS_CnfrmdDTC "Diagnostic Trouble Code Information Extended - DMS : Confirmed DTC";
BA_ "SignalType" SG_ 1836 DTCI_DMS_DTCFaultType "ENM";
BA_ "SignalLongName" SG_ 1836 DTCI_DMS_DTCFaultType "Diagnostic Trouble Code Information Extended - DMS : Diagnostic Trouble Code Fault Type";
BA_ "SignalLongName" SG_ 1836 DTCI_DMS_DTCNumber "Diagnostic Trouble Code Information Extended - DMS : Diagnostic Trouble Code Number";
BA_ "SignalLongName" SG_ 1836 DTCI_DMS_DTCSource "Diagnostic Trouble Code Information Extended - DMS : Diagnostic Trouble Code Source";
BA_ "SignalType" SG_ 1836 DTCI_DMS_TstNCmpltdOpCyc "ENM";
BA_ "SignalLongName" SG_ 1836 DTCI_DMS_TstNCmpltdOpCyc "Diagnostic Trouble Code Information Extended - DMS : Test Not Completed This Operation Cycle";
BA_ "SignalType" SG_ 1836 DTCI_DMS_TstNCmpltdLstClr "ENM";
BA_ "SignalLongName" SG_ 1836 DTCI_DMS_TstNCmpltdLstClr "Diagnostic Trouble Code Information Extended - DMS : Test Not Completed Since Last Clear";
BA_ "SignalType" SG_ 1836 DTCI_DMS_TstFldOpCyc "ENM";
BA_ "SignalLongName" SG_ 1836 DTCI_DMS_TstFldOpCyc "Diagnostic Trouble Code Information Extended - DMS : Test Failed This Operation Cycle";
BA_ "SignalType" SG_ 1836 DTCI_DMS_TstFldLstClr "ENM";
BA_ "SignalLongName" SG_ 1836 DTCI_DMS_TstFldLstClr "Diagnostic Trouble Code Information Extended - DMS : Test Failed Since Last Clear";
BA_ "SignalType" SG_ 1836 DTCI_DMS_TstFld "ENM";
BA_ "SignalLongName" SG_ 1836 DTCI_DMS_TstFld "Diagnostic Trouble Code Information Extended - DMS : Test Failed";
BA_ "SignalType" SG_ 1836 DTCI_DMS_PndngDTC "ENM";
BA_ "SignalLongName" SG_ 1836 DTCI_DMS_PndngDTC "Diagnostic Trouble Code Information Extended - DMS : Pending DTC";
BA_ "SignalType" SG_ 1836 DTCI_DMS_DTCTriggered "ENM";
BA_ "SignalLongName" SG_ 1836 DTCI_DMS_DTCTriggered "Diagnostic Trouble Code Information Extended - DMS : Diagnostic Trouble Code Triggered";
BA_ "SignalType" SG_ 1836 DTCI_DMS_WrnIndTrggrd "ENM";
BA_ "SignalLongName" SG_ 1836 DTCI_DMS_WrnIndTrggrd "Diagnostic Trouble Code Information Extended - DMS : Warning Indicator Triggered";
BA_ "SignalType" SG_ 1836 DTCI_DMS_WrnIndRqd "ENM";
BA_ "SignalLongName" SG_ 1836 DTCI_DMS_WrnIndRqd "Diagnostic Trouble Code Information Extended - DMS : Warning Indicator Requested";
BA_ "SignalLongName" SG_ 1228 DTCI_EBCM_DTCFailType "Diagnostic Trouble Code Information Extended - EBCM : Diagnostic Trouble Code Failure Type";
BA_ "SignalType" SG_ 1228 DTCI_EBCM_CnfrmdDTC "ENM";
BA_ "SignalLongName" SG_ 1228 DTCI_EBCM_CnfrmdDTC "Diagnostic Trouble Code Information Extended - EBCM : Confirmed DTC";
BA_ "SignalType" SG_ 1228 DTCI_EBCM_DTCFaultType "ENM";
BA_ "SignalLongName" SG_ 1228 DTCI_EBCM_DTCFaultType "Diagnostic Trouble Code Information Extended - EBCM : Diagnostic Trouble Code Fault Type";
BA_ "SignalLongName" SG_ 1228 DTCI_EBCM_DTCNumber "Diagnostic Trouble Code Information Extended - EBCM : Diagnostic Trouble Code Number";
BA_ "SignalLongName" SG_ 1228 DTCI_EBCM_DTCSource "Diagnostic Trouble Code Information Extended - EBCM : Diagnostic Trouble Code Source";
BA_ "SignalType" SG_ 1228 DTCI_EBCM_TstNCmpltdOpCyc "ENM";
BA_ "SignalLongName" SG_ 1228 DTCI_EBCM_TstNCmpltdOpCyc "Diagnostic Trouble Code Information Extended - EBCM : Test Not Completed This Operation Cycle";
BA_ "SignalType" SG_ 1228 DTCI_EBCM_TstNCmpltdLstClr "ENM";
BA_ "SignalLongName" SG_ 1228 DTCI_EBCM_TstNCmpltdLstClr "Diagnostic Trouble Code Information Extended - EBCM : Test Not Completed Since Last Clear";
BA_ "SignalType" SG_ 1228 DTCI_EBCM_TstFldOpCyc "ENM";
BA_ "SignalLongName" SG_ 1228 DTCI_EBCM_TstFldOpCyc "Diagnostic Trouble Code Information Extended - EBCM : Test Failed This Operation Cycle";
BA_ "SignalType" SG_ 1228 DTCI_EBCM_TstFldLstClr "ENM";
BA_ "SignalLongName" SG_ 1228 DTCI_EBCM_TstFldLstClr "Diagnostic Trouble Code Information Extended - EBCM : Test Failed Since Last Clear";
BA_ "SignalType" SG_ 1228 DTCI_EBCM_TstFld "ENM";
BA_ "SignalLongName" SG_ 1228 DTCI_EBCM_TstFld "Diagnostic Trouble Code Information Extended - EBCM : Test Failed";
BA_ "SignalType" SG_ 1228 DTCI_EBCM_PndngDTC "ENM";
BA_ "SignalLongName" SG_ 1228 DTCI_EBCM_PndngDTC "Diagnostic Trouble Code Information Extended - EBCM : Pending DTC";
BA_ "SignalType" SG_ 1228 DTCI_EBCM_DTCTriggered "ENM";
BA_ "SignalLongName" SG_ 1228 DTCI_EBCM_DTCTriggered "Diagnostic Trouble Code Information Extended - EBCM : Diagnostic Trouble Code Triggered";
BA_ "SignalType" SG_ 1228 DTCI_EBCM_WrnIndTrggrd "ENM";
BA_ "SignalLongName" SG_ 1228 DTCI_EBCM_WrnIndTrggrd "Diagnostic Trouble Code Information Extended - EBCM : Warning Indicator Triggered";
BA_ "SignalType" SG_ 1228 DTCI_EBCM_WrnIndRqd "ENM";
BA_ "SignalLongName" SG_ 1228 DTCI_EBCM_WrnIndRqd "Diagnostic Trouble Code Information Extended - EBCM : Warning Indicator Requested";
BA_ "SignalLongName" SG_ 1838 DTCI_ECM_DTCFailType "Diagnostic Trouble Code Information Extended - ECM : Diagnostic Trouble Code Failure Type";
BA_ "SignalType" SG_ 1838 DTCI_ECM_CnfrmdDTC "ENM";
BA_ "SignalLongName" SG_ 1838 DTCI_ECM_CnfrmdDTC "Diagnostic Trouble Code Information Extended - ECM : Confirmed DTC";
BA_ "SignalType" SG_ 1838 DTCI_ECM_DTCFaultType "ENM";
BA_ "SignalLongName" SG_ 1838 DTCI_ECM_DTCFaultType "Diagnostic Trouble Code Information Extended - ECM : Diagnostic Trouble Code Fault Type";
BA_ "SignalLongName" SG_ 1838 DTCI_ECM_DTCNumber "Diagnostic Trouble Code Information Extended - ECM : Diagnostic Trouble Code Number";
BA_ "SignalLongName" SG_ 1838 DTCI_ECM_DTCSource "Diagnostic Trouble Code Information Extended - ECM : Diagnostic Trouble Code Source";
BA_ "SignalType" SG_ 1838 DTCI_ECM_TstNCmpltdOpCyc "ENM";
BA_ "SignalLongName" SG_ 1838 DTCI_ECM_TstNCmpltdOpCyc "Diagnostic Trouble Code Information Extended - ECM : Test Not Completed This Operation Cycle";
BA_ "SignalType" SG_ 1838 DTCI_ECM_TstNCmpltdLstClr "ENM";
BA_ "SignalLongName" SG_ 1838 DTCI_ECM_TstNCmpltdLstClr "Diagnostic Trouble Code Information Extended - ECM : Test Not Completed Since Last Clear";
BA_ "SignalType" SG_ 1838 DTCI_ECM_TstFldOpCyc "ENM";
BA_ "SignalLongName" SG_ 1838 DTCI_ECM_TstFldOpCyc "Diagnostic Trouble Code Information Extended - ECM : Test Failed This Operation Cycle";
BA_ "SignalType" SG_ 1838 DTCI_ECM_TstFldLstClr "ENM";
BA_ "SignalLongName" SG_ 1838 DTCI_ECM_TstFldLstClr "Diagnostic Trouble Code Information Extended - ECM : Test Failed Since Last Clear";
BA_ "SignalType" SG_ 1838 DTCI_ECM_TstFld "ENM";
BA_ "SignalLongName" SG_ 1838 DTCI_ECM_TstFld "Diagnostic Trouble Code Information Extended - ECM : Test Failed";
BA_ "SignalType" SG_ 1838 DTCI_ECM_PndngDTC "ENM";
BA_ "SignalLongName" SG_ 1838 DTCI_ECM_PndngDTC "Diagnostic Trouble Code Information Extended - ECM : Pending DTC";
BA_ "SignalType" SG_ 1838 DTCI_ECM_DTCTriggered "ENM";
BA_ "SignalLongName" SG_ 1838 DTCI_ECM_DTCTriggered "Diagnostic Trouble Code Information Extended - ECM : Diagnostic Trouble Code Triggered";
BA_ "SignalType" SG_ 1838 DTCI_ECM_WrnIndTrggrd "ENM";
BA_ "SignalLongName" SG_ 1838 DTCI_ECM_WrnIndTrggrd "Diagnostic Trouble Code Information Extended - ECM : Warning Indicator Triggered";
BA_ "SignalType" SG_ 1838 DTCI_ECM_WrnIndRqd "ENM";
BA_ "SignalLongName" SG_ 1838 DTCI_ECM_WrnIndRqd "Diagnostic Trouble Code Information Extended - ECM : Warning Indicator Requested";
BA_ "SignalLongName" SG_ 1839 DTCI_ECP_E_DTCFailType "Diagnostic Trouble Code Information Extended - ECP_E : Diagnostic Trouble Code Failure Type";
BA_ "SignalType" SG_ 1839 DTCI_ECP_E_CnfrmdDTC "ENM";
BA_ "SignalLongName" SG_ 1839 DTCI_ECP_E_CnfrmdDTC "Diagnostic Trouble Code Information Extended - ECP_E : Confirmed DTC";
BA_ "SignalType" SG_ 1839 DTCI_ECP_E_DTCFaultType "ENM";
BA_ "SignalLongName" SG_ 1839 DTCI_ECP_E_DTCFaultType "Diagnostic Trouble Code Information Extended - ECP_E : Diagnostic Trouble Code Fault Type";
BA_ "SignalLongName" SG_ 1839 DTCI_ECP_E_DTCNumber "Diagnostic Trouble Code Information Extended - ECP_E : Diagnostic Trouble Code Number";
BA_ "SignalLongName" SG_ 1839 DTCI_ECP_E_DTCSource "Diagnostic Trouble Code Information Extended - ECP_E : Diagnostic Trouble Code Source";
BA_ "SignalType" SG_ 1839 DTCI_ECP_E_TstNCmpltdOpCyc "ENM";
BA_ "SignalLongName" SG_ 1839 DTCI_ECP_E_TstNCmpltdOpCyc "Diagnostic Trouble Code Information Extended - ECP_E : Test Not Completed This Operation Cycle";
BA_ "SignalType" SG_ 1839 DTCI_ECP_E_TstNCmpltdLstClr "ENM";
BA_ "SignalLongName" SG_ 1839 DTCI_ECP_E_TstNCmpltdLstClr "Diagnostic Trouble Code Information Extended - ECP_E : Test Not Completed Since Last Clear";
BA_ "SignalType" SG_ 1839 DTCI_ECP_E_TstFldOpCyc "ENM";
BA_ "SignalLongName" SG_ 1839 DTCI_ECP_E_TstFldOpCyc "Diagnostic Trouble Code Information Extended - ECP_E : Test Failed This Operation Cycle";
BA_ "SignalType" SG_ 1839 DTCI_ECP_E_TstFldLstClr "ENM";
BA_ "SignalLongName" SG_ 1839 DTCI_ECP_E_TstFldLstClr "Diagnostic Trouble Code Information Extended - ECP_E : Test Failed Since Last Clear";
BA_ "SignalType" SG_ 1839 DTCI_ECP_E_TstFld "ENM";
BA_ "SignalLongName" SG_ 1839 DTCI_ECP_E_TstFld "Diagnostic Trouble Code Information Extended - ECP_E : Test Failed";
BA_ "SignalType" SG_ 1839 DTCI_ECP_E_PndngDTC "ENM";
BA_ "SignalLongName" SG_ 1839 DTCI_ECP_E_PndngDTC "Diagnostic Trouble Code Information Extended - ECP_E : Pending DTC";
BA_ "SignalType" SG_ 1839 DTCI_ECP_E_DTCTriggered "ENM";
BA_ "SignalLongName" SG_ 1839 DTCI_ECP_E_DTCTriggered "Diagnostic Trouble Code Information Extended - ECP_E : Diagnostic Trouble Code Triggered";
BA_ "SignalType" SG_ 1839 DTCI_ECP_E_WrnIndTrggrd "ENM";
BA_ "SignalLongName" SG_ 1839 DTCI_ECP_E_WrnIndTrggrd "Diagnostic Trouble Code Information Extended - ECP_E : Warning Indicator Triggered";
BA_ "SignalType" SG_ 1839 DTCI_ECP_E_WrnIndRqd "ENM";
BA_ "SignalLongName" SG_ 1839 DTCI_ECP_E_WrnIndRqd "Diagnostic Trouble Code Information Extended - ECP_E : Warning Indicator Requested";
BA_ "SignalLongName" SG_ 1116 DTCI_ECP_H1_DTCFailType "Diagnostic Trouble Code Information Extended - ECP_H1 : Diagnostic Trouble Code Failure Type";
BA_ "SignalType" SG_ 1116 DTCI_ECP_H1_CnfrmdDTC "ENM";
BA_ "SignalLongName" SG_ 1116 DTCI_ECP_H1_CnfrmdDTC "Diagnostic Trouble Code Information Extended - ECP_H1 : Confirmed DTC";
BA_ "SignalType" SG_ 1116 DTCI_ECP_H1_DTCFaultType "ENM";
BA_ "SignalLongName" SG_ 1116 DTCI_ECP_H1_DTCFaultType "Diagnostic Trouble Code Information Extended - ECP_H1 : Diagnostic Trouble Code Fault Type";
BA_ "SignalLongName" SG_ 1116 DTCI_ECP_H1_DTCNumber "Diagnostic Trouble Code Information Extended - ECP_H1 : Diagnostic Trouble Code Number";
BA_ "SignalLongName" SG_ 1116 DTCI_ECP_H1_DTCSource "Diagnostic Trouble Code Information Extended - ECP_H1 : Diagnostic Trouble Code Source";
BA_ "SignalType" SG_ 1116 DTCI_ECP_H1_TstNCmpltdOpCyc "ENM";
BA_ "SignalLongName" SG_ 1116 DTCI_ECP_H1_TstNCmpltdOpCyc "Diagnostic Trouble Code Information Extended - ECP_H1 : Test Not Completed This Operation Cycle";
BA_ "SignalType" SG_ 1116 DTCI_ECP_H1_TstNCmpltdLstClr "ENM";
BA_ "SignalLongName" SG_ 1116 DTCI_ECP_H1_TstNCmpltdLstClr "Diagnostic Trouble Code Information Extended - ECP_H1 : Test Not Completed Since Last Clear";
BA_ "SignalType" SG_ 1116 DTCI_ECP_H1_TstFldOpCyc "ENM";
BA_ "SignalLongName" SG_ 1116 DTCI_ECP_H1_TstFldOpCyc "Diagnostic Trouble Code Information Extended - ECP_H1 : Test Failed This Operation Cycle";
BA_ "SignalType" SG_ 1116 DTCI_ECP_H1_TstFldLstClr "ENM";
BA_ "SignalLongName" SG_ 1116 DTCI_ECP_H1_TstFldLstClr "Diagnostic Trouble Code Information Extended - ECP_H1 : Test Failed Since Last Clear";
BA_ "SignalType" SG_ 1116 DTCI_ECP_H1_TstFld "ENM";
BA_ "SignalLongName" SG_ 1116 DTCI_ECP_H1_TstFld "Diagnostic Trouble Code Information Extended - ECP_H1 : Test Failed";
BA_ "SignalType" SG_ 1116 DTCI_ECP_H1_PndngDTC "ENM";
BA_ "SignalLongName" SG_ 1116 DTCI_ECP_H1_PndngDTC "Diagnostic Trouble Code Information Extended - ECP_H1 : Pending DTC";
BA_ "SignalType" SG_ 1116 DTCI_ECP_H1_DTCTriggered "ENM";
BA_ "SignalLongName" SG_ 1116 DTCI_ECP_H1_DTCTriggered "Diagnostic Trouble Code Information Extended - ECP_H1 : Diagnostic Trouble Code Triggered";
BA_ "SignalType" SG_ 1116 DTCI_ECP_H1_WrnIndTrggrd "ENM";
BA_ "SignalLongName" SG_ 1116 DTCI_ECP_H1_WrnIndTrggrd "Diagnostic Trouble Code Information Extended - ECP_H1 : Warning Indicator Triggered";
BA_ "SignalType" SG_ 1116 DTCI_ECP_H1_WrnIndRqd "ENM";
BA_ "SignalLongName" SG_ 1116 DTCI_ECP_H1_WrnIndRqd "Diagnostic Trouble Code Information Extended - ECP_H1 : Warning Indicator Requested";
BA_ "SignalLongName" SG_ 1951 DTCI_ECP_H2_DTCFailType "Diagnostic Trouble Code Information Extended - ECP_H2 : Diagnostic Trouble Code Failure Type";
BA_ "SignalType" SG_ 1951 DTCI_ECP_H2_CnfrmdDTC "ENM";
BA_ "SignalLongName" SG_ 1951 DTCI_ECP_H2_CnfrmdDTC "Diagnostic Trouble Code Information Extended - ECP_H2 : Confirmed DTC";
BA_ "SignalType" SG_ 1951 DTCI_ECP_H2_DTCFaultType "ENM";
BA_ "SignalLongName" SG_ 1951 DTCI_ECP_H2_DTCFaultType "Diagnostic Trouble Code Information Extended - ECP_H2 : Diagnostic Trouble Code Fault Type";
BA_ "SignalLongName" SG_ 1951 DTCI_ECP_H2_DTCNumber "Diagnostic Trouble Code Information Extended - ECP_H2 : Diagnostic Trouble Code Number";
BA_ "SignalLongName" SG_ 1951 DTCI_ECP_H2_DTCSource "Diagnostic Trouble Code Information Extended - ECP_H2 : Diagnostic Trouble Code Source";
BA_ "SignalType" SG_ 1951 DTCI_ECP_H2_TstNCmpltdOpCyc "ENM";
BA_ "SignalLongName" SG_ 1951 DTCI_ECP_H2_TstNCmpltdOpCyc "Diagnostic Trouble Code Information Extended - ECP_H2 : Test Not Completed This Operation Cycle";
BA_ "SignalType" SG_ 1951 DTCI_ECP_H2_TstNCmpltdLstClr "ENM";
BA_ "SignalLongName" SG_ 1951 DTCI_ECP_H2_TstNCmpltdLstClr "Diagnostic Trouble Code Information Extended - ECP_H2 : Test Not Completed Since Last Clear";
BA_ "SignalType" SG_ 1951 DTCI_ECP_H2_TstFldOpCyc "ENM";
BA_ "SignalLongName" SG_ 1951 DTCI_ECP_H2_TstFldOpCyc "Diagnostic Trouble Code Information Extended - ECP_H2 : Test Failed This Operation Cycle";
BA_ "SignalType" SG_ 1951 DTCI_ECP_H2_TstFldLstClr "ENM";
BA_ "SignalLongName" SG_ 1951 DTCI_ECP_H2_TstFldLstClr "Diagnostic Trouble Code Information Extended - ECP_H2 : Test Failed Since Last Clear";
BA_ "SignalType" SG_ 1951 DTCI_ECP_H2_TstFld "ENM";
BA_ "SignalLongName" SG_ 1951 DTCI_ECP_H2_TstFld "Diagnostic Trouble Code Information Extended - ECP_H2 : Test Failed";
BA_ "SignalType" SG_ 1951 DTCI_ECP_H2_PndngDTC "ENM";
BA_ "SignalLongName" SG_ 1951 DTCI_ECP_H2_PndngDTC "Diagnostic Trouble Code Information Extended - ECP_H2 : Pending DTC";
BA_ "SignalType" SG_ 1951 DTCI_ECP_H2_DTCTriggered "ENM";
BA_ "SignalLongName" SG_ 1951 DTCI_ECP_H2_DTCTriggered "Diagnostic Trouble Code Information Extended - ECP_H2 : Diagnostic Trouble Code Triggered";
BA_ "SignalType" SG_ 1951 DTCI_ECP_H2_WrnIndTrggrd "ENM";
BA_ "SignalLongName" SG_ 1951 DTCI_ECP_H2_WrnIndTrggrd "Diagnostic Trouble Code Information Extended - ECP_H2 : Warning Indicator Triggered";
BA_ "SignalType" SG_ 1951 DTCI_ECP_H2_WrnIndRqd "ENM";
BA_ "SignalLongName" SG_ 1951 DTCI_ECP_H2_WrnIndRqd "Diagnostic Trouble Code Information Extended - ECP_H2 : Warning Indicator Requested";
BA_ "SignalLongName" SG_ 1115 DTCI_ECP_H3_DTCFailType "Diagnostic Trouble Code Information Extended - ECP_H3 : Diagnostic Trouble Code Failure Type";
BA_ "SignalType" SG_ 1115 DTCI_ECP_H3_CnfrmdDTC "ENM";
BA_ "SignalLongName" SG_ 1115 DTCI_ECP_H3_CnfrmdDTC "Diagnostic Trouble Code Information Extended - ECP_H3 : Confirmed DTC";
BA_ "SignalType" SG_ 1115 DTCI_ECP_H3_DTCFaultType "ENM";
BA_ "SignalLongName" SG_ 1115 DTCI_ECP_H3_DTCFaultType "Diagnostic Trouble Code Information Extended - ECP_H3 : Diagnostic Trouble Code Fault Type";
BA_ "SignalLongName" SG_ 1115 DTCI_ECP_H3_DTCNumber "Diagnostic Trouble Code Information Extended - ECP_H3 : Diagnostic Trouble Code Number";
BA_ "SignalLongName" SG_ 1115 DTCI_ECP_H3_DTCSource "Diagnostic Trouble Code Information Extended - ECP_H3 : Diagnostic Trouble Code Source";
BA_ "SignalType" SG_ 1115 DTCI_ECP_H3_TstNCmpltdOpCyc "ENM";
BA_ "SignalLongName" SG_ 1115 DTCI_ECP_H3_TstNCmpltdOpCyc "Diagnostic Trouble Code Information Extended - ECP_H3 : Test Not Completed This Operation Cycle";
BA_ "SignalType" SG_ 1115 DTCI_ECP_H3_TstNCmpltdLstClr "ENM";
BA_ "SignalLongName" SG_ 1115 DTCI_ECP_H3_TstNCmpltdLstClr "Diagnostic Trouble Code Information Extended - ECP_H3 : Test Not Completed Since Last Clear";
BA_ "SignalType" SG_ 1115 DTCI_ECP_H3_TstFldOpCyc "ENM";
BA_ "SignalLongName" SG_ 1115 DTCI_ECP_H3_TstFldOpCyc "Diagnostic Trouble Code Information Extended - ECP_H3 : Test Failed This Operation Cycle";
BA_ "SignalType" SG_ 1115 DTCI_ECP_H3_TstFldLstClr "ENM";
BA_ "SignalLongName" SG_ 1115 DTCI_ECP_H3_TstFldLstClr "Diagnostic Trouble Code Information Extended - ECP_H3 : Test Failed Since Last Clear";
BA_ "SignalType" SG_ 1115 DTCI_ECP_H3_TstFld "ENM";
BA_ "SignalLongName" SG_ 1115 DTCI_ECP_H3_TstFld "Diagnostic Trouble Code Information Extended - ECP_H3 : Test Failed";
BA_ "SignalType" SG_ 1115 DTCI_ECP_H3_PndngDTC "ENM";
BA_ "SignalLongName" SG_ 1115 DTCI_ECP_H3_PndngDTC "Diagnostic Trouble Code Information Extended - ECP_H3 : Pending DTC";
BA_ "SignalType" SG_ 1115 DTCI_ECP_H3_DTCTriggered "ENM";
BA_ "SignalLongName" SG_ 1115 DTCI_ECP_H3_DTCTriggered "Diagnostic Trouble Code Information Extended - ECP_H3 : Diagnostic Trouble Code Triggered";
BA_ "SignalType" SG_ 1115 DTCI_ECP_H3_WrnIndTrggrd "ENM";
BA_ "SignalLongName" SG_ 1115 DTCI_ECP_H3_WrnIndTrggrd "Diagnostic Trouble Code Information Extended - ECP_H3 : Warning Indicator Triggered";
BA_ "SignalType" SG_ 1115 DTCI_ECP_H3_WrnIndRqd "ENM";
BA_ "SignalLongName" SG_ 1115 DTCI_ECP_H3_WrnIndRqd "Diagnostic Trouble Code Information Extended - ECP_H3 : Warning Indicator Requested";
BA_ "SignalLongName" SG_ 1226 DTCI_ECP_MC_DTCFailType "Diagnostic Trouble Code Information Extended - ECP_MC : Diagnostic Trouble Code Failure Type";
BA_ "SignalType" SG_ 1226 DTCI_ECP_MC_CnfrmdDTC "ENM";
BA_ "SignalLongName" SG_ 1226 DTCI_ECP_MC_CnfrmdDTC "Diagnostic Trouble Code Information Extended - ECP_MC : Confirmed DTC";
BA_ "SignalType" SG_ 1226 DTCI_ECP_MC_DTCFaultType "ENM";
BA_ "SignalLongName" SG_ 1226 DTCI_ECP_MC_DTCFaultType "Diagnostic Trouble Code Information Extended - ECP_MC : Diagnostic Trouble Code Fault Type";
BA_ "SignalLongName" SG_ 1226 DTCI_ECP_MC_DTCNumber "Diagnostic Trouble Code Information Extended - ECP_MC : Diagnostic Trouble Code Number";
BA_ "SignalLongName" SG_ 1226 DTCI_ECP_MC_DTCSource "Diagnostic Trouble Code Information Extended - ECP_MC : Diagnostic Trouble Code Source";
BA_ "SignalType" SG_ 1226 DTCI_ECP_MC_TstNCmpltdOpCyc "ENM";
BA_ "SignalLongName" SG_ 1226 DTCI_ECP_MC_TstNCmpltdOpCyc "Diagnostic Trouble Code Information Extended - ECP_MC : Test Not Completed This Operation Cycle";
BA_ "SignalType" SG_ 1226 DTCI_ECP_MC_TstNCmpltdLstClr "ENM";
BA_ "SignalLongName" SG_ 1226 DTCI_ECP_MC_TstNCmpltdLstClr "Diagnostic Trouble Code Information Extended - ECP_MC : Test Not Completed Since Last Clear";
BA_ "SignalType" SG_ 1226 DTCI_ECP_MC_TstFldOpCyc "ENM";
BA_ "SignalLongName" SG_ 1226 DTCI_ECP_MC_TstFldOpCyc "Diagnostic Trouble Code Information Extended - ECP_MC : Test Failed This Operation Cycle";
BA_ "SignalType" SG_ 1226 DTCI_ECP_MC_TstFldLstClr "ENM";
BA_ "SignalLongName" SG_ 1226 DTCI_ECP_MC_TstFldLstClr "Diagnostic Trouble Code Information Extended - ECP_MC : Test Failed Since Last Clear";
BA_ "SignalType" SG_ 1226 DTCI_ECP_MC_TstFld "ENM";
BA_ "SignalLongName" SG_ 1226 DTCI_ECP_MC_TstFld "Diagnostic Trouble Code Information Extended - ECP_MC : Test Failed";
BA_ "SignalType" SG_ 1226 DTCI_ECP_MC_PndngDTC "ENM";
BA_ "SignalLongName" SG_ 1226 DTCI_ECP_MC_PndngDTC "Diagnostic Trouble Code Information Extended - ECP_MC : Pending DTC";
BA_ "SignalType" SG_ 1226 DTCI_ECP_MC_DTCTriggered "ENM";
BA_ "SignalLongName" SG_ 1226 DTCI_ECP_MC_DTCTriggered "Diagnostic Trouble Code Information Extended - ECP_MC : Diagnostic Trouble Code Triggered";
BA_ "SignalType" SG_ 1226 DTCI_ECP_MC_WrnIndTrggrd "ENM";
BA_ "SignalLongName" SG_ 1226 DTCI_ECP_MC_WrnIndTrggrd "Diagnostic Trouble Code Information Extended - ECP_MC : Warning Indicator Triggered";
BA_ "SignalType" SG_ 1226 DTCI_ECP_MC_WrnIndRqd "ENM";
BA_ "SignalLongName" SG_ 1226 DTCI_ECP_MC_WrnIndRqd "Diagnostic Trouble Code Information Extended - ECP_MC : Warning Indicator Requested";
BA_ "SignalLongName" SG_ 1227 DTCI_ECP_S2_DTCFailType "Diagnostic Trouble Code Information Extended - ECP_S2 : Diagnostic Trouble Code Failure Type";
BA_ "SignalType" SG_ 1227 DTCI_ECP_S2_CnfrmdDTC "ENM";
BA_ "SignalLongName" SG_ 1227 DTCI_ECP_S2_CnfrmdDTC "Diagnostic Trouble Code Information Extended - ECP_S2 : Confirmed DTC";
BA_ "SignalType" SG_ 1227 DTCI_ECP_S2_DTCFaultType "ENM";
BA_ "SignalLongName" SG_ 1227 DTCI_ECP_S2_DTCFaultType "Diagnostic Trouble Code Information Extended - ECP_S2 : Diagnostic Trouble Code Fault Type";
BA_ "SignalLongName" SG_ 1227 DTCI_ECP_S2_DTCNumber "Diagnostic Trouble Code Information Extended - ECP_S2 : Diagnostic Trouble Code Number";
BA_ "SignalLongName" SG_ 1227 DTCI_ECP_S2_DTCSource "Diagnostic Trouble Code Information Extended - ECP_S2 : Diagnostic Trouble Code Source";
BA_ "SignalType" SG_ 1227 DTCI_ECP_S2_TstNCmpltdOpCyc "ENM";
BA_ "SignalLongName" SG_ 1227 DTCI_ECP_S2_TstNCmpltdOpCyc "Diagnostic Trouble Code Information Extended - ECP_S2 : Test Not Completed This Operation Cycle";
BA_ "SignalType" SG_ 1227 DTCI_ECP_S2_TstNCmpltdLstClr "ENM";
BA_ "SignalLongName" SG_ 1227 DTCI_ECP_S2_TstNCmpltdLstClr "Diagnostic Trouble Code Information Extended - ECP_S2 : Test Not Completed Since Last Clear";
BA_ "SignalType" SG_ 1227 DTCI_ECP_S2_TstFldOpCyc "ENM";
BA_ "SignalLongName" SG_ 1227 DTCI_ECP_S2_TstFldOpCyc "Diagnostic Trouble Code Information Extended - ECP_S2 : Test Failed This Operation Cycle";
BA_ "SignalType" SG_ 1227 DTCI_ECP_S2_TstFldLstClr "ENM";
BA_ "SignalLongName" SG_ 1227 DTCI_ECP_S2_TstFldLstClr "Diagnostic Trouble Code Information Extended - ECP_S2 : Test Failed Since Last Clear";
BA_ "SignalType" SG_ 1227 DTCI_ECP_S2_TstFld "ENM";
BA_ "SignalLongName" SG_ 1227 DTCI_ECP_S2_TstFld "Diagnostic Trouble Code Information Extended - ECP_S2 : Test Failed";
BA_ "SignalType" SG_ 1227 DTCI_ECP_S2_PndngDTC "ENM";
BA_ "SignalLongName" SG_ 1227 DTCI_ECP_S2_PndngDTC "Diagnostic Trouble Code Information Extended - ECP_S2 : Pending DTC";
BA_ "SignalType" SG_ 1227 DTCI_ECP_S2_DTCTriggered "ENM";
BA_ "SignalLongName" SG_ 1227 DTCI_ECP_S2_DTCTriggered "Diagnostic Trouble Code Information Extended - ECP_S2 : Diagnostic Trouble Code Triggered";
BA_ "SignalType" SG_ 1227 DTCI_ECP_S2_WrnIndTrggrd "ENM";
BA_ "SignalLongName" SG_ 1227 DTCI_ECP_S2_WrnIndTrggrd "Diagnostic Trouble Code Information Extended - ECP_S2 : Warning Indicator Triggered";
BA_ "SignalType" SG_ 1227 DTCI_ECP_S2_WrnIndRqd "ENM";
BA_ "SignalLongName" SG_ 1227 DTCI_ECP_S2_WrnIndRqd "Diagnostic Trouble Code Information Extended - ECP_S2 : Warning Indicator Requested";
BA_ "SignalLongName" SG_ 1840 DTCI_ECP_S_DTCFailType "Diagnostic Trouble Code Information Extended - ECP_S : Diagnostic Trouble Code Failure Type";
BA_ "SignalType" SG_ 1840 DTCI_ECP_S_CnfrmdDTC "ENM";
BA_ "SignalLongName" SG_ 1840 DTCI_ECP_S_CnfrmdDTC "Diagnostic Trouble Code Information Extended - ECP_S : Confirmed DTC";
BA_ "SignalType" SG_ 1840 DTCI_ECP_S_DTCFaultType "ENM";
BA_ "SignalLongName" SG_ 1840 DTCI_ECP_S_DTCFaultType "Diagnostic Trouble Code Information Extended - ECP_S : Diagnostic Trouble Code Fault Type";
BA_ "SignalLongName" SG_ 1840 DTCI_ECP_S_DTCNumber "Diagnostic Trouble Code Information Extended - ECP_S : Diagnostic Trouble Code Number";
BA_ "SignalLongName" SG_ 1840 DTCI_ECP_S_DTCSource "Diagnostic Trouble Code Information Extended - ECP_S : Diagnostic Trouble Code Source";
BA_ "SignalType" SG_ 1840 DTCI_ECP_S_TstNCmpltdOpCyc "ENM";
BA_ "SignalLongName" SG_ 1840 DTCI_ECP_S_TstNCmpltdOpCyc "Diagnostic Trouble Code Information Extended - ECP_S : Test Not Completed This Operation Cycle";
BA_ "SignalType" SG_ 1840 DTCI_ECP_S_TstNCmpltdLstClr "ENM";
BA_ "SignalLongName" SG_ 1840 DTCI_ECP_S_TstNCmpltdLstClr "Diagnostic Trouble Code Information Extended - ECP_S : Test Not Completed Since Last Clear";
BA_ "SignalType" SG_ 1840 DTCI_ECP_S_TstFldOpCyc "ENM";
BA_ "SignalLongName" SG_ 1840 DTCI_ECP_S_TstFldOpCyc "Diagnostic Trouble Code Information Extended - ECP_S : Test Failed This Operation Cycle";
BA_ "SignalType" SG_ 1840 DTCI_ECP_S_TstFldLstClr "ENM";
BA_ "SignalLongName" SG_ 1840 DTCI_ECP_S_TstFldLstClr "Diagnostic Trouble Code Information Extended - ECP_S : Test Failed Since Last Clear";
BA_ "SignalType" SG_ 1840 DTCI_ECP_S_TstFld "ENM";
BA_ "SignalLongName" SG_ 1840 DTCI_ECP_S_TstFld "Diagnostic Trouble Code Information Extended - ECP_S : Test Failed";
BA_ "SignalType" SG_ 1840 DTCI_ECP_S_PndngDTC "ENM";
BA_ "SignalLongName" SG_ 1840 DTCI_ECP_S_PndngDTC "Diagnostic Trouble Code Information Extended - ECP_S : Pending DTC";
BA_ "SignalType" SG_ 1840 DTCI_ECP_S_DTCTriggered "ENM";
BA_ "SignalLongName" SG_ 1840 DTCI_ECP_S_DTCTriggered "Diagnostic Trouble Code Information Extended - ECP_S : Diagnostic Trouble Code Triggered";
BA_ "SignalType" SG_ 1840 DTCI_ECP_S_WrnIndTrggrd "ENM";
BA_ "SignalLongName" SG_ 1840 DTCI_ECP_S_WrnIndTrggrd "Diagnostic Trouble Code Information Extended - ECP_S : Warning Indicator Triggered";
BA_ "SignalType" SG_ 1840 DTCI_ECP_S_WrnIndRqd "ENM";
BA_ "SignalLongName" SG_ 1840 DTCI_ECP_S_WrnIndRqd "Diagnostic Trouble Code Information Extended - ECP_S : Warning Indicator Requested";
BA_ "SignalLongName" SG_ 1225 DTCI_ECP_X1_DTCFailType "Diagnostic Trouble Code Information Extended - ECP_X1 : Diagnostic Trouble Code Failure Type";
BA_ "SignalType" SG_ 1225 DTCI_ECP_X1_CnfrmdDTC "ENM";
BA_ "SignalLongName" SG_ 1225 DTCI_ECP_X1_CnfrmdDTC "Diagnostic Trouble Code Information Extended - ECP_X1 : Confirmed DTC";
BA_ "SignalType" SG_ 1225 DTCI_ECP_X1_DTCFaultType "ENM";
BA_ "SignalLongName" SG_ 1225 DTCI_ECP_X1_DTCFaultType "Diagnostic Trouble Code Information Extended - ECP_X1 : Diagnostic Trouble Code Fault Type";
BA_ "SignalLongName" SG_ 1225 DTCI_ECP_X1_DTCNumber "Diagnostic Trouble Code Information Extended - ECP_X1 : Diagnostic Trouble Code Number";
BA_ "SignalLongName" SG_ 1225 DTCI_ECP_X1_DTCSource "Diagnostic Trouble Code Information Extended - ECP_X1 : Diagnostic Trouble Code Source";
BA_ "SignalType" SG_ 1225 DTCI_ECP_X1_TstNCmpltdOpCyc "ENM";
BA_ "SignalLongName" SG_ 1225 DTCI_ECP_X1_TstNCmpltdOpCyc "Diagnostic Trouble Code Information Extended - ECP_X1 : Test Not Completed This Operation Cycle";
BA_ "SignalType" SG_ 1225 DTCI_ECP_X1_TstNCmpltdLstClr "ENM";
BA_ "SignalLongName" SG_ 1225 DTCI_ECP_X1_TstNCmpltdLstClr "Diagnostic Trouble Code Information Extended - ECP_X1 : Test Not Completed Since Last Clear";
BA_ "SignalType" SG_ 1225 DTCI_ECP_X1_TstFldOpCyc "ENM";
BA_ "SignalLongName" SG_ 1225 DTCI_ECP_X1_TstFldOpCyc "Diagnostic Trouble Code Information Extended - ECP_X1 : Test Failed This Operation Cycle";
BA_ "SignalType" SG_ 1225 DTCI_ECP_X1_TstFldLstClr "ENM";
BA_ "SignalLongName" SG_ 1225 DTCI_ECP_X1_TstFldLstClr "Diagnostic Trouble Code Information Extended - ECP_X1 : Test Failed Since Last Clear";
BA_ "SignalType" SG_ 1225 DTCI_ECP_X1_TstFld "ENM";
BA_ "SignalLongName" SG_ 1225 DTCI_ECP_X1_TstFld "Diagnostic Trouble Code Information Extended - ECP_X1 : Test Failed";
BA_ "SignalType" SG_ 1225 DTCI_ECP_X1_PndngDTC "ENM";
BA_ "SignalLongName" SG_ 1225 DTCI_ECP_X1_PndngDTC "Diagnostic Trouble Code Information Extended - ECP_X1 : Pending DTC";
BA_ "SignalType" SG_ 1225 DTCI_ECP_X1_DTCTriggered "ENM";
BA_ "SignalLongName" SG_ 1225 DTCI_ECP_X1_DTCTriggered "Diagnostic Trouble Code Information Extended - ECP_X1 : Diagnostic Trouble Code Triggered";
BA_ "SignalType" SG_ 1225 DTCI_ECP_X1_WrnIndTrggrd "ENM";
BA_ "SignalLongName" SG_ 1225 DTCI_ECP_X1_WrnIndTrggrd "Diagnostic Trouble Code Information Extended - ECP_X1 : Warning Indicator Triggered";
BA_ "SignalType" SG_ 1225 DTCI_ECP_X1_WrnIndRqd "ENM";
BA_ "SignalLongName" SG_ 1225 DTCI_ECP_X1_WrnIndRqd "Diagnostic Trouble Code Information Extended - ECP_X1 : Warning Indicator Requested";
BA_ "SignalLongName" SG_ 1841 DTCI_ELM_DTCFailType "Diagnostic Trouble Code Information Extended - ELM : Diagnostic Trouble Code Failure Type";
BA_ "SignalType" SG_ 1841 DTCI_ELM_CnfrmdDTC "ENM";
BA_ "SignalLongName" SG_ 1841 DTCI_ELM_CnfrmdDTC "Diagnostic Trouble Code Information Extended - ELM : Confirmed DTC";
BA_ "SignalType" SG_ 1841 DTCI_ELM_DTCFaultType "ENM";
BA_ "SignalLongName" SG_ 1841 DTCI_ELM_DTCFaultType "Diagnostic Trouble Code Information Extended - ELM : Diagnostic Trouble Code Fault Type";
BA_ "SignalLongName" SG_ 1841 DTCI_ELM_DTCNumber "Diagnostic Trouble Code Information Extended - ELM : Diagnostic Trouble Code Number";
BA_ "SignalLongName" SG_ 1841 DTCI_ELM_DTCSource "Diagnostic Trouble Code Information Extended - ELM : Diagnostic Trouble Code Source";
BA_ "SignalType" SG_ 1841 DTCI_ELM_TstNCmpltdOpCyc "ENM";
BA_ "SignalLongName" SG_ 1841 DTCI_ELM_TstNCmpltdOpCyc "Diagnostic Trouble Code Information Extended - ELM : Test Not Completed This Operation Cycle";
BA_ "SignalType" SG_ 1841 DTCI_ELM_TstNCmpltdLstClr "ENM";
BA_ "SignalLongName" SG_ 1841 DTCI_ELM_TstNCmpltdLstClr "Diagnostic Trouble Code Information Extended - ELM : Test Not Completed Since Last Clear";
BA_ "SignalType" SG_ 1841 DTCI_ELM_TstFldOpCyc "ENM";
BA_ "SignalLongName" SG_ 1841 DTCI_ELM_TstFldOpCyc "Diagnostic Trouble Code Information Extended - ELM : Test Failed This Operation Cycle";
BA_ "SignalType" SG_ 1841 DTCI_ELM_TstFldLstClr "ENM";
BA_ "SignalLongName" SG_ 1841 DTCI_ELM_TstFldLstClr "Diagnostic Trouble Code Information Extended - ELM : Test Failed Since Last Clear";
BA_ "SignalType" SG_ 1841 DTCI_ELM_TstFld "ENM";
BA_ "SignalLongName" SG_ 1841 DTCI_ELM_TstFld "Diagnostic Trouble Code Information Extended - ELM : Test Failed";
BA_ "SignalType" SG_ 1841 DTCI_ELM_PndngDTC "ENM";
BA_ "SignalLongName" SG_ 1841 DTCI_ELM_PndngDTC "Diagnostic Trouble Code Information Extended - ELM : Pending DTC";
BA_ "SignalType" SG_ 1841 DTCI_ELM_DTCTriggered "ENM";
BA_ "SignalLongName" SG_ 1841 DTCI_ELM_DTCTriggered "Diagnostic Trouble Code Information Extended - ELM : Diagnostic Trouble Code Triggered";
BA_ "SignalType" SG_ 1841 DTCI_ELM_WrnIndTrggrd "ENM";
BA_ "SignalLongName" SG_ 1841 DTCI_ELM_WrnIndTrggrd "Diagnostic Trouble Code Information Extended - ELM : Warning Indicator Triggered";
BA_ "SignalType" SG_ 1841 DTCI_ELM_WrnIndRqd "ENM";
BA_ "SignalLongName" SG_ 1841 DTCI_ELM_WrnIndRqd "Diagnostic Trouble Code Information Extended - ELM : Warning Indicator Requested";
BA_ "SignalLongName" SG_ 1224 DTCI_EOCM_HCP1_DTCFailType "Diagnostic Trouble Code Information Extended - EOCM_HCP1 : Diagnostic Trouble Code Failure Type";
BA_ "SignalType" SG_ 1224 DTCI_EOCM_HCP1_CnfrmdDTC "ENM";
BA_ "SignalLongName" SG_ 1224 DTCI_EOCM_HCP1_CnfrmdDTC "Diagnostic Trouble Code Information Extended - EOCM_HCP1 : Confirmed DTC";
BA_ "SignalType" SG_ 1224 DTCI_EOCM_HCP1_DTCFaultType "ENM";
BA_ "SignalLongName" SG_ 1224 DTCI_EOCM_HCP1_DTCFaultType "Diagnostic Trouble Code Information Extended - EOCM_HCP1 : Diagnostic Trouble Code Fault Type";
BA_ "SignalLongName" SG_ 1224 DTCI_EOCM_HCP1_DTCNumber "Diagnostic Trouble Code Information Extended - EOCM_HCP1 : Diagnostic Trouble Code Number";
BA_ "SignalLongName" SG_ 1224 DTCI_EOCM_HCP1_DTCSource "Diagnostic Trouble Code Information Extended - EOCM_HCP1 : Diagnostic Trouble Code Source";
BA_ "SignalType" SG_ 1224 DTCI_EOCM_HCP1_TstNCmpltdOpCyc "ENM";
BA_ "SignalLongName" SG_ 1224 DTCI_EOCM_HCP1_TstNCmpltdOpCyc "Diagnostic Trouble Code Information Extended - EOCM_HCP1 : Test Not Completed This Operation Cycle";
BA_ "SignalType" SG_ 1224 DTCI_EOCM_HCP1_TstNCmpltdLstClr "ENM";
BA_ "SignalLongName" SG_ 1224 DTCI_EOCM_HCP1_TstNCmpltdLstClr "Diagnostic Trouble Code Information Extended - EOCM_HCP1 : Test Not Completed Since Last Clear";
BA_ "SignalType" SG_ 1224 DTCI_EOCM_HCP1_TstFldOpCyc "ENM";
BA_ "SignalLongName" SG_ 1224 DTCI_EOCM_HCP1_TstFldOpCyc "Diagnostic Trouble Code Information Extended - EOCM_HCP1 : Test Failed This Operation Cycle";
BA_ "SignalType" SG_ 1224 DTCI_EOCM_HCP1_TstFldLstClr "ENM";
BA_ "SignalLongName" SG_ 1224 DTCI_EOCM_HCP1_TstFldLstClr "Diagnostic Trouble Code Information Extended - EOCM_HCP1 : Test Failed Since Last Clear";
BA_ "SignalType" SG_ 1224 DTCI_EOCM_HCP1_TstFld "ENM";
BA_ "SignalLongName" SG_ 1224 DTCI_EOCM_HCP1_TstFld "Diagnostic Trouble Code Information Extended - EOCM_HCP1 : Test Failed";
BA_ "SignalType" SG_ 1224 DTCI_EOCM_HCP1_PndngDTC "ENM";
BA_ "SignalLongName" SG_ 1224 DTCI_EOCM_HCP1_PndngDTC "Diagnostic Trouble Code Information Extended - EOCM_HCP1 : Pending DTC";
BA_ "SignalType" SG_ 1224 DTCI_EOCM_HCP1_DTCTriggered "ENM";
BA_ "SignalLongName" SG_ 1224 DTCI_EOCM_HCP1_DTCTriggered "Diagnostic Trouble Code Information Extended - EOCM_HCP1 : Diagnostic Trouble Code Triggered";
BA_ "SignalType" SG_ 1224 DTCI_EOCM_HCP1_WrnIndTrggrd "ENM";
BA_ "SignalLongName" SG_ 1224 DTCI_EOCM_HCP1_WrnIndTrggrd "Diagnostic Trouble Code Information Extended - EOCM_HCP1 : Warning Indicator Triggered";
BA_ "SignalType" SG_ 1224 DTCI_EOCM_HCP1_WrnIndRqd "ENM";
BA_ "SignalLongName" SG_ 1224 DTCI_EOCM_HCP1_WrnIndRqd "Diagnostic Trouble Code Information Extended - EOCM_HCP1 : Warning Indicator Requested";
BA_ "SignalLongName" SG_ 1842 DTCI_EOCM_HCP2_DTCFailType "Diagnostic Trouble Code Information Extended - EOCM_HCP2 : Diagnostic Trouble Code Failure Type";
BA_ "SignalType" SG_ 1842 DTCI_EOCM_HCP2_CnfrmdDTC "ENM";
BA_ "SignalLongName" SG_ 1842 DTCI_EOCM_HCP2_CnfrmdDTC "Diagnostic Trouble Code Information Extended - EOCM_HCP2 : Confirmed DTC";
BA_ "SignalType" SG_ 1842 DTCI_EOCM_HCP2_DTCFaultType "ENM";
BA_ "SignalLongName" SG_ 1842 DTCI_EOCM_HCP2_DTCFaultType "Diagnostic Trouble Code Information Extended - EOCM_HCP2 : Diagnostic Trouble Code Fault Type";
BA_ "SignalLongName" SG_ 1842 DTCI_EOCM_HCP2_DTCNumber "Diagnostic Trouble Code Information Extended - EOCM_HCP2 : Diagnostic Trouble Code Number";
BA_ "SignalLongName" SG_ 1842 DTCI_EOCM_HCP2_DTCSource "Diagnostic Trouble Code Information Extended - EOCM_HCP2 : Diagnostic Trouble Code Source";
BA_ "SignalType" SG_ 1842 DTCI_EOCM_HCP2_TstNCmpltdOpCyc "ENM";
BA_ "SignalLongName" SG_ 1842 DTCI_EOCM_HCP2_TstNCmpltdOpCyc "Diagnostic Trouble Code Information Extended - EOCM_HCP2 : Test Not Completed This Operation Cycle";
BA_ "SignalType" SG_ 1842 DTCI_EOCM_HCP2_TstNCmpltdLstClr "ENM";
BA_ "SignalLongName" SG_ 1842 DTCI_EOCM_HCP2_TstNCmpltdLstClr "Diagnostic Trouble Code Information Extended - EOCM_HCP2 : Test Not Completed Since Last Clear";
BA_ "SignalType" SG_ 1842 DTCI_EOCM_HCP2_TstFldOpCyc "ENM";
BA_ "SignalLongName" SG_ 1842 DTCI_EOCM_HCP2_TstFldOpCyc "Diagnostic Trouble Code Information Extended - EOCM_HCP2 : Test Failed This Operation Cycle";
BA_ "SignalType" SG_ 1842 DTCI_EOCM_HCP2_TstFldLstClr "ENM";
BA_ "SignalLongName" SG_ 1842 DTCI_EOCM_HCP2_TstFldLstClr "Diagnostic Trouble Code Information Extended - EOCM_HCP2 : Test Failed Since Last Clear";
BA_ "SignalType" SG_ 1842 DTCI_EOCM_HCP2_TstFld "ENM";
BA_ "SignalLongName" SG_ 1842 DTCI_EOCM_HCP2_TstFld "Diagnostic Trouble Code Information Extended - EOCM_HCP2 : Test Failed";
BA_ "SignalType" SG_ 1842 DTCI_EOCM_HCP2_PndngDTC "ENM";
BA_ "SignalLongName" SG_ 1842 DTCI_EOCM_HCP2_PndngDTC "Diagnostic Trouble Code Information Extended - EOCM_HCP2 : Pending DTC";
BA_ "SignalType" SG_ 1842 DTCI_EOCM_HCP2_DTCTriggered "ENM";
BA_ "SignalLongName" SG_ 1842 DTCI_EOCM_HCP2_DTCTriggered "Diagnostic Trouble Code Information Extended - EOCM_HCP2 : Diagnostic Trouble Code Triggered";
BA_ "SignalType" SG_ 1842 DTCI_EOCM_HCP2_WrnIndTrggrd "ENM";
BA_ "SignalLongName" SG_ 1842 DTCI_EOCM_HCP2_WrnIndTrggrd "Diagnostic Trouble Code Information Extended - EOCM_HCP2 : Warning Indicator Triggered";
BA_ "SignalType" SG_ 1842 DTCI_EOCM_HCP2_WrnIndRqd "ENM";
BA_ "SignalLongName" SG_ 1842 DTCI_EOCM_HCP2_WrnIndRqd "Diagnostic Trouble Code Information Extended - EOCM_HCP2 : Warning Indicator Requested";
BA_ "SignalLongName" SG_ 1223 DTCI_EOCM_DTCFailType "Diagnostic Trouble Code Information Extended - EOCM : Diagnostic Trouble Code Failure Type";
BA_ "SignalType" SG_ 1223 DTCI_EOCM_CnfrmdDTC "ENM";
BA_ "SignalLongName" SG_ 1223 DTCI_EOCM_CnfrmdDTC "Diagnostic Trouble Code Information Extended - EOCM : Confirmed DTC";
BA_ "SignalType" SG_ 1223 DTCI_EOCM_DTCFaultType "ENM";
BA_ "SignalLongName" SG_ 1223 DTCI_EOCM_DTCFaultType "Diagnostic Trouble Code Information Extended - EOCM : Diagnostic Trouble Code Fault Type";
BA_ "SignalLongName" SG_ 1223 DTCI_EOCM_DTCNumber "Diagnostic Trouble Code Information Extended - EOCM : Diagnostic Trouble Code Number";
BA_ "SignalLongName" SG_ 1223 DTCI_EOCM_DTCSource "Diagnostic Trouble Code Information Extended - EOCM : Diagnostic Trouble Code Source";
BA_ "SignalType" SG_ 1223 DTCI_EOCM_TstNCmpltdOpCyc "ENM";
BA_ "SignalLongName" SG_ 1223 DTCI_EOCM_TstNCmpltdOpCyc "Diagnostic Trouble Code Information Extended - EOCM : Test Not Completed This Operation Cycle";
BA_ "SignalType" SG_ 1223 DTCI_EOCM_TstNCmpltdLstClr "ENM";
BA_ "SignalLongName" SG_ 1223 DTCI_EOCM_TstNCmpltdLstClr "Diagnostic Trouble Code Information Extended - EOCM : Test Not Completed Since Last Clear";
BA_ "SignalType" SG_ 1223 DTCI_EOCM_TstFldOpCyc "ENM";
BA_ "SignalLongName" SG_ 1223 DTCI_EOCM_TstFldOpCyc "Diagnostic Trouble Code Information Extended - EOCM : Test Failed This Operation Cycle";
BA_ "SignalType" SG_ 1223 DTCI_EOCM_TstFldLstClr "ENM";
BA_ "SignalLongName" SG_ 1223 DTCI_EOCM_TstFldLstClr "Diagnostic Trouble Code Information Extended - EOCM : Test Failed Since Last Clear";
BA_ "SignalType" SG_ 1223 DTCI_EOCM_TstFld "ENM";
BA_ "SignalLongName" SG_ 1223 DTCI_EOCM_TstFld "Diagnostic Trouble Code Information Extended - EOCM : Test Failed";
BA_ "SignalType" SG_ 1223 DTCI_EOCM_PndngDTC "ENM";
BA_ "SignalLongName" SG_ 1223 DTCI_EOCM_PndngDTC "Diagnostic Trouble Code Information Extended - EOCM : Pending DTC";
BA_ "SignalType" SG_ 1223 DTCI_EOCM_DTCTriggered "ENM";
BA_ "SignalLongName" SG_ 1223 DTCI_EOCM_DTCTriggered "Diagnostic Trouble Code Information Extended - EOCM : Diagnostic Trouble Code Triggered";
BA_ "SignalType" SG_ 1223 DTCI_EOCM_WrnIndTrggrd "ENM";
BA_ "SignalLongName" SG_ 1223 DTCI_EOCM_WrnIndTrggrd "Diagnostic Trouble Code Information Extended - EOCM : Warning Indicator Triggered";
BA_ "SignalType" SG_ 1223 DTCI_EOCM_WrnIndRqd "ENM";
BA_ "SignalLongName" SG_ 1223 DTCI_EOCM_WrnIndRqd "Diagnostic Trouble Code Information Extended - EOCM : Warning Indicator Requested";
BA_ "SignalLongName" SG_ 1895 DTCI_EPS_1_DTCFailType "Diagnostic Trouble Code Information Extended - EPS_1 : Diagnostic Trouble Code Failure Type";
BA_ "SignalType" SG_ 1895 DTCI_EPS_1_CnfrmdDTC "ENM";
BA_ "SignalLongName" SG_ 1895 DTCI_EPS_1_CnfrmdDTC "Diagnostic Trouble Code Information Extended - EPS_1 : Confirmed DTC";
BA_ "SignalType" SG_ 1895 DTCI_EPS_1_DTCFaultType "ENM";
BA_ "SignalLongName" SG_ 1895 DTCI_EPS_1_DTCFaultType "Diagnostic Trouble Code Information Extended - EPS_1 : Diagnostic Trouble Code Fault Type";
BA_ "SignalLongName" SG_ 1895 DTCI_EPS_1_DTCNumber "Diagnostic Trouble Code Information Extended - EPS_1 : Diagnostic Trouble Code Number";
BA_ "SignalLongName" SG_ 1895 DTCI_EPS_1_DTCSource "Diagnostic Trouble Code Information Extended - EPS_1 : Diagnostic Trouble Code Source";
BA_ "SignalType" SG_ 1895 DTCI_EPS_1_TstNCmpltdOpCyc "ENM";
BA_ "SignalLongName" SG_ 1895 DTCI_EPS_1_TstNCmpltdOpCyc "Diagnostic Trouble Code Information Extended - EPS_1 : Test Not Completed This Operation Cycle";
BA_ "SignalType" SG_ 1895 DTCI_EPS_1_TstNCmpltdLstClr "ENM";
BA_ "SignalLongName" SG_ 1895 DTCI_EPS_1_TstNCmpltdLstClr "Diagnostic Trouble Code Information Extended - EPS_1 : Test Not Completed Since Last Clear";
BA_ "SignalType" SG_ 1895 DTCI_EPS_1_TstFldOpCyc "ENM";
BA_ "SignalLongName" SG_ 1895 DTCI_EPS_1_TstFldOpCyc "Diagnostic Trouble Code Information Extended - EPS_1 : Test Failed This Operation Cycle";
BA_ "SignalType" SG_ 1895 DTCI_EPS_1_TstFldLstClr "ENM";
BA_ "SignalLongName" SG_ 1895 DTCI_EPS_1_TstFldLstClr "Diagnostic Trouble Code Information Extended - EPS_1 : Test Failed Since Last Clear";
BA_ "SignalType" SG_ 1895 DTCI_EPS_1_TstFld "ENM";
BA_ "SignalLongName" SG_ 1895 DTCI_EPS_1_TstFld "Diagnostic Trouble Code Information Extended - EPS_1 : Test Failed";
BA_ "SignalType" SG_ 1895 DTCI_EPS_1_PndngDTC "ENM";
BA_ "SignalLongName" SG_ 1895 DTCI_EPS_1_PndngDTC "Diagnostic Trouble Code Information Extended - EPS_1 : Pending DTC";
BA_ "SignalType" SG_ 1895 DTCI_EPS_1_DTCTriggered "ENM";
BA_ "SignalLongName" SG_ 1895 DTCI_EPS_1_DTCTriggered "Diagnostic Trouble Code Information Extended - EPS_1 : Diagnostic Trouble Code Triggered";
BA_ "SignalType" SG_ 1895 DTCI_EPS_1_WrnIndTrggrd "ENM";
BA_ "SignalLongName" SG_ 1895 DTCI_EPS_1_WrnIndTrggrd "Diagnostic Trouble Code Information Extended - EPS_1 : Warning Indicator Triggered";
BA_ "SignalType" SG_ 1895 DTCI_EPS_1_WrnIndRqd "ENM";
BA_ "SignalLongName" SG_ 1895 DTCI_EPS_1_WrnIndRqd "Diagnostic Trouble Code Information Extended - EPS_1 : Warning Indicator Requested";
BA_ "SignalLongName" SG_ 1843 DTCI_EPS_DTCFailType "Diagnostic Trouble Code Information Extended - EPS : Diagnostic Trouble Code Failure Type";
BA_ "SignalType" SG_ 1843 DTCI_EPS_CnfrmdDTC "ENM";
BA_ "SignalLongName" SG_ 1843 DTCI_EPS_CnfrmdDTC "Diagnostic Trouble Code Information Extended - EPS : Confirmed DTC";
BA_ "SignalType" SG_ 1843 DTCI_EPS_DTCFaultType "ENM";
BA_ "SignalLongName" SG_ 1843 DTCI_EPS_DTCFaultType "Diagnostic Trouble Code Information Extended - EPS : Diagnostic Trouble Code Fault Type";
BA_ "SignalLongName" SG_ 1843 DTCI_EPS_DTCNumber "Diagnostic Trouble Code Information Extended - EPS : Diagnostic Trouble Code Number";
BA_ "SignalLongName" SG_ 1843 DTCI_EPS_DTCSource "Diagnostic Trouble Code Information Extended - EPS : Diagnostic Trouble Code Source";
BA_ "SignalType" SG_ 1843 DTCI_EPS_TstNCmpltdOpCyc "ENM";
BA_ "SignalLongName" SG_ 1843 DTCI_EPS_TstNCmpltdOpCyc "Diagnostic Trouble Code Information Extended - EPS : Test Not Completed This Operation Cycle";
BA_ "SignalType" SG_ 1843 DTCI_EPS_TstNCmpltdLstClr "ENM";
BA_ "SignalLongName" SG_ 1843 DTCI_EPS_TstNCmpltdLstClr "Diagnostic Trouble Code Information Extended - EPS : Test Not Completed Since Last Clear";
BA_ "SignalType" SG_ 1843 DTCI_EPS_TstFldOpCyc "ENM";
BA_ "SignalLongName" SG_ 1843 DTCI_EPS_TstFldOpCyc "Diagnostic Trouble Code Information Extended - EPS : Test Failed This Operation Cycle";
BA_ "SignalType" SG_ 1843 DTCI_EPS_TstFldLstClr "ENM";
BA_ "SignalLongName" SG_ 1843 DTCI_EPS_TstFldLstClr "Diagnostic Trouble Code Information Extended - EPS : Test Failed Since Last Clear";
BA_ "SignalType" SG_ 1843 DTCI_EPS_TstFld "ENM";
BA_ "SignalLongName" SG_ 1843 DTCI_EPS_TstFld "Diagnostic Trouble Code Information Extended - EPS : Test Failed";
BA_ "SignalType" SG_ 1843 DTCI_EPS_PndngDTC "ENM";
BA_ "SignalLongName" SG_ 1843 DTCI_EPS_PndngDTC "Diagnostic Trouble Code Information Extended - EPS : Pending DTC";
BA_ "SignalType" SG_ 1843 DTCI_EPS_DTCTriggered "ENM";
BA_ "SignalLongName" SG_ 1843 DTCI_EPS_DTCTriggered "Diagnostic Trouble Code Information Extended - EPS : Diagnostic Trouble Code Triggered";
BA_ "SignalType" SG_ 1843 DTCI_EPS_WrnIndTrggrd "ENM";
BA_ "SignalLongName" SG_ 1843 DTCI_EPS_WrnIndTrggrd "Diagnostic Trouble Code Information Extended - EPS : Warning Indicator Triggered";
BA_ "SignalType" SG_ 1843 DTCI_EPS_WrnIndRqd "ENM";
BA_ "SignalLongName" SG_ 1843 DTCI_EPS_WrnIndRqd "Diagnostic Trouble Code Information Extended - EPS : Warning Indicator Requested";
BA_ "SignalLongName" SG_ 1222 DTCI_EPSb_DTCFailType "Diagnostic Trouble Code Information Extended - EPSb : Diagnostic Trouble Code Failure Type";
BA_ "SignalType" SG_ 1222 DTCI_EPSb_CnfrmdDTC "ENM";
BA_ "SignalLongName" SG_ 1222 DTCI_EPSb_CnfrmdDTC "Diagnostic Trouble Code Information Extended - EPSb : Confirmed DTC";
BA_ "SignalType" SG_ 1222 DTCI_EPSb_DTCFaultType "ENM";
BA_ "SignalLongName" SG_ 1222 DTCI_EPSb_DTCFaultType "Diagnostic Trouble Code Information Extended - EPSb : Diagnostic Trouble Code Fault Type";
BA_ "SignalLongName" SG_ 1222 DTCI_EPSb_DTCNumber "Diagnostic Trouble Code Information Extended - EPSb : Diagnostic Trouble Code Number";
BA_ "SignalLongName" SG_ 1222 DTCI_EPSb_DTCSource "Diagnostic Trouble Code Information Extended - EPSb : Diagnostic Trouble Code Source";
BA_ "SignalType" SG_ 1222 DTCI_EPSb_TstNCmpltdOpCyc "ENM";
BA_ "SignalLongName" SG_ 1222 DTCI_EPSb_TstNCmpltdOpCyc "Diagnostic Trouble Code Information Extended - EPSb : Test Not Completed This Operation Cycle";
BA_ "SignalType" SG_ 1222 DTCI_EPSb_TstNCmpltdLstClr "ENM";
BA_ "SignalLongName" SG_ 1222 DTCI_EPSb_TstNCmpltdLstClr "Diagnostic Trouble Code Information Extended - EPSb : Test Not Completed Since Last Clear";
BA_ "SignalType" SG_ 1222 DTCI_EPSb_TstFldOpCyc "ENM";
BA_ "SignalLongName" SG_ 1222 DTCI_EPSb_TstFldOpCyc "Diagnostic Trouble Code Information Extended - EPSb : Test Failed This Operation Cycle";
BA_ "SignalType" SG_ 1222 DTCI_EPSb_TstFldLstClr "ENM";
BA_ "SignalLongName" SG_ 1222 DTCI_EPSb_TstFldLstClr "Diagnostic Trouble Code Information Extended - EPSb : Test Failed Since Last Clear";
BA_ "SignalType" SG_ 1222 DTCI_EPSb_TstFld "ENM";
BA_ "SignalLongName" SG_ 1222 DTCI_EPSb_TstFld "Diagnostic Trouble Code Information Extended - EPSb : Test Failed";
BA_ "SignalType" SG_ 1222 DTCI_EPSb_PndngDTC "ENM";
BA_ "SignalLongName" SG_ 1222 DTCI_EPSb_PndngDTC "Diagnostic Trouble Code Information Extended - EPSb : Pending DTC";
BA_ "SignalType" SG_ 1222 DTCI_EPSb_DTCTriggered "ENM";
BA_ "SignalLongName" SG_ 1222 DTCI_EPSb_DTCTriggered "Diagnostic Trouble Code Information Extended - EPSb : Diagnostic Trouble Code Triggered";
BA_ "SignalType" SG_ 1222 DTCI_EPSb_WrnIndTrggrd "ENM";
BA_ "SignalLongName" SG_ 1222 DTCI_EPSb_WrnIndTrggrd "Diagnostic Trouble Code Information Extended - EPSb : Warning Indicator Triggered";
BA_ "SignalType" SG_ 1222 DTCI_EPSb_WrnIndRqd "ENM";
BA_ "SignalLongName" SG_ 1222 DTCI_EPSb_WrnIndRqd "Diagnostic Trouble Code Information Extended - EPSb : Warning Indicator Requested";
BA_ "SignalLongName" SG_ 1844 DTCI_FCM_LC_DTCFailType "Diagnostic Trouble Code Information Extended - FCM_LC : Diagnostic Trouble Code Failure Type";
BA_ "SignalType" SG_ 1844 DTCI_FCM_LC_CnfrmdDTC "ENM";
BA_ "SignalLongName" SG_ 1844 DTCI_FCM_LC_CnfrmdDTC "Diagnostic Trouble Code Information Extended - FCM_LC : Confirmed DTC";
BA_ "SignalType" SG_ 1844 DTCI_FCM_LC_DTCFaultType "ENM";
BA_ "SignalLongName" SG_ 1844 DTCI_FCM_LC_DTCFaultType "Diagnostic Trouble Code Information Extended - FCM_LC : Diagnostic Trouble Code Fault Type";
BA_ "SignalLongName" SG_ 1844 DTCI_FCM_LC_DTCNumber "Diagnostic Trouble Code Information Extended - FCM_LC : Diagnostic Trouble Code Number";
BA_ "SignalLongName" SG_ 1844 DTCI_FCM_LC_DTCSource "Diagnostic Trouble Code Information Extended - FCM_LC : Diagnostic Trouble Code Source";
BA_ "SignalType" SG_ 1844 DTCI_FCM_LC_TstNCmpltdOpCyc "ENM";
BA_ "SignalLongName" SG_ 1844 DTCI_FCM_LC_TstNCmpltdOpCyc "Diagnostic Trouble Code Information Extended - FCM_LC : Test Not Completed This Operation Cycle";
BA_ "SignalType" SG_ 1844 DTCI_FCM_LC_TstNCmpltdLstClr "ENM";
BA_ "SignalLongName" SG_ 1844 DTCI_FCM_LC_TstNCmpltdLstClr "Diagnostic Trouble Code Information Extended - FCM_LC : Test Not Completed Since Last Clear";
BA_ "SignalType" SG_ 1844 DTCI_FCM_LC_TstFldOpCyc "ENM";
BA_ "SignalLongName" SG_ 1844 DTCI_FCM_LC_TstFldOpCyc "Diagnostic Trouble Code Information Extended - FCM_LC : Test Failed This Operation Cycle";
BA_ "SignalType" SG_ 1844 DTCI_FCM_LC_TstFldLstClr "ENM";
BA_ "SignalLongName" SG_ 1844 DTCI_FCM_LC_TstFldLstClr "Diagnostic Trouble Code Information Extended - FCM_LC : Test Failed Since Last Clear";
BA_ "SignalType" SG_ 1844 DTCI_FCM_LC_TstFld "ENM";
BA_ "SignalLongName" SG_ 1844 DTCI_FCM_LC_TstFld "Diagnostic Trouble Code Information Extended - FCM_LC : Test Failed";
BA_ "SignalType" SG_ 1844 DTCI_FCM_LC_PndngDTC "ENM";
BA_ "SignalLongName" SG_ 1844 DTCI_FCM_LC_PndngDTC "Diagnostic Trouble Code Information Extended - FCM_LC : Pending DTC";
BA_ "SignalType" SG_ 1844 DTCI_FCM_LC_DTCTriggered "ENM";
BA_ "SignalLongName" SG_ 1844 DTCI_FCM_LC_DTCTriggered "Diagnostic Trouble Code Information Extended - FCM_LC : Diagnostic Trouble Code Triggered";
BA_ "SignalType" SG_ 1844 DTCI_FCM_LC_WrnIndTrggrd "ENM";
BA_ "SignalLongName" SG_ 1844 DTCI_FCM_LC_WrnIndTrggrd "Diagnostic Trouble Code Information Extended - FCM_LC : Warning Indicator Triggered";
BA_ "SignalType" SG_ 1844 DTCI_FCM_LC_WrnIndRqd "ENM";
BA_ "SignalLongName" SG_ 1844 DTCI_FCM_LC_WrnIndRqd "Diagnostic Trouble Code Information Extended - FCM_LC : Warning Indicator Requested";
BA_ "SignalLongName" SG_ 1221 DTCI_FCM_DTCFailType "Diagnostic Trouble Code Information Extended - FCM : Diagnostic Trouble Code Failure Type";
BA_ "SignalType" SG_ 1221 DTCI_FCM_CnfrmdDTC "ENM";
BA_ "SignalLongName" SG_ 1221 DTCI_FCM_CnfrmdDTC "Diagnostic Trouble Code Information Extended - FCM : Confirmed DTC";
BA_ "SignalType" SG_ 1221 DTCI_FCM_DTCFaultType "ENM";
BA_ "SignalLongName" SG_ 1221 DTCI_FCM_DTCFaultType "Diagnostic Trouble Code Information Extended - FCM : Diagnostic Trouble Code Fault Type";
BA_ "SignalLongName" SG_ 1221 DTCI_FCM_DTCNumber "Diagnostic Trouble Code Information Extended - FCM : Diagnostic Trouble Code Number";
BA_ "SignalLongName" SG_ 1221 DTCI_FCM_DTCSource "Diagnostic Trouble Code Information Extended - FCM : Diagnostic Trouble Code Source";
BA_ "SignalType" SG_ 1221 DTCI_FCM_TstNCmpltdOpCyc "ENM";
BA_ "SignalLongName" SG_ 1221 DTCI_FCM_TstNCmpltdOpCyc "Diagnostic Trouble Code Information Extended - FCM : Test Not Completed This Operation Cycle";
BA_ "SignalType" SG_ 1221 DTCI_FCM_TstNCmpltdLstClr "ENM";
BA_ "SignalLongName" SG_ 1221 DTCI_FCM_TstNCmpltdLstClr "Diagnostic Trouble Code Information Extended - FCM : Test Not Completed Since Last Clear";
BA_ "SignalType" SG_ 1221 DTCI_FCM_TstFldOpCyc "ENM";
BA_ "SignalLongName" SG_ 1221 DTCI_FCM_TstFldOpCyc "Diagnostic Trouble Code Information Extended - FCM : Test Failed This Operation Cycle";
BA_ "SignalType" SG_ 1221 DTCI_FCM_TstFldLstClr "ENM";
BA_ "SignalLongName" SG_ 1221 DTCI_FCM_TstFldLstClr "Diagnostic Trouble Code Information Extended - FCM : Test Failed Since Last Clear";
BA_ "SignalType" SG_ 1221 DTCI_FCM_TstFld "ENM";
BA_ "SignalLongName" SG_ 1221 DTCI_FCM_TstFld "Diagnostic Trouble Code Information Extended - FCM : Test Failed";
BA_ "SignalType" SG_ 1221 DTCI_FCM_PndngDTC "ENM";
BA_ "SignalLongName" SG_ 1221 DTCI_FCM_PndngDTC "Diagnostic Trouble Code Information Extended - FCM : Pending DTC";
BA_ "SignalType" SG_ 1221 DTCI_FCM_DTCTriggered "ENM";
BA_ "SignalLongName" SG_ 1221 DTCI_FCM_DTCTriggered "Diagnostic Trouble Code Information Extended - FCM : Diagnostic Trouble Code Triggered";
BA_ "SignalType" SG_ 1221 DTCI_FCM_WrnIndTrggrd "ENM";
BA_ "SignalLongName" SG_ 1221 DTCI_FCM_WrnIndTrggrd "Diagnostic Trouble Code Information Extended - FCM : Warning Indicator Triggered";
BA_ "SignalType" SG_ 1221 DTCI_FCM_WrnIndRqd "ENM";
BA_ "SignalLongName" SG_ 1221 DTCI_FCM_WrnIndRqd "Diagnostic Trouble Code Information Extended - FCM : Warning Indicator Requested";
BA_ "SignalLongName" SG_ 1845 DTCI_FOPM_DTCFailType "Diagnostic Trouble Code Information Extended - FOPM : Diagnostic Trouble Code Failure Type";
BA_ "SignalType" SG_ 1845 DTCI_FOPM_CnfrmdDTC "ENM";
BA_ "SignalLongName" SG_ 1845 DTCI_FOPM_CnfrmdDTC "Diagnostic Trouble Code Information Extended - FOPM : Confirmed DTC";
BA_ "SignalType" SG_ 1845 DTCI_FOPM_DTCFaultType "ENM";
BA_ "SignalLongName" SG_ 1845 DTCI_FOPM_DTCFaultType "Diagnostic Trouble Code Information Extended - FOPM : Diagnostic Trouble Code Fault Type";
BA_ "SignalLongName" SG_ 1845 DTCI_FOPM_DTCNumber "Diagnostic Trouble Code Information Extended - FOPM : Diagnostic Trouble Code Number";
BA_ "SignalLongName" SG_ 1845 DTCI_FOPM_DTCSource "Diagnostic Trouble Code Information Extended - FOPM : Diagnostic Trouble Code Source";
BA_ "SignalType" SG_ 1845 DTCI_FOPM_TstNCmpltdOpCyc "ENM";
BA_ "SignalLongName" SG_ 1845 DTCI_FOPM_TstNCmpltdOpCyc "Diagnostic Trouble Code Information Extended - FOPM : Test Not Completed This Operation Cycle";
BA_ "SignalType" SG_ 1845 DTCI_FOPM_TstNCmpltdLstClr "ENM";
BA_ "SignalLongName" SG_ 1845 DTCI_FOPM_TstNCmpltdLstClr "Diagnostic Trouble Code Information Extended - FOPM : Test Not Completed Since Last Clear";
BA_ "SignalType" SG_ 1845 DTCI_FOPM_TstFldOpCyc "ENM";
BA_ "SignalLongName" SG_ 1845 DTCI_FOPM_TstFldOpCyc "Diagnostic Trouble Code Information Extended - FOPM : Test Failed This Operation Cycle";
BA_ "SignalType" SG_ 1845 DTCI_FOPM_TstFldLstClr "ENM";
BA_ "SignalLongName" SG_ 1845 DTCI_FOPM_TstFldLstClr "Diagnostic Trouble Code Information Extended - FOPM : Test Failed Since Last Clear";
BA_ "SignalType" SG_ 1845 DTCI_FOPM_TstFld "ENM";
BA_ "SignalLongName" SG_ 1845 DTCI_FOPM_TstFld "Diagnostic Trouble Code Information Extended - FOPM : Test Failed";
BA_ "SignalType" SG_ 1845 DTCI_FOPM_PndngDTC "ENM";
BA_ "SignalLongName" SG_ 1845 DTCI_FOPM_PndngDTC "Diagnostic Trouble Code Information Extended - FOPM : Pending DTC";
BA_ "SignalType" SG_ 1845 DTCI_FOPM_DTCTriggered "ENM";
BA_ "SignalLongName" SG_ 1845 DTCI_FOPM_DTCTriggered "Diagnostic Trouble Code Information Extended - FOPM : Diagnostic Trouble Code Triggered";
BA_ "SignalType" SG_ 1845 DTCI_FOPM_WrnIndTrggrd "ENM";
BA_ "SignalLongName" SG_ 1845 DTCI_FOPM_WrnIndTrggrd "Diagnostic Trouble Code Information Extended - FOPM : Warning Indicator Triggered";
BA_ "SignalType" SG_ 1845 DTCI_FOPM_WrnIndRqd "ENM";
BA_ "SignalLongName" SG_ 1845 DTCI_FOPM_WrnIndRqd "Diagnostic Trouble Code Information Extended - FOPM : Warning Indicator Requested";
BA_ "SignalLongName" SG_ 1355 DTCI_FPI_DTCFailType "Diagnostic Trouble Code Information Extended - FPI : Diagnostic Trouble Code Failure Type";
BA_ "SignalType" SG_ 1355 DTCI_FPI_CnfrmdDTC "ENM";
BA_ "SignalLongName" SG_ 1355 DTCI_FPI_CnfrmdDTC "Diagnostic Trouble Code Information Extended - FPI : Confirmed DTC";
BA_ "SignalType" SG_ 1355 DTCI_FPI_DTCFaultType "ENM";
BA_ "SignalLongName" SG_ 1355 DTCI_FPI_DTCFaultType "Diagnostic Trouble Code Information Extended - FPI : Diagnostic Trouble Code Fault Type";
BA_ "SignalLongName" SG_ 1355 DTCI_FPI_DTCNumber "Diagnostic Trouble Code Information Extended - FPI : Diagnostic Trouble Code Number";
BA_ "SignalLongName" SG_ 1355 DTCI_FPI_DTCSource "Diagnostic Trouble Code Information Extended - FPI : Diagnostic Trouble Code Source";
BA_ "SignalType" SG_ 1355 DTCI_FPI_TstNCmpltdOpCyc "ENM";
BA_ "SignalLongName" SG_ 1355 DTCI_FPI_TstNCmpltdOpCyc "Diagnostic Trouble Code Information Extended - FPI : Test Not Completed This Operation Cycle";
BA_ "SignalType" SG_ 1355 DTCI_FPI_TstNCmpltdLstClr "ENM";
BA_ "SignalLongName" SG_ 1355 DTCI_FPI_TstNCmpltdLstClr "Diagnostic Trouble Code Information Extended - FPI : Test Not Completed Since Last Clear";
BA_ "SignalType" SG_ 1355 DTCI_FPI_TstFldOpCyc "ENM";
BA_ "SignalLongName" SG_ 1355 DTCI_FPI_TstFldOpCyc "Diagnostic Trouble Code Information Extended - FPI : Test Failed This Operation Cycle";
BA_ "SignalType" SG_ 1355 DTCI_FPI_TstFldLstClr "ENM";
BA_ "SignalLongName" SG_ 1355 DTCI_FPI_TstFldLstClr "Diagnostic Trouble Code Information Extended - FPI : Test Failed Since Last Clear";
BA_ "SignalType" SG_ 1355 DTCI_FPI_TstFld "ENM";
BA_ "SignalLongName" SG_ 1355 DTCI_FPI_TstFld "Diagnostic Trouble Code Information Extended - FPI : Test Failed";
BA_ "SignalType" SG_ 1355 DTCI_FPI_PndngDTC "ENM";
BA_ "SignalLongName" SG_ 1355 DTCI_FPI_PndngDTC "Diagnostic Trouble Code Information Extended - FPI : Pending DTC";
BA_ "SignalType" SG_ 1355 DTCI_FPI_DTCTriggered "ENM";
BA_ "SignalLongName" SG_ 1355 DTCI_FPI_DTCTriggered "Diagnostic Trouble Code Information Extended - FPI : Diagnostic Trouble Code Triggered";
BA_ "SignalType" SG_ 1355 DTCI_FPI_WrnIndTrggrd "ENM";
BA_ "SignalLongName" SG_ 1355 DTCI_FPI_WrnIndTrggrd "Diagnostic Trouble Code Information Extended - FPI : Warning Indicator Triggered";
BA_ "SignalType" SG_ 1355 DTCI_FPI_WrnIndRqd "ENM";
BA_ "SignalLongName" SG_ 1355 DTCI_FPI_WrnIndRqd "Diagnostic Trouble Code Information Extended - FPI : Warning Indicator Requested";
BA_ "SignalLongName" SG_ 1220 DTCI_HDLM_DTCFailType "Diagnostic Trouble Code Information Extended - HDLM : Diagnostic Trouble Code Failure Type";
BA_ "SignalType" SG_ 1220 DTCI_HDLM_CnfrmdDTC "ENM";
BA_ "SignalLongName" SG_ 1220 DTCI_HDLM_CnfrmdDTC "Diagnostic Trouble Code Information Extended - HDLM : Confirmed DTC";
BA_ "SignalType" SG_ 1220 DTCI_HDLM_DTCFaultType "ENM";
BA_ "SignalLongName" SG_ 1220 DTCI_HDLM_DTCFaultType "Diagnostic Trouble Code Information Extended - HDLM : Diagnostic Trouble Code Fault Type";
BA_ "SignalLongName" SG_ 1220 DTCI_HDLM_DTCNumber "Diagnostic Trouble Code Information Extended - HDLM : Diagnostic Trouble Code Number";
BA_ "SignalLongName" SG_ 1220 DTCI_HDLM_DTCSource "Diagnostic Trouble Code Information Extended - HDLM : Diagnostic Trouble Code Source";
BA_ "SignalType" SG_ 1220 DTCI_HDLM_TstNCmpltdOpCyc "ENM";
BA_ "SignalLongName" SG_ 1220 DTCI_HDLM_TstNCmpltdOpCyc "Diagnostic Trouble Code Information Extended - HDLM : Test Not Completed This Operation Cycle";
BA_ "SignalType" SG_ 1220 DTCI_HDLM_TstNCmpltdLstClr "ENM";
BA_ "SignalLongName" SG_ 1220 DTCI_HDLM_TstNCmpltdLstClr "Diagnostic Trouble Code Information Extended - HDLM : Test Not Completed Since Last Clear";
BA_ "SignalType" SG_ 1220 DTCI_HDLM_TstFldOpCyc "ENM";
BA_ "SignalLongName" SG_ 1220 DTCI_HDLM_TstFldOpCyc "Diagnostic Trouble Code Information Extended - HDLM : Test Failed This Operation Cycle";
BA_ "SignalType" SG_ 1220 DTCI_HDLM_TstFldLstClr "ENM";
BA_ "SignalLongName" SG_ 1220 DTCI_HDLM_TstFldLstClr "Diagnostic Trouble Code Information Extended - HDLM : Test Failed Since Last Clear";
BA_ "SignalType" SG_ 1220 DTCI_HDLM_TstFld "ENM";
BA_ "SignalLongName" SG_ 1220 DTCI_HDLM_TstFld "Diagnostic Trouble Code Information Extended - HDLM : Test Failed";
BA_ "SignalType" SG_ 1220 DTCI_HDLM_PndngDTC "ENM";
BA_ "SignalLongName" SG_ 1220 DTCI_HDLM_PndngDTC "Diagnostic Trouble Code Information Extended - HDLM : Pending DTC";
BA_ "SignalType" SG_ 1220 DTCI_HDLM_DTCTriggered "ENM";
BA_ "SignalLongName" SG_ 1220 DTCI_HDLM_DTCTriggered "Diagnostic Trouble Code Information Extended - HDLM : Diagnostic Trouble Code Triggered";
BA_ "SignalType" SG_ 1220 DTCI_HDLM_WrnIndTrggrd "ENM";
BA_ "SignalLongName" SG_ 1220 DTCI_HDLM_WrnIndTrggrd "Diagnostic Trouble Code Information Extended - HDLM : Warning Indicator Triggered";
BA_ "SignalType" SG_ 1220 DTCI_HDLM_WrnIndRqd "ENM";
BA_ "SignalLongName" SG_ 1220 DTCI_HDLM_WrnIndRqd "Diagnostic Trouble Code Information Extended - HDLM : Warning Indicator Requested";
BA_ "SignalLongName" SG_ 1846 DTCI_HUD_CAN_DTCFailType "Diagnostic Trouble Code Information Extended - HUD_CAN : Diagnostic Trouble Code Failure Type";
BA_ "SignalType" SG_ 1846 DTCI_HUD_CAN_CnfrmdDTC "ENM";
BA_ "SignalLongName" SG_ 1846 DTCI_HUD_CAN_CnfrmdDTC "Diagnostic Trouble Code Information Extended - HUD_CAN : Confirmed DTC";
BA_ "SignalType" SG_ 1846 DTCI_HUD_CAN_DTCFaultType "ENM";
BA_ "SignalLongName" SG_ 1846 DTCI_HUD_CAN_DTCFaultType "Diagnostic Trouble Code Information Extended - HUD_CAN : Diagnostic Trouble Code Fault Type";
BA_ "SignalLongName" SG_ 1846 DTCI_HUD_CAN_DTCNumber "Diagnostic Trouble Code Information Extended - HUD_CAN : Diagnostic Trouble Code Number";
BA_ "SignalLongName" SG_ 1846 DTCI_HUD_CAN_DTCSource "Diagnostic Trouble Code Information Extended - HUD_CAN : Diagnostic Trouble Code Source";
BA_ "SignalType" SG_ 1846 DTCI_HUD_CAN_TstNCmpltdOpCyc "ENM";
BA_ "SignalLongName" SG_ 1846 DTCI_HUD_CAN_TstNCmpltdOpCyc "Diagnostic Trouble Code Information Extended - HUD_CAN : Test Not Completed This Operation Cycle";
BA_ "SignalType" SG_ 1846 DTCI_HUD_CAN_TstNCmpltdLstClr "ENM";
BA_ "SignalLongName" SG_ 1846 DTCI_HUD_CAN_TstNCmpltdLstClr "Diagnostic Trouble Code Information Extended - HUD_CAN : Test Not Completed Since Last Clear";
BA_ "SignalType" SG_ 1846 DTCI_HUD_CAN_TstFldOpCyc "ENM";
BA_ "SignalLongName" SG_ 1846 DTCI_HUD_CAN_TstFldOpCyc "Diagnostic Trouble Code Information Extended - HUD_CAN : Test Failed This Operation Cycle";
BA_ "SignalType" SG_ 1846 DTCI_HUD_CAN_TstFldLstClr "ENM";
BA_ "SignalLongName" SG_ 1846 DTCI_HUD_CAN_TstFldLstClr "Diagnostic Trouble Code Information Extended - HUD_CAN : Test Failed Since Last Clear";
BA_ "SignalType" SG_ 1846 DTCI_HUD_CAN_TstFld "ENM";
BA_ "SignalLongName" SG_ 1846 DTCI_HUD_CAN_TstFld "Diagnostic Trouble Code Information Extended - HUD_CAN : Test Failed";
BA_ "SignalType" SG_ 1846 DTCI_HUD_CAN_PndngDTC "ENM";
BA_ "SignalLongName" SG_ 1846 DTCI_HUD_CAN_PndngDTC "Diagnostic Trouble Code Information Extended - HUD_CAN : Pending DTC";
BA_ "SignalType" SG_ 1846 DTCI_HUD_CAN_DTCTriggered "ENM";
BA_ "SignalLongName" SG_ 1846 DTCI_HUD_CAN_DTCTriggered "Diagnostic Trouble Code Information Extended - HUD_CAN : Diagnostic Trouble Code Triggered";
BA_ "SignalType" SG_ 1846 DTCI_HUD_CAN_WrnIndTrggrd "ENM";
BA_ "SignalLongName" SG_ 1846 DTCI_HUD_CAN_WrnIndTrggrd "Diagnostic Trouble Code Information Extended - HUD_CAN : Warning Indicator Triggered";
BA_ "SignalType" SG_ 1846 DTCI_HUD_CAN_WrnIndRqd "ENM";
BA_ "SignalLongName" SG_ 1846 DTCI_HUD_CAN_WrnIndRqd "Diagnostic Trouble Code Information Extended - HUD_CAN : Warning Indicator Requested";
VAL_ 525 APASP_APAStsAuth 0 "Off" 1 "Standby" 2 "Search_Phase" 3 "Exit_Park" 4 "Enabled" 5 "Guidance_Phase" 6 "Finished" 7 "Error" ;
VAL_ 525 APASP_APATransRngReqAuth 0 "No_Request" 1 "Park" 2 "Reverse" 3 "Neutral" 4 "Drive" ;
VAL_ 525 APASP_APATransRngActvnReqdAuth 0 "FALSE" 1 "TRUE" ;
VAL_ 1325 HndsOnLnCntrAsstWrnIndReq 0 "No Indication" 1 "Disabled and Locked out" 2 "Steering Input Not Detected" 3 "Steering Assist Features Unavailable in Selected Driver Mode" 4 "Unavailable" 5 "Driver Attention Alert" 6 "Can't See Face" ;
VAL_ 1325 SuprRmtPrkPwrModeReq 0 "No Request" 1 "Off" 2 "Propulsion" ;
VAL_ 1325 SuprRmtPrkDrLckReq 0 "No Request" 1 "Lock" 2 "Unlock" ;
VAL_ 1325 ASOCNP_LKATakeStrgIndOnAuth 0 "FALSE" 1 "TRUE" ;
VAL_ 618 BGI2P_WshFldLvlIndOnAuth 0 "FALSE" 1 "TRUE" ;
VAL_ 618 BGI2P_ServWprSysDrvIndOnAuth 0 "FALSE" 1 "TRUE" ;
VAL_ 880 BSPMP_BkupSysPwrModeAuth_Inv 0 "FALSE" 1 "TRUE" ;
VAL_ 880 BSPMP_BkupSysPwrModeAuth 0 "Off" 1 "Accessory" 2 "Run" 3 "Start Request" 4 "Propulsion" ;
VAL_ 880 BSPMP_SecRunCrnkCmdActvAuth_Inv 0 "FALSE" 1 "TRUE" ;
VAL_ 880 BSPMP_SecRunCrnkCmdActvAuth 0 "FALSE" 1 "TRUE" ;
VAL_ 880 BSPMP_SecPwrModePBActvAuth_Inv 0 "FALSE" 1 "TRUE" ;
VAL_ 880 BSPMP_SecPwrModePBActvAuth 0 "FALSE" 1 "TRUE" ;
VAL_ 880 BSPMP_RmtProgmActvAuth 0 "FALSE" 1 "TRUE" ;
VAL_ 1306 BSDIP_ESCOffVisIndOnAuth 0 "FALSE" 1 "TRUE" ;
VAL_ 1306 BSDIP_EPBSysWrnIndReqAuth 0 "Off" 1 "On" 2 "0.5_Hz" 3 "1_Hz" 4 "2_Hz" 5 "4_Hz" ;
VAL_ 1306 BSDIP_EPBSysStsIndReqAuth 0 "Off" 1 "On" 2 "0.5_Hz" 3 "1_Hz" 4 "2_Hz" 5 "4_Hz" ;
VAL_ 1306 BSDIP_ABSIndOnAuth 0 "FALSE" 1 "TRUE" ;
VAL_ 1306 BSDIP_TracCtlOffVisIndOnAuth 0 "FALSE" 1 "TRUE" ;
VAL_ 1306 BSDIP_SrvBrkRdBrkTTShrtChIOAuth 0 "FALSE" 1 "TRUE" ;
VAL_ 1306 BSDIP_ServBrkRdBrkTTLngChIOAuth 0 "FALSE" 1 "TRUE" ;
VAL_ 1306 BSDIP_ServBrkBstSrvBrkAssIOAuth 0 "FALSE" 1 "TRUE" ;
VAL_ 1306 BSDIP_ESCVisIndReqAuth 0 "OFF" 1 "ON" 2 "2_Hz" ;
VAL_ 1306 BrkSysBstWrnIndReq 0 "No Indication" 1 "Service Brake Boost" 2 "Brake Assist Failure" 3 "Brake System Failure" ;
VAL_ 1354 DTCI_ACP2_MCU_CnfrmdDTC 0 "FALSE" 1 "TRUE" ;
VAL_ 1354 DTCI_ACP2_MCU_DTCFaultType 0 "Not Supported" 1 "Type A" 2 "Type B" 3 "Type C" ;
VAL_ 1354 DTCI_ACP2_MCU_TstNCmpltdOpCyc 0 "FALSE" 1 "TRUE" ;
VAL_ 1354 DTCI_ACP2_MCU_TstNCmpltdLstClr 0 "FALSE" 1 "TRUE" ;
VAL_ 1354 DTCI_ACP2_MCU_TstFldOpCyc 0 "FALSE" 1 "TRUE" ;
VAL_ 1354 DTCI_ACP2_MCU_TstFldLstClr 0 "FALSE" 1 "TRUE" ;
VAL_ 1354 DTCI_ACP2_MCU_TstFld 0 "FALSE" 1 "TRUE" ;
VAL_ 1354 DTCI_ACP2_MCU_PndngDTC 0 "FALSE" 1 "TRUE" ;
VAL_ 1354 DTCI_ACP2_MCU_DTCTriggered 0 "FALSE" 1 "TRUE" ;
VAL_ 1354 DTCI_ACP2_MCU_WrnIndTrggrd 0 "FALSE" 1 "TRUE" ;
VAL_ 1354 DTCI_ACP2_MCU_WrnIndRqd 0 "FALSE" 1 "TRUE" ;
VAL_ 1321 DTCI_ACP3_MCU_CnfrmdDTC 0 "FALSE" 1 "TRUE" ;
VAL_ 1321 DTCI_ACP3_MCU_DTCFaultType 0 "Not Supported" 1 "Type A" 2 "Type B" 3 "Type C" ;
VAL_ 1321 DTCI_ACP3_MCU_TstNCmpltdOpCyc 0 "FALSE" 1 "TRUE" ;
VAL_ 1321 DTCI_ACP3_MCU_TstNCmpltdLstClr 0 "FALSE" 1 "TRUE" ;
VAL_ 1321 DTCI_ACP3_MCU_TstFldOpCyc 0 "FALSE" 1 "TRUE" ;
VAL_ 1321 DTCI_ACP3_MCU_TstFldLstClr 0 "FALSE" 1 "TRUE" ;
VAL_ 1321 DTCI_ACP3_MCU_TstFld 0 "FALSE" 1 "TRUE" ;
VAL_ 1321 DTCI_ACP3_MCU_PndngDTC 0 "FALSE" 1 "TRUE" ;
VAL_ 1321 DTCI_ACP3_MCU_DTCTriggered 0 "FALSE" 1 "TRUE" ;
VAL_ 1321 DTCI_ACP3_MCU_WrnIndTrggrd 0 "FALSE" 1 "TRUE" ;
VAL_ 1321 DTCI_ACP3_MCU_WrnIndRqd 0 "FALSE" 1 "TRUE" ;
VAL_ 1318 DTCI_ACP4_MCU_CnfrmdDTC 0 "FALSE" 1 "TRUE" ;
VAL_ 1318 DTCI_ACP4_MCU_DTCFaultType 0 "Not Supported" 1 "Type A" 2 "Type B" 3 "Type C" ;
VAL_ 1318 DTCI_ACP4_MCU_TstNCmpltdOpCyc 0 "FALSE" 1 "TRUE" ;
VAL_ 1318 DTCI_ACP4_MCU_TstNCmpltdLstClr 0 "FALSE" 1 "TRUE" ;
VAL_ 1318 DTCI_ACP4_MCU_TstFldOpCyc 0 "FALSE" 1 "TRUE" ;
VAL_ 1318 DTCI_ACP4_MCU_TstFldLstClr 0 "FALSE" 1 "TRUE" ;
VAL_ 1318 DTCI_ACP4_MCU_TstFld 0 "FALSE" 1 "TRUE" ;
VAL_ 1318 DTCI_ACP4_MCU_PndngDTC 0 "FALSE" 1 "TRUE" ;
VAL_ 1318 DTCI_ACP4_MCU_DTCTriggered 0 "FALSE" 1 "TRUE" ;
VAL_ 1318 DTCI_ACP4_MCU_WrnIndTrggrd 0 "FALSE" 1 "TRUE" ;
VAL_ 1318 DTCI_ACP4_MCU_WrnIndRqd 0 "FALSE" 1 "TRUE" ;
VAL_ 1828 DTCI_AHL_AFL_CnfrmdDTC 0 "FALSE" 1 "TRUE" ;
VAL_ 1828 DTCI_AHL_AFL_DTCFaultType 0 "Not Supported" 1 "Type A" 2 "Type B" 3 "Type C" ;
VAL_ 1828 DTCI_AHL_AFL_TstNCmpltdOpCyc 0 "FALSE" 1 "TRUE" ;
VAL_ 1828 DTCI_AHL_AFL_TstNCmpltdLstClr 0 "FALSE" 1 "TRUE" ;
VAL_ 1828 DTCI_AHL_AFL_TstFldOpCyc 0 "FALSE" 1 "TRUE" ;
VAL_ 1828 DTCI_AHL_AFL_TstFldLstClr 0 "FALSE" 1 "TRUE" ;
VAL_ 1828 DTCI_AHL_AFL_TstFld 0 "FALSE" 1 "TRUE" ;
VAL_ 1828 DTCI_AHL_AFL_PndngDTC 0 "FALSE" 1 "TRUE" ;
VAL_ 1828 DTCI_AHL_AFL_DTCTriggered 0 "FALSE" 1 "TRUE" ;
VAL_ 1828 DTCI_AHL_AFL_WrnIndTrggrd 0 "FALSE" 1 "TRUE" ;
VAL_ 1828 DTCI_AHL_AFL_WrnIndRqd 0 "FALSE" 1 "TRUE" ;
VAL_ 1237 DTCI_AHS_CnfrmdDTC 0 "FALSE" 1 "TRUE" ;
VAL_ 1237 DTCI_AHS_DTCFaultType 0 "Not Supported" 1 "Type A" 2 "Type B" 3 "Type C" ;
VAL_ 1237 DTCI_AHS_TstNCmpltdOpCyc 0 "FALSE" 1 "TRUE" ;
VAL_ 1237 DTCI_AHS_TstNCmpltdLstClr 0 "FALSE" 1 "TRUE" ;
VAL_ 1237 DTCI_AHS_TstFldOpCyc 0 "FALSE" 1 "TRUE" ;
VAL_ 1237 DTCI_AHS_TstFldLstClr 0 "FALSE" 1 "TRUE" ;
VAL_ 1237 DTCI_AHS_TstFld 0 "FALSE" 1 "TRUE" ;
VAL_ 1237 DTCI_AHS_PndngDTC 0 "FALSE" 1 "TRUE" ;
VAL_ 1237 DTCI_AHS_DTCTriggered 0 "FALSE" 1 "TRUE" ;
VAL_ 1237 DTCI_AHS_WrnIndTrggrd 0 "FALSE" 1 "TRUE" ;
VAL_ 1237 DTCI_AHS_WrnIndRqd 0 "FALSE" 1 "TRUE" ;
VAL_ 1829 DTCI_ALC_CnfrmdDTC 0 "FALSE" 1 "TRUE" ;
VAL_ 1829 DTCI_ALC_DTCFaultType 0 "Not Supported" 1 "Type A" 2 "Type B" 3 "Type C" ;
VAL_ 1829 DTCI_ALC_TstNCmpltdOpCyc 0 "FALSE" 1 "TRUE" ;
VAL_ 1829 DTCI_ALC_TstNCmpltdLstClr 0 "FALSE" 1 "TRUE" ;
VAL_ 1829 DTCI_ALC_TstFldOpCyc 0 "FALSE" 1 "TRUE" ;
VAL_ 1829 DTCI_ALC_TstFldLstClr 0 "FALSE" 1 "TRUE" ;
VAL_ 1829 DTCI_ALC_TstFld 0 "FALSE" 1 "TRUE" ;
VAL_ 1829 DTCI_ALC_PndngDTC 0 "FALSE" 1 "TRUE" ;
VAL_ 1829 DTCI_ALC_DTCTriggered 0 "FALSE" 1 "TRUE" ;
VAL_ 1829 DTCI_ALC_WrnIndTrggrd 0 "FALSE" 1 "TRUE" ;
VAL_ 1829 DTCI_ALC_WrnIndRqd 0 "FALSE" 1 "TRUE" ;
VAL_ 1236 DTCI_AMP_CnfrmdDTC 0 "FALSE" 1 "TRUE" ;
VAL_ 1236 DTCI_AMP_DTCFaultType 0 "Not Supported" 1 "Type A" 2 "Type B" 3 "Type C" ;
VAL_ 1236 DTCI_AMP_TstNCmpltdOpCyc 0 "FALSE" 1 "TRUE" ;
VAL_ 1236 DTCI_AMP_TstNCmpltdLstClr 0 "FALSE" 1 "TRUE" ;
VAL_ 1236 DTCI_AMP_TstFldOpCyc 0 "FALSE" 1 "TRUE" ;
VAL_ 1236 DTCI_AMP_TstFldLstClr 0 "FALSE" 1 "TRUE" ;
VAL_ 1236 DTCI_AMP_TstFld 0 "FALSE" 1 "TRUE" ;
VAL_ 1236 DTCI_AMP_PndngDTC 0 "FALSE" 1 "TRUE" ;
VAL_ 1236 DTCI_AMP_DTCTriggered 0 "FALSE" 1 "TRUE" ;
VAL_ 1236 DTCI_AMP_WrnIndTrggrd 0 "FALSE" 1 "TRUE" ;
VAL_ 1236 DTCI_AMP_WrnIndRqd 0 "FALSE" 1 "TRUE" ;
VAL_ 1830 DTCI_AOS_CnfrmdDTC 0 "FALSE" 1 "TRUE" ;
VAL_ 1830 DTCI_AOS_DTCFaultType 0 "Not Supported" 1 "Type A" 2 "Type B" 3 "Type C" ;
VAL_ 1830 DTCI_AOS_TstNCmpltdOpCyc 0 "FALSE" 1 "TRUE" ;
VAL_ 1830 DTCI_AOS_TstNCmpltdLstClr 0 "FALSE" 1 "TRUE" ;
VAL_ 1830 DTCI_AOS_TstFldOpCyc 0 "FALSE" 1 "TRUE" ;
VAL_ 1830 DTCI_AOS_TstFldLstClr 0 "FALSE" 1 "TRUE" ;
VAL_ 1830 DTCI_AOS_TstFld 0 "FALSE" 1 "TRUE" ;
VAL_ 1830 DTCI_AOS_PndngDTC 0 "FALSE" 1 "TRUE" ;
VAL_ 1830 DTCI_AOS_DTCTriggered 0 "FALSE" 1 "TRUE" ;
VAL_ 1830 DTCI_AOS_WrnIndTrggrd 0 "FALSE" 1 "TRUE" ;
VAL_ 1830 DTCI_AOS_WrnIndRqd 0 "FALSE" 1 "TRUE" ;
VAL_ 1235 DTCI_APA_CnfrmdDTC 0 "FALSE" 1 "TRUE" ;
VAL_ 1235 DTCI_APA_DTCFaultType 0 "Not Supported" 1 "Type A" 2 "Type B" 3 "Type C" ;
VAL_ 1235 DTCI_APA_TstNCmpltdOpCyc 0 "FALSE" 1 "TRUE" ;
VAL_ 1235 DTCI_APA_TstNCmpltdLstClr 0 "FALSE" 1 "TRUE" ;
VAL_ 1235 DTCI_APA_TstFldOpCyc 0 "FALSE" 1 "TRUE" ;
VAL_ 1235 DTCI_APA_TstFldLstClr 0 "FALSE" 1 "TRUE" ;
VAL_ 1235 DTCI_APA_TstFld 0 "FALSE" 1 "TRUE" ;
VAL_ 1235 DTCI_APA_PndngDTC 0 "FALSE" 1 "TRUE" ;
VAL_ 1235 DTCI_APA_DTCTriggered 0 "FALSE" 1 "TRUE" ;
VAL_ 1235 DTCI_APA_WrnIndTrggrd 0 "FALSE" 1 "TRUE" ;
VAL_ 1235 DTCI_APA_WrnIndRqd 0 "FALSE" 1 "TRUE" ;
VAL_ 1831 DTCI_ARB_CnfrmdDTC 0 "FALSE" 1 "TRUE" ;
VAL_ 1831 DTCI_ARB_DTCFaultType 0 "Not Supported" 1 "Type A" 2 "Type B" 3 "Type C" ;
VAL_ 1831 DTCI_ARB_TstNCmpltdOpCyc 0 "FALSE" 1 "TRUE" ;
VAL_ 1831 DTCI_ARB_TstNCmpltdLstClr 0 "FALSE" 1 "TRUE" ;
VAL_ 1831 DTCI_ARB_TstFldOpCyc 0 "FALSE" 1 "TRUE" ;
VAL_ 1831 DTCI_ARB_TstFldLstClr 0 "FALSE" 1 "TRUE" ;
VAL_ 1831 DTCI_ARB_TstFld 0 "FALSE" 1 "TRUE" ;
VAL_ 1831 DTCI_ARB_PndngDTC 0 "FALSE" 1 "TRUE" ;
VAL_ 1831 DTCI_ARB_DTCTriggered 0 "FALSE" 1 "TRUE" ;
VAL_ 1831 DTCI_ARB_WrnIndTrggrd 0 "FALSE" 1 "TRUE" ;
VAL_ 1831 DTCI_ARB_WrnIndRqd 0 "FALSE" 1 "TRUE" ;
VAL_ 1234 DTCI_ARS_CnfrmdDTC 0 "FALSE" 1 "TRUE" ;
VAL_ 1234 DTCI_ARS_DTCFaultType 0 "Not Supported" 1 "Type A" 2 "Type B" 3 "Type C" ;
VAL_ 1234 DTCI_ARS_TstNCmpltdOpCyc 0 "FALSE" 1 "TRUE" ;
VAL_ 1234 DTCI_ARS_TstNCmpltdLstClr 0 "FALSE" 1 "TRUE" ;
VAL_ 1234 DTCI_ARS_TstFldOpCyc 0 "FALSE" 1 "TRUE" ;
VAL_ 1234 DTCI_ARS_TstFldLstClr 0 "FALSE" 1 "TRUE" ;
VAL_ 1234 DTCI_ARS_TstFld 0 "FALSE" 1 "TRUE" ;
VAL_ 1234 DTCI_ARS_PndngDTC 0 "FALSE" 1 "TRUE" ;
VAL_ 1234 DTCI_ARS_DTCTriggered 0 "FALSE" 1 "TRUE" ;
VAL_ 1234 DTCI_ARS_WrnIndTrggrd 0 "FALSE" 1 "TRUE" ;
VAL_ 1234 DTCI_ARS_WrnIndRqd 0 "FALSE" 1 "TRUE" ;
VAL_ 1832 DTCI_BCM_CnfrmdDTC 0 "FALSE" 1 "TRUE" ;
VAL_ 1832 DTCI_BCM_DTCFaultType 0 "Not Supported" 1 "Type A" 2 "Type B" 3 "Type C" ;
VAL_ 1832 DTCI_BCM_TstNCmpltdOpCyc 0 "FALSE" 1 "TRUE" ;
VAL_ 1832 DTCI_BCM_TstNCmpltdLstClr 0 "FALSE" 1 "TRUE" ;
VAL_ 1832 DTCI_BCM_TstFldOpCyc 0 "FALSE" 1 "TRUE" ;
VAL_ 1832 DTCI_BCM_TstFldLstClr 0 "FALSE" 1 "TRUE" ;
VAL_ 1832 DTCI_BCM_TstFld 0 "FALSE" 1 "TRUE" ;
VAL_ 1832 DTCI_BCM_PndngDTC 0 "FALSE" 1 "TRUE" ;
VAL_ 1832 DTCI_BCM_DTCTriggered 0 "FALSE" 1 "TRUE" ;
VAL_ 1832 DTCI_BCM_WrnIndTrggrd 0 "FALSE" 1 "TRUE" ;
VAL_ 1832 DTCI_BCM_WrnIndRqd 0 "FALSE" 1 "TRUE" ;
VAL_ 1950 DTCI_BSM_HEV_CnfrmdDTC 0 "FALSE" 1 "TRUE" ;
VAL_ 1950 DTCI_BSM_HEV_DTCFaultType 0 "Not Supported" 1 "Type A" 2 "Type B" 3 "Type C" ;
VAL_ 1950 DTCI_BSM_HEV_TstNCmpltdOpCyc 0 "FALSE" 1 "TRUE" ;
VAL_ 1950 DTCI_BSM_HEV_TstNCmpltdLstClr 0 "FALSE" 1 "TRUE" ;
VAL_ 1950 DTCI_BSM_HEV_TstFldOpCyc 0 "FALSE" 1 "TRUE" ;
VAL_ 1950 DTCI_BSM_HEV_TstFldLstClr 0 "FALSE" 1 "TRUE" ;
VAL_ 1950 DTCI_BSM_HEV_TstFld 0 "FALSE" 1 "TRUE" ;
VAL_ 1950 DTCI_BSM_HEV_PndngDTC 0 "FALSE" 1 "TRUE" ;
VAL_ 1950 DTCI_BSM_HEV_DTCTriggered 0 "FALSE" 1 "TRUE" ;
VAL_ 1950 DTCI_BSM_HEV_WrnIndTrggrd 0 "FALSE" 1 "TRUE" ;
VAL_ 1950 DTCI_BSM_HEV_WrnIndRqd 0 "FALSE" 1 "TRUE" ;
VAL_ 1233 DTCI_BSM_MH_CnfrmdDTC 0 "FALSE" 1 "TRUE" ;
VAL_ 1233 DTCI_BSM_MH_DTCFaultType 0 "Not Supported" 1 "Type A" 2 "Type B" 3 "Type C" ;
VAL_ 1233 DTCI_BSM_MH_TstNCmpltdOpCyc 0 "FALSE" 1 "TRUE" ;
VAL_ 1233 DTCI_BSM_MH_TstNCmpltdLstClr 0 "FALSE" 1 "TRUE" ;
VAL_ 1233 DTCI_BSM_MH_TstFldOpCyc 0 "FALSE" 1 "TRUE" ;
VAL_ 1233 DTCI_BSM_MH_TstFldLstClr 0 "FALSE" 1 "TRUE" ;
VAL_ 1233 DTCI_BSM_MH_TstFld 0 "FALSE" 1 "TRUE" ;
VAL_ 1233 DTCI_BSM_MH_PndngDTC 0 "FALSE" 1 "TRUE" ;
VAL_ 1233 DTCI_BSM_MH_DTCTriggered 0 "FALSE" 1 "TRUE" ;
VAL_ 1233 DTCI_BSM_MH_WrnIndTrggrd 0 "FALSE" 1 "TRUE" ;
VAL_ 1233 DTCI_BSM_MH_WrnIndRqd 0 "FALSE" 1 "TRUE" ;
VAL_ 1833 DTCI_BSM_CnfrmdDTC 0 "FALSE" 1 "TRUE" ;
VAL_ 1833 DTCI_BSM_DTCFaultType 0 "Not Supported" 1 "Type A" 2 "Type B" 3 "Type C" ;
VAL_ 1833 DTCI_BSM_TstNCmpltdOpCyc 0 "FALSE" 1 "TRUE" ;
VAL_ 1833 DTCI_BSM_TstNCmpltdLstClr 0 "FALSE" 1 "TRUE" ;
VAL_ 1833 DTCI_BSM_TstFldOpCyc 0 "FALSE" 1 "TRUE" ;
VAL_ 1833 DTCI_BSM_TstFldLstClr 0 "FALSE" 1 "TRUE" ;
VAL_ 1833 DTCI_BSM_TstFld 0 "FALSE" 1 "TRUE" ;
VAL_ 1833 DTCI_BSM_PndngDTC 0 "FALSE" 1 "TRUE" ;
VAL_ 1833 DTCI_BSM_DTCTriggered 0 "FALSE" 1 "TRUE" ;
VAL_ 1833 DTCI_BSM_WrnIndTrggrd 0 "FALSE" 1 "TRUE" ;
VAL_ 1833 DTCI_BSM_WrnIndRqd 0 "FALSE" 1 "TRUE" ;
VAL_ 1232 DTCI_CGM_CnfrmdDTC 0 "FALSE" 1 "TRUE" ;
VAL_ 1232 DTCI_CGM_DTCFaultType 0 "Not Supported" 1 "Type A" 2 "Type B" 3 "Type C" ;
VAL_ 1232 DTCI_CGM_TstNCmpltdOpCyc 0 "FALSE" 1 "TRUE" ;
VAL_ 1232 DTCI_CGM_TstNCmpltdLstClr 0 "FALSE" 1 "TRUE" ;
VAL_ 1232 DTCI_CGM_TstFldOpCyc 0 "FALSE" 1 "TRUE" ;
VAL_ 1232 DTCI_CGM_TstFldLstClr 0 "FALSE" 1 "TRUE" ;
VAL_ 1232 DTCI_CGM_TstFld 0 "FALSE" 1 "TRUE" ;
VAL_ 1232 DTCI_CGM_PndngDTC 0 "FALSE" 1 "TRUE" ;
VAL_ 1232 DTCI_CGM_DTCTriggered 0 "FALSE" 1 "TRUE" ;
VAL_ 1232 DTCI_CGM_WrnIndTrggrd 0 "FALSE" 1 "TRUE" ;
VAL_ 1232 DTCI_CGM_WrnIndRqd 0 "FALSE" 1 "TRUE" ;
VAL_ 1914 DTCI_CSM_AV_CnfrmdDTC 0 "FALSE" 1 "TRUE" ;
VAL_ 1914 DTCI_CSM_AV_DTCFaultType 0 "Not Supported" 1 "Type A" 2 "Type B" 3 "Type C" ;
VAL_ 1914 DTCI_CSM_AV_TstNCmpltdOpCyc 0 "FALSE" 1 "TRUE" ;
VAL_ 1914 DTCI_CSM_AV_TstNCmpltdLstClr 0 "FALSE" 1 "TRUE" ;
VAL_ 1914 DTCI_CSM_AV_TstFldOpCyc 0 "FALSE" 1 "TRUE" ;
VAL_ 1914 DTCI_CSM_AV_TstFldLstClr 0 "FALSE" 1 "TRUE" ;
VAL_ 1914 DTCI_CSM_AV_TstFld 0 "FALSE" 1 "TRUE" ;
VAL_ 1914 DTCI_CSM_AV_PndngDTC 0 "FALSE" 1 "TRUE" ;
VAL_ 1914 DTCI_CSM_AV_DTCTriggered 0 "FALSE" 1 "TRUE" ;
VAL_ 1914 DTCI_CSM_AV_WrnIndTrggrd 0 "FALSE" 1 "TRUE" ;
VAL_ 1914 DTCI_CSM_AV_WrnIndRqd 0 "FALSE" 1 "TRUE" ;
VAL_ 1835 DTCI_CSM_CnfrmdDTC 0 "FALSE" 1 "TRUE" ;
VAL_ 1835 DTCI_CSM_DTCFaultType 0 "Not Supported" 1 "Type A" 2 "Type B" 3 "Type C" ;
VAL_ 1835 DTCI_CSM_TstNCmpltdOpCyc 0 "FALSE" 1 "TRUE" ;
VAL_ 1835 DTCI_CSM_TstNCmpltdLstClr 0 "FALSE" 1 "TRUE" ;
VAL_ 1835 DTCI_CSM_TstFldOpCyc 0 "FALSE" 1 "TRUE" ;
VAL_ 1835 DTCI_CSM_TstFldLstClr 0 "FALSE" 1 "TRUE" ;
VAL_ 1835 DTCI_CSM_TstFld 0 "FALSE" 1 "TRUE" ;
VAL_ 1835 DTCI_CSM_PndngDTC 0 "FALSE" 1 "TRUE" ;
VAL_ 1835 DTCI_CSM_DTCTriggered 0 "FALSE" 1 "TRUE" ;
VAL_ 1835 DTCI_CSM_WrnIndTrggrd 0 "FALSE" 1 "TRUE" ;
VAL_ 1835 DTCI_CSM_WrnIndRqd 0 "FALSE" 1 "TRUE" ;
VAL_ 1230 DTCI_DCM_CnfrmdDTC 0 "FALSE" 1 "TRUE" ;
VAL_ 1230 DTCI_DCM_DTCFaultType 0 "Not Supported" 1 "Type A" 2 "Type B" 3 "Type C" ;
VAL_ 1230 DTCI_DCM_TstNCmpltdOpCyc 0 "FALSE" 1 "TRUE" ;
VAL_ 1230 DTCI_DCM_TstNCmpltdLstClr 0 "FALSE" 1 "TRUE" ;
VAL_ 1230 DTCI_DCM_TstFldOpCyc 0 "FALSE" 1 "TRUE" ;
VAL_ 1230 DTCI_DCM_TstFldLstClr 0 "FALSE" 1 "TRUE" ;
VAL_ 1230 DTCI_DCM_TstFld 0 "FALSE" 1 "TRUE" ;
VAL_ 1230 DTCI_DCM_PndngDTC 0 "FALSE" 1 "TRUE" ;
VAL_ 1230 DTCI_DCM_DTCTriggered 0 "FALSE" 1 "TRUE" ;
VAL_ 1230 DTCI_DCM_WrnIndTrggrd 0 "FALSE" 1 "TRUE" ;
VAL_ 1230 DTCI_DCM_WrnIndRqd 0 "FALSE" 1 "TRUE" ;
VAL_ 1836 DTCI_DMS_CnfrmdDTC 0 "FALSE" 1 "TRUE" ;
VAL_ 1836 DTCI_DMS_DTCFaultType 0 "Not Supported" 1 "Type A" 2 "Type B" 3 "Type C" ;
VAL_ 1836 DTCI_DMS_TstNCmpltdOpCyc 0 "FALSE" 1 "TRUE" ;
VAL_ 1836 DTCI_DMS_TstNCmpltdLstClr 0 "FALSE" 1 "TRUE" ;
VAL_ 1836 DTCI_DMS_TstFldOpCyc 0 "FALSE" 1 "TRUE" ;
VAL_ 1836 DTCI_DMS_TstFldLstClr 0 "FALSE" 1 "TRUE" ;
VAL_ 1836 DTCI_DMS_TstFld 0 "FALSE" 1 "TRUE" ;
VAL_ 1836 DTCI_DMS_PndngDTC 0 "FALSE" 1 "TRUE" ;
VAL_ 1836 DTCI_DMS_DTCTriggered 0 "FALSE" 1 "TRUE" ;
VAL_ 1836 DTCI_DMS_WrnIndTrggrd 0 "FALSE" 1 "TRUE" ;
VAL_ 1836 DTCI_DMS_WrnIndRqd 0 "FALSE" 1 "TRUE" ;
VAL_ 1228 DTCI_EBCM_CnfrmdDTC 0 "FALSE" 1 "TRUE" ;
VAL_ 1228 DTCI_EBCM_DTCFaultType 0 "Not Supported" 1 "Type A" 2 "Type B" 3 "Type C" ;
VAL_ 1228 DTCI_EBCM_TstNCmpltdOpCyc 0 "FALSE" 1 "TRUE" ;
VAL_ 1228 DTCI_EBCM_TstNCmpltdLstClr 0 "FALSE" 1 "TRUE" ;
VAL_ 1228 DTCI_EBCM_TstFldOpCyc 0 "FALSE" 1 "TRUE" ;
VAL_ 1228 DTCI_EBCM_TstFldLstClr 0 "FALSE" 1 "TRUE" ;
VAL_ 1228 DTCI_EBCM_TstFld 0 "FALSE" 1 "TRUE" ;
VAL_ 1228 DTCI_EBCM_PndngDTC 0 "FALSE" 1 "TRUE" ;
VAL_ 1228 DTCI_EBCM_DTCTriggered 0 "FALSE" 1 "TRUE" ;
VAL_ 1228 DTCI_EBCM_WrnIndTrggrd 0 "FALSE" 1 "TRUE" ;
VAL_ 1228 DTCI_EBCM_WrnIndRqd 0 "FALSE" 1 "TRUE" ;
VAL_ 1838 DTCI_ECM_CnfrmdDTC 0 "FALSE" 1 "TRUE" ;
VAL_ 1838 DTCI_ECM_DTCFaultType 0 "Not Supported" 1 "Type A" 2 "Type B" 3 "Type C" ;
VAL_ 1838 DTCI_ECM_TstNCmpltdOpCyc 0 "FALSE" 1 "TRUE" ;
VAL_ 1838 DTCI_ECM_TstNCmpltdLstClr 0 "FALSE" 1 "TRUE" ;
VAL_ 1838 DTCI_ECM_TstFldOpCyc 0 "FALSE" 1 "TRUE" ;
VAL_ 1838 DTCI_ECM_TstFldLstClr 0 "FALSE" 1 "TRUE" ;
VAL_ 1838 DTCI_ECM_TstFld 0 "FALSE" 1 "TRUE" ;
VAL_ 1838 DTCI_ECM_PndngDTC 0 "FALSE" 1 "TRUE" ;
VAL_ 1838 DTCI_ECM_DTCTriggered 0 "FALSE" 1 "TRUE" ;
VAL_ 1838 DTCI_ECM_WrnIndTrggrd 0 "FALSE" 1 "TRUE" ;
VAL_ 1838 DTCI_ECM_WrnIndRqd 0 "FALSE" 1 "TRUE" ;
VAL_ 1839 DTCI_ECP_E_CnfrmdDTC 0 "FALSE" 1 "TRUE" ;
VAL_ 1839 DTCI_ECP_E_DTCFaultType 0 "Not Supported" 1 "Type A" 2 "Type B" 3 "Type C" ;
VAL_ 1839 DTCI_ECP_E_TstNCmpltdOpCyc 0 "FALSE" 1 "TRUE" ;
VAL_ 1839 DTCI_ECP_E_TstNCmpltdLstClr 0 "FALSE" 1 "TRUE" ;
VAL_ 1839 DTCI_ECP_E_TstFldOpCyc 0 "FALSE" 1 "TRUE" ;
VAL_ 1839 DTCI_ECP_E_TstFldLstClr 0 "FALSE" 1 "TRUE" ;
VAL_ 1839 DTCI_ECP_E_TstFld 0 "FALSE" 1 "TRUE" ;
VAL_ 1839 DTCI_ECP_E_PndngDTC 0 "FALSE" 1 "TRUE" ;
VAL_ 1839 DTCI_ECP_E_DTCTriggered 0 "FALSE" 1 "TRUE" ;
VAL_ 1839 DTCI_ECP_E_WrnIndTrggrd 0 "FALSE" 1 "TRUE" ;
VAL_ 1839 DTCI_ECP_E_WrnIndRqd 0 "FALSE" 1 "TRUE" ;
VAL_ 1116 DTCI_ECP_H1_CnfrmdDTC 0 "FALSE" 1 "TRUE" ;
VAL_ 1116 DTCI_ECP_H1_DTCFaultType 0 "Not Supported" 1 "Type A" 2 "Type B" 3 "Type C" ;
VAL_ 1116 DTCI_ECP_H1_TstNCmpltdOpCyc 0 "FALSE" 1 "TRUE" ;
VAL_ 1116 DTCI_ECP_H1_TstNCmpltdLstClr 0 "FALSE" 1 "TRUE" ;
VAL_ 1116 DTCI_ECP_H1_TstFldOpCyc 0 "FALSE" 1 "TRUE" ;
VAL_ 1116 DTCI_ECP_H1_TstFldLstClr 0 "FALSE" 1 "TRUE" ;
VAL_ 1116 DTCI_ECP_H1_TstFld 0 "FALSE" 1 "TRUE" ;
VAL_ 1116 DTCI_ECP_H1_PndngDTC 0 "FALSE" 1 "TRUE" ;
VAL_ 1116 DTCI_ECP_H1_DTCTriggered 0 "FALSE" 1 "TRUE" ;
VAL_ 1116 DTCI_ECP_H1_WrnIndTrggrd 0 "FALSE" 1 "TRUE" ;
VAL_ 1116 DTCI_ECP_H1_WrnIndRqd 0 "FALSE" 1 "TRUE" ;
VAL_ 1951 DTCI_ECP_H2_CnfrmdDTC 0 "FALSE" 1 "TRUE" ;
VAL_ 1951 DTCI_ECP_H2_DTCFaultType 0 "Not Supported" 1 "Type A" 2 "Type B" 3 "Type C" ;
VAL_ 1951 DTCI_ECP_H2_TstNCmpltdOpCyc 0 "FALSE" 1 "TRUE" ;
VAL_ 1951 DTCI_ECP_H2_TstNCmpltdLstClr 0 "FALSE" 1 "TRUE" ;
VAL_ 1951 DTCI_ECP_H2_TstFldOpCyc 0 "FALSE" 1 "TRUE" ;
VAL_ 1951 DTCI_ECP_H2_TstFldLstClr 0 "FALSE" 1 "TRUE" ;
VAL_ 1951 DTCI_ECP_H2_TstFld 0 "FALSE" 1 "TRUE" ;
VAL_ 1951 DTCI_ECP_H2_PndngDTC 0 "FALSE" 1 "TRUE" ;
VAL_ 1951 DTCI_ECP_H2_DTCTriggered 0 "FALSE" 1 "TRUE" ;
VAL_ 1951 DTCI_ECP_H2_WrnIndTrggrd 0 "FALSE" 1 "TRUE" ;
VAL_ 1951 DTCI_ECP_H2_WrnIndRqd 0 "FALSE" 1 "TRUE" ;
VAL_ 1115 DTCI_ECP_H3_CnfrmdDTC 0 "FALSE" 1 "TRUE" ;
VAL_ 1115 DTCI_ECP_H3_DTCFaultType 0 "Not Supported" 1 "Type A" 2 "Type B" 3 "Type C" ;
VAL_ 1115 DTCI_ECP_H3_TstNCmpltdOpCyc 0 "FALSE" 1 "TRUE" ;
VAL_ 1115 DTCI_ECP_H3_TstNCmpltdLstClr 0 "FALSE" 1 "TRUE" ;
VAL_ 1115 DTCI_ECP_H3_TstFldOpCyc 0 "FALSE" 1 "TRUE" ;
VAL_ 1115 DTCI_ECP_H3_TstFldLstClr 0 "FALSE" 1 "TRUE" ;
VAL_ 1115 DTCI_ECP_H3_TstFld 0 "FALSE" 1 "TRUE" ;
VAL_ 1115 DTCI_ECP_H3_PndngDTC 0 "FALSE" 1 "TRUE" ;
VAL_ 1115 DTCI_ECP_H3_DTCTriggered 0 "FALSE" 1 "TRUE" ;
VAL_ 1115 DTCI_ECP_H3_WrnIndTrggrd 0 "FALSE" 1 "TRUE" ;
VAL_ 1115 DTCI_ECP_H3_WrnIndRqd 0 "FALSE" 1 "TRUE" ;
VAL_ 1226 DTCI_ECP_MC_CnfrmdDTC 0 "FALSE" 1 "TRUE" ;
VAL_ 1226 DTCI_ECP_MC_DTCFaultType 0 "Not Supported" 1 "Type A" 2 "Type B" 3 "Type C" ;
VAL_ 1226 DTCI_ECP_MC_TstNCmpltdOpCyc 0 "FALSE" 1 "TRUE" ;
VAL_ 1226 DTCI_ECP_MC_TstNCmpltdLstClr 0 "FALSE" 1 "TRUE" ;
VAL_ 1226 DTCI_ECP_MC_TstFldOpCyc 0 "FALSE" 1 "TRUE" ;
VAL_ 1226 DTCI_ECP_MC_TstFldLstClr 0 "FALSE" 1 "TRUE" ;
VAL_ 1226 DTCI_ECP_MC_TstFld 0 "FALSE" 1 "TRUE" ;
VAL_ 1226 DTCI_ECP_MC_PndngDTC 0 "FALSE" 1 "TRUE" ;
VAL_ 1226 DTCI_ECP_MC_DTCTriggered 0 "FALSE" 1 "TRUE" ;
VAL_ 1226 DTCI_ECP_MC_WrnIndTrggrd 0 "FALSE" 1 "TRUE" ;
VAL_ 1226 DTCI_ECP_MC_WrnIndRqd 0 "FALSE" 1 "TRUE" ;
VAL_ 1227 DTCI_ECP_S2_CnfrmdDTC 0 "FALSE" 1 "TRUE" ;
VAL_ 1227 DTCI_ECP_S2_DTCFaultType 0 "Not Supported" 1 "Type A" 2 "Type B" 3 "Type C" ;
VAL_ 1227 DTCI_ECP_S2_TstNCmpltdOpCyc 0 "FALSE" 1 "TRUE" ;
VAL_ 1227 DTCI_ECP_S2_TstNCmpltdLstClr 0 "FALSE" 1 "TRUE" ;
VAL_ 1227 DTCI_ECP_S2_TstFldOpCyc 0 "FALSE" 1 "TRUE" ;
VAL_ 1227 DTCI_ECP_S2_TstFldLstClr 0 "FALSE" 1 "TRUE" ;
VAL_ 1227 DTCI_ECP_S2_TstFld 0 "FALSE" 1 "TRUE" ;
VAL_ 1227 DTCI_ECP_S2_PndngDTC 0 "FALSE" 1 "TRUE" ;
VAL_ 1227 DTCI_ECP_S2_DTCTriggered 0 "FALSE" 1 "TRUE" ;
VAL_ 1227 DTCI_ECP_S2_WrnIndTrggrd 0 "FALSE" 1 "TRUE" ;
VAL_ 1227 DTCI_ECP_S2_WrnIndRqd 0 "FALSE" 1 "TRUE" ;
VAL_ 1840 DTCI_ECP_S_CnfrmdDTC 0 "FALSE" 1 "TRUE" ;
VAL_ 1840 DTCI_ECP_S_DTCFaultType 0 "Not Supported" 1 "Type A" 2 "Type B" 3 "Type C" ;
VAL_ 1840 DTCI_ECP_S_TstNCmpltdOpCyc 0 "FALSE" 1 "TRUE" ;
VAL_ 1840 DTCI_ECP_S_TstNCmpltdLstClr 0 "FALSE" 1 "TRUE" ;
VAL_ 1840 DTCI_ECP_S_TstFldOpCyc 0 "FALSE" 1 "TRUE" ;
VAL_ 1840 DTCI_ECP_S_TstFldLstClr 0 "FALSE" 1 "TRUE" ;
VAL_ 1840 DTCI_ECP_S_TstFld 0 "FALSE" 1 "TRUE" ;
VAL_ 1840 DTCI_ECP_S_PndngDTC 0 "FALSE" 1 "TRUE" ;
VAL_ 1840 DTCI_ECP_S_DTCTriggered 0 "FALSE" 1 "TRUE" ;
VAL_ 1840 DTCI_ECP_S_WrnIndTrggrd 0 "FALSE" 1 "TRUE" ;
VAL_ 1840 DTCI_ECP_S_WrnIndRqd 0 "FALSE" 1 "TRUE" ;
VAL_ 1225 DTCI_ECP_X1_CnfrmdDTC 0 "FALSE" 1 "TRUE" ;
VAL_ 1225 DTCI_ECP_X1_DTCFaultType 0 "Not Supported" 1 "Type A" 2 "Type B" 3 "Type C" ;
VAL_ 1225 DTCI_ECP_X1_TstNCmpltdOpCyc 0 "FALSE" 1 "TRUE" ;
VAL_ 1225 DTCI_ECP_X1_TstNCmpltdLstClr 0 "FALSE" 1 "TRUE" ;
VAL_ 1225 DTCI_ECP_X1_TstFldOpCyc 0 "FALSE" 1 "TRUE" ;
VAL_ 1225 DTCI_ECP_X1_TstFldLstClr 0 "FALSE" 1 "TRUE" ;
VAL_ 1225 DTCI_ECP_X1_TstFld 0 "FALSE" 1 "TRUE" ;
VAL_ 1225 DTCI_ECP_X1_PndngDTC 0 "FALSE" 1 "TRUE" ;
VAL_ 1225 DTCI_ECP_X1_DTCTriggered 0 "FALSE" 1 "TRUE" ;
VAL_ 1225 DTCI_ECP_X1_WrnIndTrggrd 0 "FALSE" 1 "TRUE" ;
VAL_ 1225 DTCI_ECP_X1_WrnIndRqd 0 "FALSE" 1 "TRUE" ;
VAL_ 1841 DTCI_ELM_CnfrmdDTC 0 "FALSE" 1 "TRUE" ;
VAL_ 1841 DTCI_ELM_DTCFaultType 0 "Not Supported" 1 "Type A" 2 "Type B" 3 "Type C" ;
VAL_ 1841 DTCI_ELM_TstNCmpltdOpCyc 0 "FALSE" 1 "TRUE" ;
VAL_ 1841 DTCI_ELM_TstNCmpltdLstClr 0 "FALSE" 1 "TRUE" ;
VAL_ 1841 DTCI_ELM_TstFldOpCyc 0 "FALSE" 1 "TRUE" ;
VAL_ 1841 DTCI_ELM_TstFldLstClr 0 "FALSE" 1 "TRUE" ;
VAL_ 1841 DTCI_ELM_TstFld 0 "FALSE" 1 "TRUE" ;
VAL_ 1841 DTCI_ELM_PndngDTC 0 "FALSE" 1 "TRUE" ;
VAL_ 1841 DTCI_ELM_DTCTriggered 0 "FALSE" 1 "TRUE" ;
VAL_ 1841 DTCI_ELM_WrnIndTrggrd 0 "FALSE" 1 "TRUE" ;
VAL_ 1841 DTCI_ELM_WrnIndRqd 0 "FALSE" 1 "TRUE" ;
VAL_ 1224 DTCI_EOCM_HCP1_CnfrmdDTC 0 "FALSE" 1 "TRUE" ;
VAL_ 1224 DTCI_EOCM_HCP1_DTCFaultType 0 "Not Supported" 1 "Type A" 2 "Type B" 3 "Type C" ;
VAL_ 1224 DTCI_EOCM_HCP1_TstNCmpltdOpCyc 0 "FALSE" 1 "TRUE" ;
VAL_ 1224 DTCI_EOCM_HCP1_TstNCmpltdLstClr 0 "FALSE" 1 "TRUE" ;
VAL_ 1224 DTCI_EOCM_HCP1_TstFldOpCyc 0 "FALSE" 1 "TRUE" ;
VAL_ 1224 DTCI_EOCM_HCP1_TstFldLstClr 0 "FALSE" 1 "TRUE" ;
VAL_ 1224 DTCI_EOCM_HCP1_TstFld 0 "FALSE" 1 "TRUE" ;
VAL_ 1224 DTCI_EOCM_HCP1_PndngDTC 0 "FALSE" 1 "TRUE" ;
VAL_ 1224 DTCI_EOCM_HCP1_DTCTriggered 0 "FALSE" 1 "TRUE" ;
VAL_ 1224 DTCI_EOCM_HCP1_WrnIndTrggrd 0 "FALSE" 1 "TRUE" ;
VAL_ 1224 DTCI_EOCM_HCP1_WrnIndRqd 0 "FALSE" 1 "TRUE" ;
VAL_ 1842 DTCI_EOCM_HCP2_CnfrmdDTC 0 "FALSE" 1 "TRUE" ;
VAL_ 1842 DTCI_EOCM_HCP2_DTCFaultType 0 "Not Supported" 1 "Type A" 2 "Type B" 3 "Type C" ;
VAL_ 1842 DTCI_EOCM_HCP2_TstNCmpltdOpCyc 0 "FALSE" 1 "TRUE" ;
VAL_ 1842 DTCI_EOCM_HCP2_TstNCmpltdLstClr 0 "FALSE" 1 "TRUE" ;
VAL_ 1842 DTCI_EOCM_HCP2_TstFldOpCyc 0 "FALSE" 1 "TRUE" ;
VAL_ 1842 DTCI_EOCM_HCP2_TstFldLstClr 0 "FALSE" 1 "TRUE" ;
VAL_ 1842 DTCI_EOCM_HCP2_TstFld 0 "FALSE" 1 "TRUE" ;
VAL_ 1842 DTCI_EOCM_HCP2_PndngDTC 0 "FALSE" 1 "TRUE" ;
VAL_ 1842 DTCI_EOCM_HCP2_DTCTriggered 0 "FALSE" 1 "TRUE" ;
VAL_ 1842 DTCI_EOCM_HCP2_WrnIndTrggrd 0 "FALSE" 1 "TRUE" ;
VAL_ 1842 DTCI_EOCM_HCP2_WrnIndRqd 0 "FALSE" 1 "TRUE" ;
VAL_ 1223 DTCI_EOCM_CnfrmdDTC 0 "FALSE" 1 "TRUE" ;
VAL_ 1223 DTCI_EOCM_DTCFaultType 0 "Not Supported" 1 "Type A" 2 "Type B" 3 "Type C" ;
VAL_ 1223 DTCI_EOCM_TstNCmpltdOpCyc 0 "FALSE" 1 "TRUE" ;
VAL_ 1223 DTCI_EOCM_TstNCmpltdLstClr 0 "FALSE" 1 "TRUE" ;
VAL_ 1223 DTCI_EOCM_TstFldOpCyc 0 "FALSE" 1 "TRUE" ;
VAL_ 1223 DTCI_EOCM_TstFldLstClr 0 "FALSE" 1 "TRUE" ;
VAL_ 1223 DTCI_EOCM_TstFld 0 "FALSE" 1 "TRUE" ;
VAL_ 1223 DTCI_EOCM_PndngDTC 0 "FALSE" 1 "TRUE" ;
VAL_ 1223 DTCI_EOCM_DTCTriggered 0 "FALSE" 1 "TRUE" ;
VAL_ 1223 DTCI_EOCM_WrnIndTrggrd 0 "FALSE" 1 "TRUE" ;
VAL_ 1223 DTCI_EOCM_WrnIndRqd 0 "FALSE" 1 "TRUE" ;
VAL_ 1895 DTCI_EPS_1_CnfrmdDTC 0 "FALSE" 1 "TRUE" ;
VAL_ 1895 DTCI_EPS_1_DTCFaultType 0 "Not Supported" 1 "Type A" 2 "Type B" 3 "Type C" ;
VAL_ 1895 DTCI_EPS_1_TstNCmpltdOpCyc 0 "FALSE" 1 "TRUE" ;
VAL_ 1895 DTCI_EPS_1_TstNCmpltdLstClr 0 "FALSE" 1 "TRUE" ;
VAL_ 1895 DTCI_EPS_1_TstFldOpCyc 0 "FALSE" 1 "TRUE" ;
VAL_ 1895 DTCI_EPS_1_TstFldLstClr 0 "FALSE" 1 "TRUE" ;
VAL_ 1895 DTCI_EPS_1_TstFld 0 "FALSE" 1 "TRUE" ;
VAL_ 1895 DTCI_EPS_1_PndngDTC 0 "FALSE" 1 "TRUE" ;
VAL_ 1895 DTCI_EPS_1_DTCTriggered 0 "FALSE" 1 "TRUE" ;
VAL_ 1895 DTCI_EPS_1_WrnIndTrggrd 0 "FALSE" 1 "TRUE" ;
VAL_ 1895 DTCI_EPS_1_WrnIndRqd 0 "FALSE" 1 "TRUE" ;
VAL_ 1843 DTCI_EPS_CnfrmdDTC 0 "FALSE" 1 "TRUE" ;
VAL_ 1843 DTCI_EPS_DTCFaultType 0 "Not Supported" 1 "Type A" 2 "Type B" 3 "Type C" ;
VAL_ 1843 DTCI_EPS_TstNCmpltdOpCyc 0 "FALSE" 1 "TRUE" ;
VAL_ 1843 DTCI_EPS_TstNCmpltdLstClr 0 "FALSE" 1 "TRUE" ;
VAL_ 1843 DTCI_EPS_TstFldOpCyc 0 "FALSE" 1 "TRUE" ;
VAL_ 1843 DTCI_EPS_TstFldLstClr 0 "FALSE" 1 "TRUE" ;
VAL_ 1843 DTCI_EPS_TstFld 0 "FALSE" 1 "TRUE" ;
VAL_ 1843 DTCI_EPS_PndngDTC 0 "FALSE" 1 "TRUE" ;
VAL_ 1843 DTCI_EPS_DTCTriggered 0 "FALSE" 1 "TRUE" ;
VAL_ 1843 DTCI_EPS_WrnIndTrggrd 0 "FALSE" 1 "TRUE" ;
VAL_ 1843 DTCI_EPS_WrnIndRqd 0 "FALSE" 1 "TRUE" ;
VAL_ 1222 DTCI_EPSb_CnfrmdDTC 0 "FALSE" 1 "TRUE" ;
VAL_ 1222 DTCI_EPSb_DTCFaultType 0 "Not Supported" 1 "Type A" 2 "Type B" 3 "Type C" ;
VAL_ 1222 DTCI_EPSb_TstNCmpltdOpCyc 0 "FALSE" 1 "TRUE" ;
VAL_ 1222 DTCI_EPSb_TstNCmpltdLstClr 0 "FALSE" 1 "TRUE" ;
VAL_ 1222 DTCI_EPSb_TstFldOpCyc 0 "FALSE" 1 "TRUE" ;
VAL_ 1222 DTCI_EPSb_TstFldLstClr 0 "FALSE" 1 "TRUE" ;
VAL_ 1222 DTCI_EPSb_TstFld 0 "FALSE" 1 "TRUE" ;
VAL_ 1222 DTCI_EPSb_PndngDTC 0 "FALSE" 1 "TRUE" ;
VAL_ 1222 DTCI_EPSb_DTCTriggered 0 "FALSE" 1 "TRUE" ;
VAL_ 1222 DTCI_EPSb_WrnIndTrggrd 0 "FALSE" 1 "TRUE" ;
VAL_ 1222 DTCI_EPSb_WrnIndRqd 0 "FALSE" 1 "TRUE" ;
VAL_ 1844 DTCI_FCM_LC_CnfrmdDTC 0 "FALSE" 1 "TRUE" ;
VAL_ 1844 DTCI_FCM_LC_DTCFaultType 0 "Not Supported" 1 "Type A" 2 "Type B" 3 "Type C" ;
VAL_ 1844 DTCI_FCM_LC_TstNCmpltdOpCyc 0 "FALSE" 1 "TRUE" ;
VAL_ 1844 DTCI_FCM_LC_TstNCmpltdLstClr 0 "FALSE" 1 "TRUE" ;
VAL_ 1844 DTCI_FCM_LC_TstFldOpCyc 0 "FALSE" 1 "TRUE" ;
VAL_ 1844 DTCI_FCM_LC_TstFldLstClr 0 "FALSE" 1 "TRUE" ;
VAL_ 1844 DTCI_FCM_LC_TstFld 0 "FALSE" 1 "TRUE" ;
VAL_ 1844 DTCI_FCM_LC_PndngDTC 0 "FALSE" 1 "TRUE" ;
VAL_ 1844 DTCI_FCM_LC_DTCTriggered 0 "FALSE" 1 "TRUE" ;
VAL_ 1844 DTCI_FCM_LC_WrnIndTrggrd 0 "FALSE" 1 "TRUE" ;
VAL_ 1844 DTCI_FCM_LC_WrnIndRqd 0 "FALSE" 1 "TRUE" ;
VAL_ 1221 DTCI_FCM_CnfrmdDTC 0 "FALSE" 1 "TRUE" ;
VAL_ 1221 DTCI_FCM_DTCFaultType 0 "Not Supported" 1 "Type A" 2 "Type B" 3 "Type C" ;
VAL_ 1221 DTCI_FCM_TstNCmpltdOpCyc 0 "FALSE" 1 "TRUE" ;
VAL_ 1221 DTCI_FCM_TstNCmpltdLstClr 0 "FALSE" 1 "TRUE" ;
VAL_ 1221 DTCI_FCM_TstFldOpCyc 0 "FALSE" 1 "TRUE" ;
VAL_ 1221 DTCI_FCM_TstFldLstClr 0 "FALSE" 1 "TRUE" ;
VAL_ 1221 DTCI_FCM_TstFld 0 "FALSE" 1 "TRUE" ;
VAL_ 1221 DTCI_FCM_PndngDTC 0 "FALSE" 1 "TRUE" ;
VAL_ 1221 DTCI_FCM_DTCTriggered 0 "FALSE" 1 "TRUE" ;
VAL_ 1221 DTCI_FCM_WrnIndTrggrd 0 "FALSE" 1 "TRUE" ;
VAL_ 1221 DTCI_FCM_WrnIndRqd 0 "FALSE" 1 "TRUE" ;
VAL_ 1845 DTCI_FOPM_CnfrmdDTC 0 "FALSE" 1 "TRUE" ;
VAL_ 1845 DTCI_FOPM_DTCFaultType 0 "Not Supported" 1 "Type A" 2 "Type B" 3 "Type C" ;
VAL_ 1845 DTCI_FOPM_TstNCmpltdOpCyc 0 "FALSE" 1 "TRUE" ;
VAL_ 1845 DTCI_FOPM_TstNCmpltdLstClr 0 "FALSE" 1 "TRUE" ;
VAL_ 1845 DTCI_FOPM_TstFldOpCyc 0 "FALSE" 1 "TRUE" ;
VAL_ 1845 DTCI_FOPM_TstFldLstClr 0 "FALSE" 1 "TRUE" ;
VAL_ 1845 DTCI_FOPM_TstFld 0 "FALSE" 1 "TRUE" ;
VAL_ 1845 DTCI_FOPM_PndngDTC 0 "FALSE" 1 "TRUE" ;
VAL_ 1845 DTCI_FOPM_DTCTriggered 0 "FALSE" 1 "TRUE" ;
VAL_ 1845 DTCI_FOPM_WrnIndTrggrd 0 "FALSE" 1 "TRUE" ;
VAL_ 1845 DTCI_FOPM_WrnIndRqd 0 "FALSE" 1 "TRUE" ;
VAL_ 1355 DTCI_FPI_CnfrmdDTC 0 "FALSE" 1 "TRUE" ;
VAL_ 1355 DTCI_FPI_DTCFaultType 0 "Not Supported" 1 "Type A" 2 "Type B" 3 "Type C" ;
VAL_ 1355 DTCI_FPI_TstNCmpltdOpCyc 0 "FALSE" 1 "TRUE" ;
VAL_ 1355 DTCI_FPI_TstNCmpltdLstClr 0 "FALSE" 1 "TRUE" ;
VAL_ 1355 DTCI_FPI_TstFldOpCyc 0 "FALSE" 1 "TRUE" ;
VAL_ 1355 DTCI_FPI_TstFldLstClr 0 "FALSE" 1 "TRUE" ;
VAL_ 1355 DTCI_FPI_TstFld 0 "FALSE" 1 "TRUE" ;
VAL_ 1355 DTCI_FPI_PndngDTC 0 "FALSE" 1 "TRUE" ;
VAL_ 1355 DTCI_FPI_DTCTriggered 0 "FALSE" 1 "TRUE" ;
VAL_ 1355 DTCI_FPI_WrnIndTrggrd 0 "FALSE" 1 "TRUE" ;
VAL_ 1355 DTCI_FPI_WrnIndRqd 0 "FALSE" 1 "TRUE" ;
VAL_ 1220 DTCI_HDLM_CnfrmdDTC 0 "FALSE" 1 "TRUE" ;
VAL_ 1220 DTCI_HDLM_DTCFaultType 0 "Not Supported" 1 "Type A" 2 "Type B" 3 "Type C" ;
VAL_ 1220 DTCI_HDLM_TstNCmpltdOpCyc 0 "FALSE" 1 "TRUE" ;
VAL_ 1220 DTCI_HDLM_TstNCmpltdLstClr 0 "FALSE" 1 "TRUE" ;
VAL_ 1220 DTCI_HDLM_TstFldOpCyc 0 "FALSE" 1 "TRUE" ;
VAL_ 1220 DTCI_HDLM_TstFldLstClr 0 "FALSE" 1 "TRUE" ;
VAL_ 1220 DTCI_HDLM_TstFld 0 "FALSE" 1 "TRUE" ;
VAL_ 1220 DTCI_HDLM_PndngDTC 0 "FALSE" 1 "TRUE" ;
VAL_ 1220 DTCI_HDLM_DTCTriggered 0 "FALSE" 1 "TRUE" ;
VAL_ 1220 DTCI_HDLM_WrnIndTrggrd 0 "FALSE" 1 "TRUE" ;
VAL_ 1220 DTCI_HDLM_WrnIndRqd 0 "FALSE" 1 "TRUE" ;
VAL_ 1846 DTCI_HUD_CAN_CnfrmdDTC 0 "FALSE" 1 "TRUE" ;
VAL_ 1846 DTCI_HUD_CAN_DTCFaultType 0 "Not Supported" 1 "Type A" 2 "Type B" 3 "Type C" ;
VAL_ 1846 DTCI_HUD_CAN_TstNCmpltdOpCyc 0 "FALSE" 1 "TRUE" ;
VAL_ 1846 DTCI_HUD_CAN_TstNCmpltdLstClr 0 "FALSE" 1 "TRUE" ;
VAL_ 1846 DTCI_HUD_CAN_TstFldOpCyc 0 "FALSE" 1 "TRUE" ;
VAL_ 1846 DTCI_HUD_CAN_TstFldLstClr 0 "FALSE" 1 "TRUE" ;
VAL_ 1846 DTCI_HUD_CAN_TstFld 0 "FALSE" 1 "TRUE" ;
VAL_ 1846 DTCI_HUD_CAN_PndngDTC 0 "FALSE" 1 "TRUE" ;
VAL_ 1846 DTCI_HUD_CAN_DTCTriggered 0 "FALSE" 1 "TRUE" ;
VAL_ 1846 DTCI_HUD_CAN_WrnIndTrggrd 0 "FALSE" 1 "TRUE" ;
VAL_ 1846 DTCI_HUD_CAN_WrnIndRqd 0 "FALSE" 1 "TRUE" ;
